VERSION "HNPBNYYYYYYYYYYYYYYYYYYYYYYYYYYYNNNNNNNNNN/4/%%/4/'%**4NNN///"

NS_ :

BS_:

BU_: ADL Aux_Device CANLogger CTU Central CentralMulti OffboardUDS Predecessor_Node RDC Radar SensorCANopen Simulator TEPM TIM TPMS iTEPM

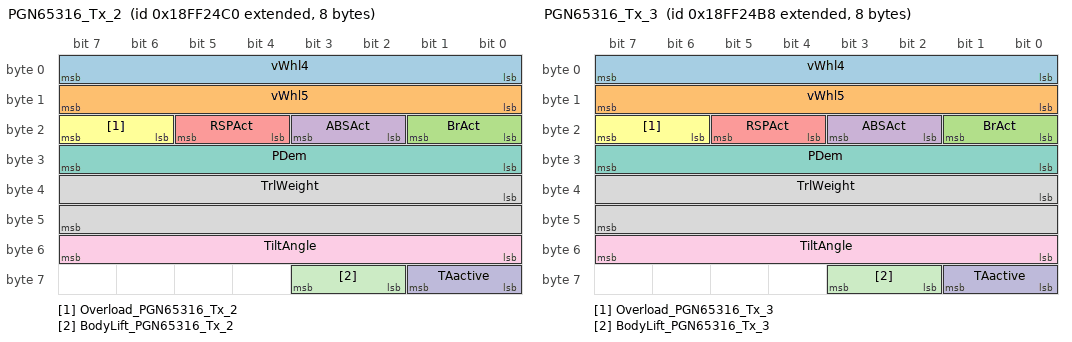
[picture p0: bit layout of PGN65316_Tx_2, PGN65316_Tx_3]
BO_ 2566857920 PGN65316_Tx_2 :8 CentralMulti
 SG_ vWhl4 : 0|8@1+ (1,0) [0|255] "km/h" Vector__XXX
 SG_ vWhl5 : 8|8@1+ (1,0) [0|255] "km/h" Vector__XXX
 SG_ BrAct : 16|2@1+ (1,0) [0|3] "" Vector__XXX
 SG_ ABSAct : 18|2@1+ (1,0) [0|3] "" Vector__XXX
 SG_ RSPAct : 20|2@1+ (1,0) [0|3] "" Vector__XXX
 SG_ Overload_PGN65316_Tx_2 : 22|2@1+ (1,0) [0|3] "" Vector__XXX
 SG_ PDem : 24|8@1+ (100,0) [0|255] "mbar" Vector__XXX
 SG_ TrlWeight : 32|16@1+ (2,0) [0|65535] "kg" Vector__XXX
 SG_ TiltAngle : 48|8@1+ (0.1,0) [0|255] "deg" Vector__XXX
 SG_ TAactive : 56|2@1+ (1,0) [0|3] "" Vector__XXX
 SG_ BodyLift_PGN65316_Tx_2 : 58|2@1+ (1,0) [0|3] "" Vector__XXX

BO_ 2566857912 PGN65316_Tx_3 :8 CentralMulti
 SG_ vWhl4 : 0|8@1+ (1,0) [0|255] "km/h" Vector__XXX
 SG_ vWhl5 : 8|8@1+ (1,0) [0|255] "km/h" Vector__XXX
 SG_ BrAct : 16|2@1+ (1,0) [0|3] "" Vector__XXX
 SG_ ABSAct : 18|2@1+ (1,0) [0|3] "" Vector__XXX
 SG_ RSPAct : 20|2@1+ (1,0) [0|3] "" Vector__XXX
 SG_ Overload_PGN65316_Tx_3 : 22|2@1+ (1,0) [0|3] "" Vector__XXX
 SG_ PDem : 24|8@1+ (100,0) [0|255] "mbar" Vector__XXX
 SG_ TrlWeight : 32|16@1+ (2,0) [0|65535] "kg" Vector__XXX
 SG_ TiltAngle : 48|8@1+ (0.1,0) [0|255] "deg" Vector__XXX
 SG_ TAactive : 56|2@1+ (1,0) [0|3] "" Vector__XXX
 SG_ BodyLift_PGN65316_Tx_3 : 58|2@1+ (1,0) [0|3] "" Vector__XXX

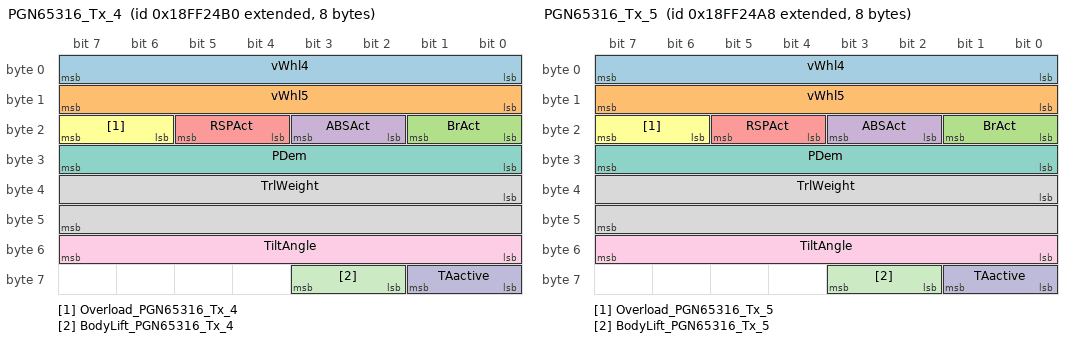
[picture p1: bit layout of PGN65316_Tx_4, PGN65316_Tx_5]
BO_ 2566857904 PGN65316_Tx_4 :8 CentralMulti
 SG_ vWhl4 : 0|8@1+ (1,0) [0|255] "km/h" Vector__XXX
 SG_ vWhl5 : 8|8@1+ (1,0) [0|255] "km/h" Vector__XXX
 SG_ BrAct : 16|2@1+ (1,0) [0|3] "" Vector__XXX
 SG_ ABSAct : 18|2@1+ (1,0) [0|3] "" Vector__XXX
 SG_ RSPAct : 20|2@1+ (1,0) [0|3] "" Vector__XXX
 SG_ Overload_PGN65316_Tx_4 : 22|2@1+ (1,0) [0|3] "" Vector__XXX
 SG_ PDem : 24|8@1+ (100,0) [0|255] "mbar" Vector__XXX
 SG_ TrlWeight : 32|16@1+ (2,0) [0|65535] "kg" Vector__XXX
 SG_ TiltAngle : 48|8@1+ (0.1,0) [0|255] "deg" Vector__XXX
 SG_ TAactive : 56|2@1+ (1,0) [0|3] "" Vector__XXX
 SG_ BodyLift_PGN65316_Tx_4 : 58|2@1+ (1,0) [0|3] "" Vector__XXX

BO_ 2566857896 PGN65316_Tx_5 :8 CentralMulti
 SG_ vWhl4 : 0|8@1+ (1,0) [0|255] "km/h" Vector__XXX
 SG_ vWhl5 : 8|8@1+ (1,0) [0|255] "km/h" Vector__XXX
 SG_ BrAct : 16|2@1+ (1,0) [0|3] "" Vector__XXX
 SG_ ABSAct : 18|2@1+ (1,0) [0|3] "" Vector__XXX
 SG_ RSPAct : 20|2@1+ (1,0) [0|3] "" Vector__XXX
 SG_ Overload_PGN65316_Tx_5 : 22|2@1+ (1,0) [0|3] "" Vector__XXX
 SG_ PDem : 24|8@1+ (100,0) [0|255] "mbar" Vector__XXX
 SG_ TrlWeight : 32|16@1+ (2,0) [0|65535] "kg" Vector__XXX
 SG_ TiltAngle : 48|8@1+ (0.1,0) [0|255] "deg" Vector__XXX
 SG_ TAactive : 56|2@1+ (1,0) [0|3] "" Vector__XXX
 SG_ BodyLift_PGN65316_Tx_5 : 58|2@1+ (1,0) [0|3] "" Vector__XXX

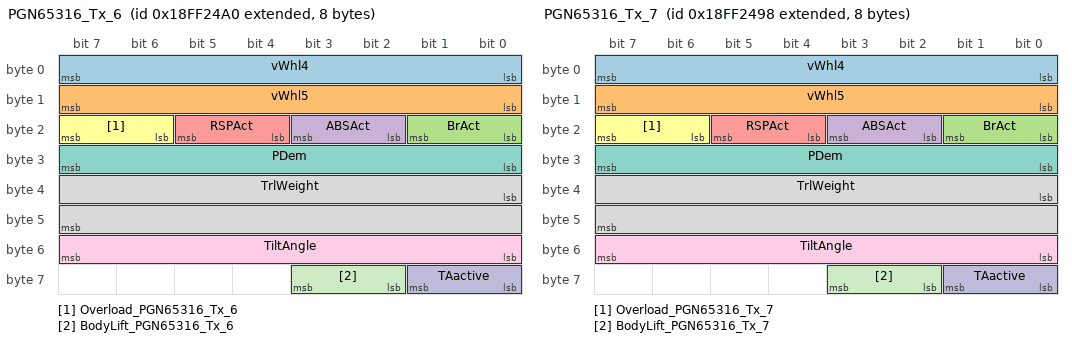
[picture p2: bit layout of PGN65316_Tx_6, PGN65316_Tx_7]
BO_ 2566857888 PGN65316_Tx_6 :8 CentralMulti
 SG_ vWhl4 : 0|8@1+ (1,0) [0|255] "km/h" Vector__XXX
 SG_ vWhl5 : 8|8@1+ (1,0) [0|255] "km/h" Vector__XXX
 SG_ BrAct : 16|2@1+ (1,0) [0|3] "" Vector__XXX
 SG_ ABSAct : 18|2@1+ (1,0) [0|3] "" Vector__XXX
 SG_ RSPAct : 20|2@1+ (1,0) [0|3] "" Vector__XXX
 SG_ Overload_PGN65316_Tx_6 : 22|2@1+ (1,0) [0|3] "" Vector__XXX
 SG_ PDem : 24|8@1+ (100,0) [0|255] "mbar" Vector__XXX
 SG_ TrlWeight : 32|16@1+ (2,0) [0|65535] "kg" Vector__XXX
 SG_ TiltAngle : 48|8@1+ (0.1,0) [0|255] "deg" Vector__XXX
 SG_ TAactive : 56|2@1+ (1,0) [0|3] "" Vector__XXX
 SG_ BodyLift_PGN65316_Tx_6 : 58|2@1+ (1,0) [0|3] "" Vector__XXX

BO_ 2566857880 PGN65316_Tx_7 :8 CentralMulti
 SG_ vWhl4 : 0|8@1+ (1,0) [0|255] "km/h" Vector__XXX
 SG_ vWhl5 : 8|8@1+ (1,0) [0|255] "km/h" Vector__XXX
 SG_ BrAct : 16|2@1+ (1,0) [0|3] "" Vector__XXX
 SG_ ABSAct : 18|2@1+ (1,0) [0|3] "" Vector__XXX
 SG_ RSPAct : 20|2@1+ (1,0) [0|3] "" Vector__XXX
 SG_ Overload_PGN65316_Tx_7 : 22|2@1+ (1,0) [0|3] "" Vector__XXX
 SG_ PDem : 24|8@1+ (100,0) [0|255] "mbar" Vector__XXX
 SG_ TrlWeight : 32|16@1+ (2,0) [0|65535] "kg" Vector__XXX
 SG_ TiltAngle : 48|8@1+ (0.1,0) [0|255] "deg" Vector__XXX
 SG_ TAactive : 56|2@1+ (1,0) [0|3] "" Vector__XXX
 SG_ BodyLift_PGN65316_Tx_7 : 58|2@1+ (1,0) [0|3] "" Vector__XXX

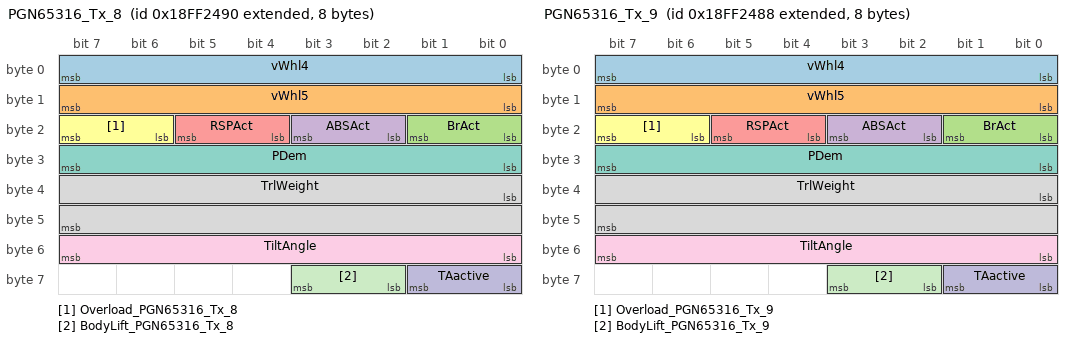
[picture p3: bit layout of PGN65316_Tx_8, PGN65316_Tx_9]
BO_ 2566857872 PGN65316_Tx_8 :8 CentralMulti
 SG_ vWhl4 : 0|8@1+ (1,0) [0|255] "km/h" Vector__XXX
 SG_ vWhl5 : 8|8@1+ (1,0) [0|255] "km/h" Vector__XXX
 SG_ BrAct : 16|2@1+ (1,0) [0|3] "" Vector__XXX
 SG_ ABSAct : 18|2@1+ (1,0) [0|3] "" Vector__XXX
 SG_ RSPAct : 20|2@1+ (1,0) [0|3] "" Vector__XXX
 SG_ Overload_PGN65316_Tx_8 : 22|2@1+ (1,0) [0|3] "" Vector__XXX
 SG_ PDem : 24|8@1+ (100,0) [0|255] "mbar" Vector__XXX
 SG_ TrlWeight : 32|16@1+ (2,0) [0|65535] "kg" Vector__XXX
 SG_ TiltAngle : 48|8@1+ (0.1,0) [0|255] "deg" Vector__XXX
 SG_ TAactive : 56|2@1+ (1,0) [0|3] "" Vector__XXX
 SG_ BodyLift_PGN65316_Tx_8 : 58|2@1+ (1,0) [0|3] "" Vector__XXX

BO_ 2566857864 PGN65316_Tx_9 :8 CentralMulti
 SG_ vWhl4 : 0|8@1+ (1,0) [0|255] "km/h" Vector__XXX
 SG_ vWhl5 : 8|8@1+ (1,0) [0|255] "km/h" Vector__XXX
 SG_ BrAct : 16|2@1+ (1,0) [0|3] "" Vector__XXX
 SG_ ABSAct : 18|2@1+ (1,0) [0|3] "" Vector__XXX
 SG_ RSPAct : 20|2@1+ (1,0) [0|3] "" Vector__XXX
 SG_ Overload_PGN65316_Tx_9 : 22|2@1+ (1,0) [0|3] "" Vector__XXX
 SG_ PDem : 24|8@1+ (100,0) [0|255] "mbar" Vector__XXX
 SG_ TrlWeight : 32|16@1+ (2,0) [0|65535] "kg" Vector__XXX
 SG_ TiltAngle : 48|8@1+ (0.1,0) [0|255] "deg" Vector__XXX
 SG_ TAactive : 56|2@1+ (1,0) [0|3] "" Vector__XXX
 SG_ BodyLift_PGN65316_Tx_9 : 58|2@1+ (1,0) [0|3] "" Vector__XXX

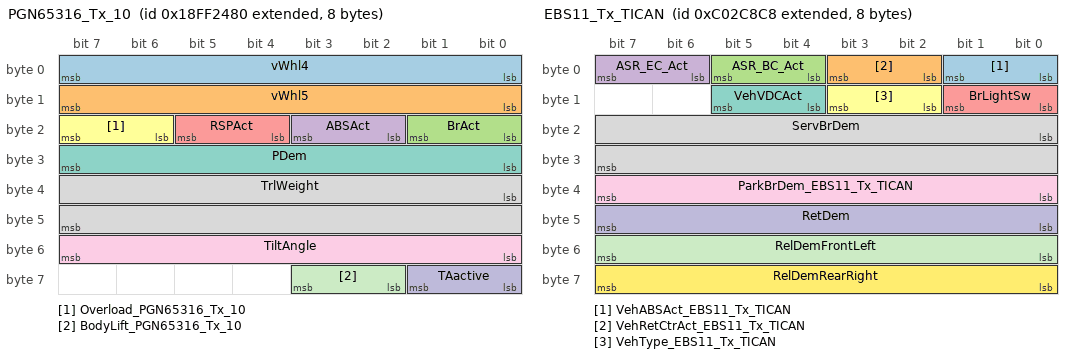
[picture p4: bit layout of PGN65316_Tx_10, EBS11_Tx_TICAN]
BO_ 2566857856 PGN65316_Tx_10 :8 CentralMulti
 SG_ vWhl4 : 0|8@1+ (1,0) [0|255] "km/h" Vector__XXX
 SG_ vWhl5 : 8|8@1+ (1,0) [0|255] "km/h" Vector__XXX
 SG_ BrAct : 16|2@1+ (1,0) [0|3] "" Vector__XXX
 SG_ ABSAct : 18|2@1+ (1,0) [0|3] "" Vector__XXX
 SG_ RSPAct : 20|2@1+ (1,0) [0|3] "" Vector__XXX
 SG_ Overload_PGN65316_Tx_10 : 22|2@1+ (1,0) [0|3] "" Vector__XXX
 SG_ PDem : 24|8@1+ (100,0) [0|255] "mbar" Vector__XXX
 SG_ TrlWeight : 32|16@1+ (2,0) [0|65535] "kg" Vector__XXX
 SG_ TiltAngle : 48|8@1+ (0.1,0) [0|255] "deg" Vector__XXX
 SG_ TAactive : 56|2@1+ (1,0) [0|3] "" Vector__XXX
 SG_ BodyLift_PGN65316_Tx_10 : 58|2@1+ (1,0) [0|3] "" Vector__XXX

BO_ 2348992712 EBS11_Tx_TICAN :8 Central
 SG_ VehABSAct_EBS11_Tx_TICAN : 0|2@1+ (1,0) [0|3] "" Vector__XXX
 SG_ VehRetCtrAct_EBS11_Tx_TICAN : 2|2@1+ (1,0) [0|3] "" Vector__XXX
 SG_ ASR_BC_Act : 4|2@1+ (1,0) [0|3] "" Vector__XXX
 SG_ ASR_EC_Act : 6|2@1+ (1,0) [0|3] "" Vector__XXX
 SG_ BrLightSw : 8|2@1+ (1,0) [0|3] "" Vector__XXX
 SG_ VehType_EBS11_Tx_TICAN : 10|2@1+ (1,0) [0|3] "" Vector__XXX
 SG_ VehVDCAct : 12|2@1+ (1,0) [0|3] "" Vector__XXX
 SG_ ServBrDem : 16|16@1+ (0.01953125,0) [0|65535] "kPa" Vector__XXX
 SG_ ParkBrDem_EBS11_Tx_TICAN : 32|8@1+ (0.4,0) [0|255] "%" Vector__XXX
 SG_ RetDem : 40|8@1+ (1,0) [0|255] "%" Vector__XXX
 SG_ RelDemFrontLeft : 48|8@1+ (0.4,0) [0|255] "%" Vector__XXX
 SG_ RelDemRearRight : 56|8@1+ (0.4,0) [0|255] "%" Vector__XXX

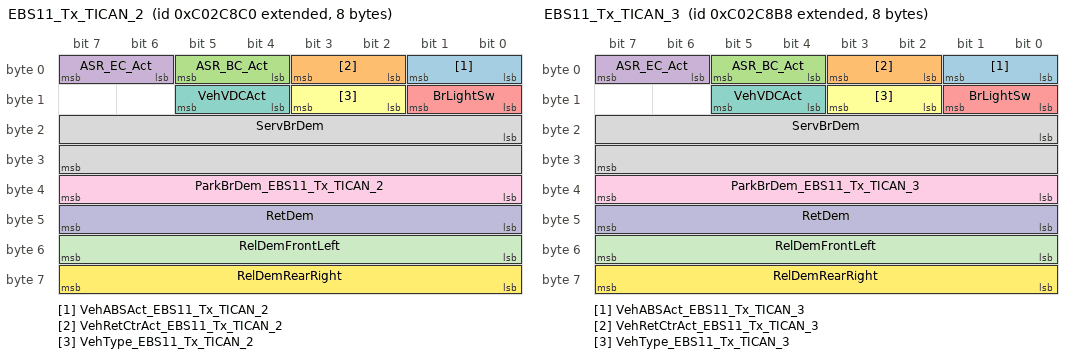
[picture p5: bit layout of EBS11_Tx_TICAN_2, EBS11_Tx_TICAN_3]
BO_ 2348992704 EBS11_Tx_TICAN_2 :8 CentralMulti
 SG_ VehABSAct_EBS11_Tx_TICAN_2 : 0|2@1+ (1,0) [0|3] "" Vector__XXX
 SG_ VehRetCtrAct_EBS11_Tx_TICAN_2 : 2|2@1+ (1,0) [0|3] "" Vector__XXX
 SG_ ASR_BC_Act : 4|2@1+ (1,0) [0|3] "" Vector__XXX
 SG_ ASR_EC_Act : 6|2@1+ (1,0) [0|3] "" Vector__XXX
 SG_ BrLightSw : 8|2@1+ (1,0) [0|3] "" Vector__XXX
 SG_ VehType_EBS11_Tx_TICAN_2 : 10|2@1+ (1,0) [0|3] "" Vector__XXX
 SG_ VehVDCAct : 12|2@1+ (1,0) [0|3] "" Vector__XXX
 SG_ ServBrDem : 16|16@1+ (0.01953125,0) [0|65535] "kPa" Vector__XXX
 SG_ ParkBrDem_EBS11_Tx_TICAN_2 : 32|8@1+ (0.4,0) [0|255] "%" Vector__XXX
 SG_ RetDem : 40|8@1+ (1,0) [0|255] "%" Vector__XXX
 SG_ RelDemFrontLeft : 48|8@1+ (0.4,0) [0|255] "%" Vector__XXX
 SG_ RelDemRearRight : 56|8@1+ (0.4,0) [0|255] "%" Vector__XXX

BO_ 2348992696 EBS11_Tx_TICAN_3 :8 CentralMulti
 SG_ VehABSAct_EBS11_Tx_TICAN_3 : 0|2@1+ (1,0) [0|3] "" Vector__XXX
 SG_ VehRetCtrAct_EBS11_Tx_TICAN_3 : 2|2@1+ (1,0) [0|3] "" Vector__XXX
 SG_ ASR_BC_Act : 4|2@1+ (1,0) [0|3] "" Vector__XXX
 SG_ ASR_EC_Act : 6|2@1+ (1,0) [0|3] "" Vector__XXX
 SG_ BrLightSw : 8|2@1+ (1,0) [0|3] "" Vector__XXX
 SG_ VehType_EBS11_Tx_TICAN_3 : 10|2@1+ (1,0) [0|3] "" Vector__XXX
 SG_ VehVDCAct : 12|2@1+ (1,0) [0|3] "" Vector__XXX
 SG_ ServBrDem : 16|16@1+ (0.01953125,0) [0|65535] "kPa" Vector__XXX
 SG_ ParkBrDem_EBS11_Tx_TICAN_3 : 32|8@1+ (0.4,0) [0|255] "%" Vector__XXX
 SG_ RetDem : 40|8@1+ (1,0) [0|255] "%" Vector__XXX
 SG_ RelDemFrontLeft : 48|8@1+ (0.4,0) [0|255] "%" Vector__XXX
 SG_ RelDemRearRight : 56|8@1+ (0.4,0) [0|255] "%" Vector__XXX

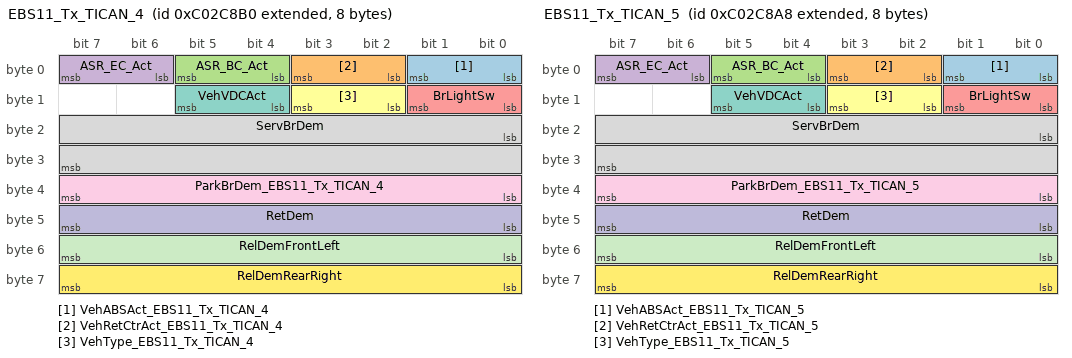
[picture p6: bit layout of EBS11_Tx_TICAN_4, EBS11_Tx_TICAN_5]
BO_ 2348992688 EBS11_Tx_TICAN_4 :8 CentralMulti
 SG_ VehABSAct_EBS11_Tx_TICAN_4 : 0|2@1+ (1,0) [0|3] "" Vector__XXX
 SG_ VehRetCtrAct_EBS11_Tx_TICAN_4 : 2|2@1+ (1,0) [0|3] "" Vector__XXX
 SG_ ASR_BC_Act : 4|2@1+ (1,0) [0|3] "" Vector__XXX
 SG_ ASR_EC_Act : 6|2@1+ (1,0) [0|3] "" Vector__XXX
 SG_ BrLightSw : 8|2@1+ (1,0) [0|3] "" Vector__XXX
 SG_ VehType_EBS11_Tx_TICAN_4 : 10|2@1+ (1,0) [0|3] "" Vector__XXX
 SG_ VehVDCAct : 12|2@1+ (1,0) [0|3] "" Vector__XXX
 SG_ ServBrDem : 16|16@1+ (0.01953125,0) [0|65535] "kPa" Vector__XXX
 SG_ ParkBrDem_EBS11_Tx_TICAN_4 : 32|8@1+ (0.4,0) [0|255] "%" Vector__XXX
 SG_ RetDem : 40|8@1+ (1,0) [0|255] "%" Vector__XXX
 SG_ RelDemFrontLeft : 48|8@1+ (0.4,0) [0|255] "%" Vector__XXX
 SG_ RelDemRearRight : 56|8@1+ (0.4,0) [0|255] "%" Vector__XXX

BO_ 2348992680 EBS11_Tx_TICAN_5 :8 CentralMulti
 SG_ VehABSAct_EBS11_Tx_TICAN_5 : 0|2@1+ (1,0) [0|3] "" Vector__XXX
 SG_ VehRetCtrAct_EBS11_Tx_TICAN_5 : 2|2@1+ (1,0) [0|3] "" Vector__XXX
 SG_ ASR_BC_Act : 4|2@1+ (1,0) [0|3] "" Vector__XXX
 SG_ ASR_EC_Act : 6|2@1+ (1,0) [0|3] "" Vector__XXX
 SG_ BrLightSw : 8|2@1+ (1,0) [0|3] "" Vector__XXX
 SG_ VehType_EBS11_Tx_TICAN_5 : 10|2@1+ (1,0) [0|3] "" Vector__XXX
 SG_ VehVDCAct : 12|2@1+ (1,0) [0|3] "" Vector__XXX
 SG_ ServBrDem : 16|16@1+ (0.01953125,0) [0|65535] "kPa" Vector__XXX
 SG_ ParkBrDem_EBS11_Tx_TICAN_5 : 32|8@1+ (0.4,0) [0|255] "%" Vector__XXX
 SG_ RetDem : 40|8@1+ (1,0) [0|255] "%" Vector__XXX
 SG_ RelDemFrontLeft : 48|8@1+ (0.4,0) [0|255] "%" Vector__XXX
 SG_ RelDemRearRight : 56|8@1+ (0.4,0) [0|255] "%" Vector__XXX

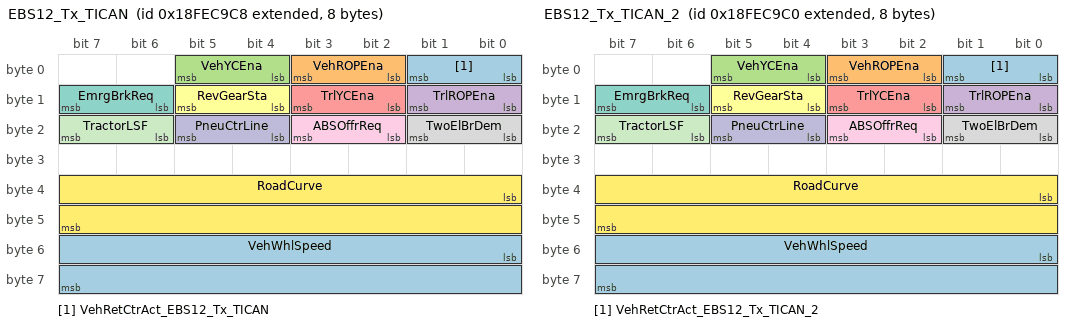
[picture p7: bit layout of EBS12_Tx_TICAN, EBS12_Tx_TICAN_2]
BO_ 2566834632 EBS12_Tx_TICAN :8 Central
 SG_ VehRetCtrAct_EBS12_Tx_TICAN : 0|2@1+ (1,0) [0|3] "" Vector__XXX
 SG_ VehROPEna : 2|2@1+ (1,0) [0|3] "" Vector__XXX
 SG_ VehYCEna : 4|2@1+ (1,0) [0|3] "" Vector__XXX
 SG_ TrlROPEna : 8|2@1+ (1,0) [0|3] "" Vector__XXX
 SG_ TrlYCEna : 10|2@1+ (1,0) [0|3] "" Vector__XXX
 SG_ RevGearSta : 12|2@1+ (1,0) [0|3] "" Vector__XXX
 SG_ EmrgBrkReq : 14|2@1+ (1,0) [0|3] "" Vector__XXX
 SG_ TwoElBrDem : 16|2@1+ (1,0) [0|3] "" Vector__XXX
 SG_ ABSOffrReq : 18|2@1+ (1,0) [0|3] "" Vector__XXX
 SG_ PneuCtrLine : 20|2@1+ (1,0) [0|3] "" Vector__XXX
 SG_ TractorLSF : 22|2@1+ (1,0) [0|3] "" Vector__XXX
 SG_ RoadCurve : 32|16@1+ (0.0078125,-250) [0|65535] "1/km" Vector__XXX
 SG_ VehWhlSpeed : 48|16@1+ (0.00390625,0) [0|65535] "km/h" Vector__XXX

BO_ 2566834624 EBS12_Tx_TICAN_2 :8 CentralMulti
 SG_ VehRetCtrAct_EBS12_Tx_TICAN_2 : 0|2@1+ (1,0) [0|3] "" Vector__XXX
 SG_ VehROPEna : 2|2@1+ (1,0) [0|3] "" Vector__XXX
 SG_ VehYCEna : 4|2@1+ (1,0) [0|3] "" Vector__XXX
 SG_ TrlROPEna : 8|2@1+ (1,0) [0|3] "" Vector__XXX
 SG_ TrlYCEna : 10|2@1+ (1,0) [0|3] "" Vector__XXX
 SG_ RevGearSta : 12|2@1+ (1,0) [0|3] "" Vector__XXX
 SG_ EmrgBrkReq : 14|2@1+ (1,0) [0|3] "" Vector__XXX
 SG_ TwoElBrDem : 16|2@1+ (1,0) [0|3] "" Vector__XXX
 SG_ ABSOffrReq : 18|2@1+ (1,0) [0|3] "" Vector__XXX
 SG_ PneuCtrLine : 20|2@1+ (1,0) [0|3] "" Vector__XXX
 SG_ TractorLSF : 22|2@1+ (1,0) [0|3] "" Vector__XXX
 SG_ RoadCurve : 32|16@1+ (0.0078125,-250) [0|65535] "1/km" Vector__XXX
 SG_ VehWhlSpeed : 48|16@1+ (0.00390625,0) [0|65535] "km/h" Vector__XXX

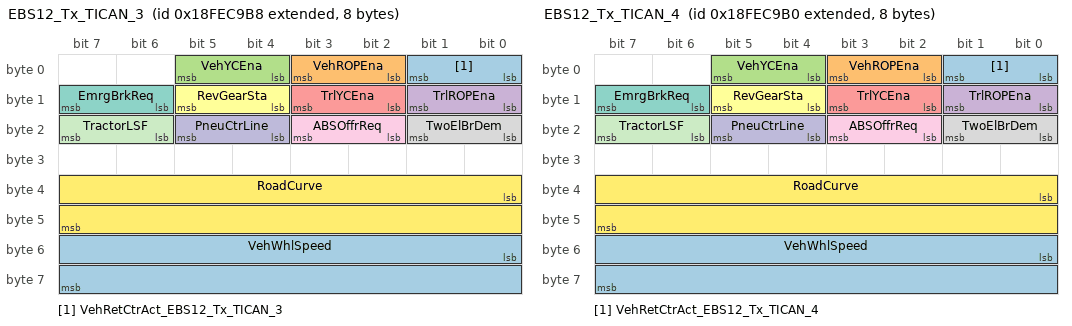
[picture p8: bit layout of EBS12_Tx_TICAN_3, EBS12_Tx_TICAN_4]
BO_ 2566834616 EBS12_Tx_TICAN_3 :8 CentralMulti
 SG_ VehRetCtrAct_EBS12_Tx_TICAN_3 : 0|2@1+ (1,0) [0|3] "" Vector__XXX
 SG_ VehROPEna : 2|2@1+ (1,0) [0|3] "" Vector__XXX
 SG_ VehYCEna : 4|2@1+ (1,0) [0|3] "" Vector__XXX
 SG_ TrlROPEna : 8|2@1+ (1,0) [0|3] "" Vector__XXX
 SG_ TrlYCEna : 10|2@1+ (1,0) [0|3] "" Vector__XXX
 SG_ RevGearSta : 12|2@1+ (1,0) [0|3] "" Vector__XXX
 SG_ EmrgBrkReq : 14|2@1+ (1,0) [0|3] "" Vector__XXX
 SG_ TwoElBrDem : 16|2@1+ (1,0) [0|3] "" Vector__XXX
 SG_ ABSOffrReq : 18|2@1+ (1,0) [0|3] "" Vector__XXX
 SG_ PneuCtrLine : 20|2@1+ (1,0) [0|3] "" Vector__XXX
 SG_ TractorLSF : 22|2@1+ (1,0) [0|3] "" Vector__XXX
 SG_ RoadCurve : 32|16@1+ (0.0078125,-250) [0|65535] "1/km" Vector__XXX
 SG_ VehWhlSpeed : 48|16@1+ (0.00390625,0) [0|65535] "km/h" Vector__XXX

BO_ 2566834608 EBS12_Tx_TICAN_4 :8 CentralMulti
 SG_ VehRetCtrAct_EBS12_Tx_TICAN_4 : 0|2@1+ (1,0) [0|3] "" Vector__XXX
 SG_ VehROPEna : 2|2@1+ (1,0) [0|3] "" Vector__XXX
 SG_ VehYCEna : 4|2@1+ (1,0) [0|3] "" Vector__XXX
 SG_ TrlROPEna : 8|2@1+ (1,0) [0|3] "" Vector__XXX
 SG_ TrlYCEna : 10|2@1+ (1,0) [0|3] "" Vector__XXX
 SG_ RevGearSta : 12|2@1+ (1,0) [0|3] "" Vector__XXX
 SG_ EmrgBrkReq : 14|2@1+ (1,0) [0|3] "" Vector__XXX
 SG_ TwoElBrDem : 16|2@1+ (1,0) [0|3] "" Vector__XXX
 SG_ ABSOffrReq : 18|2@1+ (1,0) [0|3] "" Vector__XXX
 SG_ PneuCtrLine : 20|2@1+ (1,0) [0|3] "" Vector__XXX
 SG_ TractorLSF : 22|2@1+ (1,0) [0|3] "" Vector__XXX
 SG_ RoadCurve : 32|16@1+ (0.0078125,-250) [0|65535] "1/km" Vector__XXX
 SG_ VehWhlSpeed : 48|16@1+ (0.00390625,0) [0|65535] "km/h" Vector__XXX

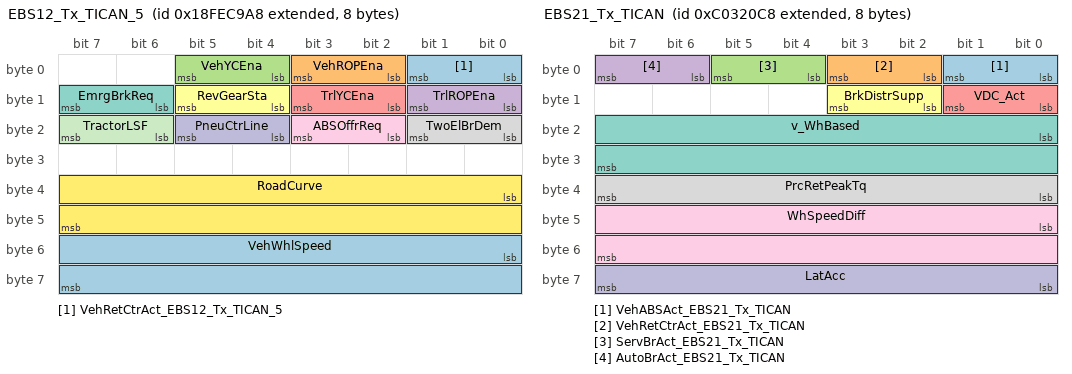
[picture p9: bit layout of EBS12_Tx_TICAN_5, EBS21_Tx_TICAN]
BO_ 2566834600 EBS12_Tx_TICAN_5 :8 CentralMulti
 SG_ VehRetCtrAct_EBS12_Tx_TICAN_5 : 0|2@1+ (1,0) [0|3] "" Vector__XXX
 SG_ VehROPEna : 2|2@1+ (1,0) [0|3] "" Vector__XXX
 SG_ VehYCEna : 4|2@1+ (1,0) [0|3] "" Vector__XXX
 SG_ TrlROPEna : 8|2@1+ (1,0) [0|3] "" Vector__XXX
 SG_ TrlYCEna : 10|2@1+ (1,0) [0|3] "" Vector__XXX
 SG_ RevGearSta : 12|2@1+ (1,0) [0|3] "" Vector__XXX
 SG_ EmrgBrkReq : 14|2@1+ (1,0) [0|3] "" Vector__XXX
 SG_ TwoElBrDem : 16|2@1+ (1,0) [0|3] "" Vector__XXX
 SG_ ABSOffrReq : 18|2@1+ (1,0) [0|3] "" Vector__XXX
 SG_ PneuCtrLine : 20|2@1+ (1,0) [0|3] "" Vector__XXX
 SG_ TractorLSF : 22|2@1+ (1,0) [0|3] "" Vector__XXX
 SG_ RoadCurve : 32|16@1+ (0.0078125,-250) [0|65535] "1/km" Vector__XXX
 SG_ VehWhlSpeed : 48|16@1+ (0.00390625,0) [0|65535] "km/h" Vector__XXX

BO_ 2349015240 EBS21_Tx_TICAN :8 Central
 SG_ VehABSAct_EBS21_Tx_TICAN : 0|2@1+ (1,0) [0|3] "" Vector__XXX
 SG_ VehRetCtrAct_EBS21_Tx_TICAN : 2|2@1+ (1,0) [0|3] "" Vector__XXX
 SG_ ServBrAct_EBS21_Tx_TICAN : 4|2@1+ (1,0) [0|3] "" Vector__XXX
 SG_ AutoBrAct_EBS21_Tx_TICAN : 6|2@1+ (1,0) [0|3] "" Vector__XXX
 SG_ VDC_Act : 8|2@1+ (1,0) [0|3] "" Vector__XXX
 SG_ BrkDistrSupp : 10|2@1+ (1,0) [0|3] "" Vector__XXX
 SG_ v_WhBased : 16|16@1+ (0.00390625,0) [0|65535] "km/h" Vector__XXX
 SG_ PrcRetPeakTq : 32|8@1+ (1,-125) [0|255] "%" Vector__XXX
 SG_ WhSpeedDiff : 40|16@1+ (0.00390625,-125) [0|65535] "km/h" Vector__XXX
 SG_ LatAcc : 56|8@1+ (0.1,-12.5) [0|255] "m/s2" Vector__XXX

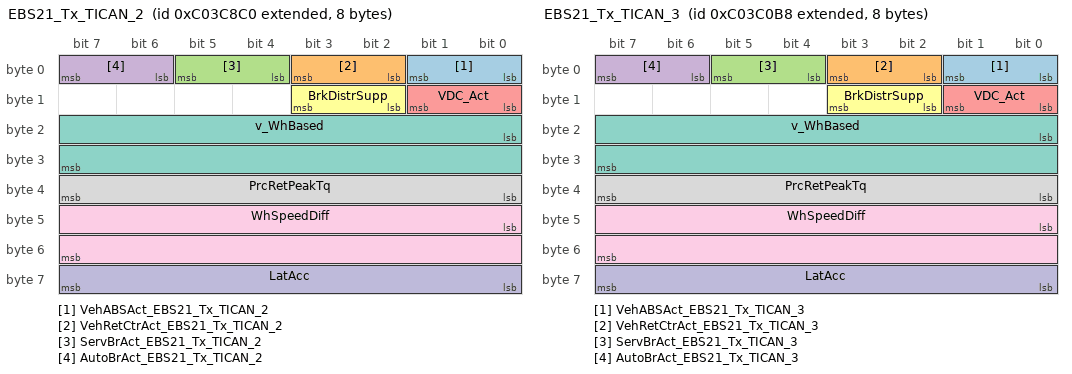
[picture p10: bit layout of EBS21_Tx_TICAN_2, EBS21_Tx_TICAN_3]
BO_ 2349058240 EBS21_Tx_TICAN_2 :8 CentralMulti
 SG_ VehABSAct_EBS21_Tx_TICAN_2 : 0|2@1+ (1,0) [0|3] "" Vector__XXX
 SG_ VehRetCtrAct_EBS21_Tx_TICAN_2 : 2|2@1+ (1,0) [0|3] "" Vector__XXX
 SG_ ServBrAct_EBS21_Tx_TICAN_2 : 4|2@1+ (1,0) [0|3] "" Vector__XXX
 SG_ AutoBrAct_EBS21_Tx_TICAN_2 : 6|2@1+ (1,0) [0|3] "" Vector__XXX
 SG_ VDC_Act : 8|2@1+ (1,0) [0|3] "" Vector__XXX
 SG_ BrkDistrSupp : 10|2@1+ (1,0) [0|3] "" Vector__XXX
 SG_ v_WhBased : 16|16@1+ (0.00390625,0) [0|65535] "km/h" Vector__XXX
 SG_ PrcRetPeakTq : 32|8@1+ (1,-125) [0|255] "%" Vector__XXX
 SG_ WhSpeedDiff : 40|16@1+ (0.00390625,-125) [0|65535] "km/h" Vector__XXX
 SG_ LatAcc : 56|8@1+ (0.1,-12.5) [0|255] "m/s2" Vector__XXX

BO_ 2349056184 EBS21_Tx_TICAN_3 :8 CentralMulti
 SG_ VehABSAct_EBS21_Tx_TICAN_3 : 0|2@1+ (1,0) [0|3] "" Vector__XXX
 SG_ VehRetCtrAct_EBS21_Tx_TICAN_3 : 2|2@1+ (1,0) [0|3] "" Vector__XXX
 SG_ ServBrAct_EBS21_Tx_TICAN_3 : 4|2@1+ (1,0) [0|3] "" Vector__XXX
 SG_ AutoBrAct_EBS21_Tx_TICAN_3 : 6|2@1+ (1,0) [0|3] "" Vector__XXX
 SG_ VDC_Act : 8|2@1+ (1,0) [0|3] "" Vector__XXX
 SG_ BrkDistrSupp : 10|2@1+ (1,0) [0|3] "" Vector__XXX
 SG_ v_WhBased : 16|16@1+ (0.00390625,0) [0|65535] "km/h" Vector__XXX
 SG_ PrcRetPeakTq : 32|8@1+ (1,-125) [0|255] "%" Vector__XXX
 SG_ WhSpeedDiff : 40|16@1+ (0.00390625,-125) [0|65535] "km/h" Vector__XXX
 SG_ LatAcc : 56|8@1+ (0.1,-12.5) [0|255] "m/s2" Vector__XXX

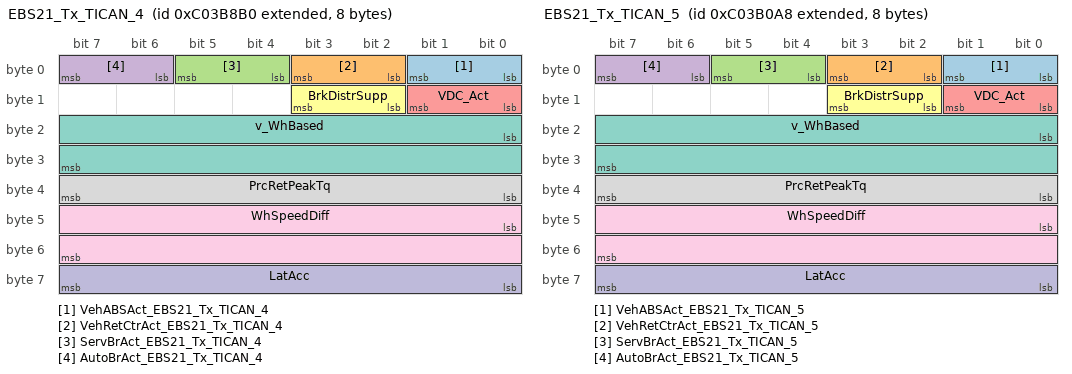
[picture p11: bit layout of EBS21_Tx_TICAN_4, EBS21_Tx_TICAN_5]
BO_ 2349054128 EBS21_Tx_TICAN_4 :8 CentralMulti
 SG_ VehABSAct_EBS21_Tx_TICAN_4 : 0|2@1+ (1,0) [0|3] "" Vector__XXX
 SG_ VehRetCtrAct_EBS21_Tx_TICAN_4 : 2|2@1+ (1,0) [0|3] "" Vector__XXX
 SG_ ServBrAct_EBS21_Tx_TICAN_4 : 4|2@1+ (1,0) [0|3] "" Vector__XXX
 SG_ AutoBrAct_EBS21_Tx_TICAN_4 : 6|2@1+ (1,0) [0|3] "" Vector__XXX
 SG_ VDC_Act : 8|2@1+ (1,0) [0|3] "" Vector__XXX
 SG_ BrkDistrSupp : 10|2@1+ (1,0) [0|3] "" Vector__XXX
 SG_ v_WhBased : 16|16@1+ (0.00390625,0) [0|65535] "km/h" Vector__XXX
 SG_ PrcRetPeakTq : 32|8@1+ (1,-125) [0|255] "%" Vector__XXX
 SG_ WhSpeedDiff : 40|16@1+ (0.00390625,-125) [0|65535] "km/h" Vector__XXX
 SG_ LatAcc : 56|8@1+ (0.1,-12.5) [0|255] "m/s2" Vector__XXX

BO_ 2349052072 EBS21_Tx_TICAN_5 :8 CentralMulti
 SG_ VehABSAct_EBS21_Tx_TICAN_5 : 0|2@1+ (1,0) [0|3] "" Vector__XXX
 SG_ VehRetCtrAct_EBS21_Tx_TICAN_5 : 2|2@1+ (1,0) [0|3] "" Vector__XXX
 SG_ ServBrAct_EBS21_Tx_TICAN_5 : 4|2@1+ (1,0) [0|3] "" Vector__XXX
 SG_ AutoBrAct_EBS21_Tx_TICAN_5 : 6|2@1+ (1,0) [0|3] "" Vector__XXX
 SG_ VDC_Act : 8|2@1+ (1,0) [0|3] "" Vector__XXX
 SG_ BrkDistrSupp : 10|2@1+ (1,0) [0|3] "" Vector__XXX
 SG_ v_WhBased : 16|16@1+ (0.00390625,0) [0|65535] "km/h" Vector__XXX
 SG_ PrcRetPeakTq : 32|8@1+ (1,-125) [0|255] "%" Vector__XXX
 SG_ WhSpeedDiff : 40|16@1+ (0.00390625,-125) [0|65535] "km/h" Vector__XXX
 SG_ LatAcc : 56|8@1+ (0.1,-12.5) [0|255] "m/s2" Vector__XXX

BO_ 2566833352 EBS22_Tx_TICAN :8 Central
 SG_ VehABSAct_EBS22_Tx_TICAN : 0|2@1+ (1,0) [0|3] "" Vector__XXX
 SG_ VehRetCtrAct_EBS22_Tx_TICAN : 2|2@1+ (1,0) [0|3] "" Vector__XXX
 SG_ ServBrAct_EBS22_Tx_TICAN : 4|2@1+ (1,0) [0|3] "" Vector__XXX
 SG_ AutoBrAct_EBS22_Tx_TICAN : 6|2@1+ (1,0) [0|3] "" Vector__XXX
 SG_ ElSupSuff : 8|2@1+ (1,0) [0|3] "" Vector__XXX
 SG_ RedWLReq : 10|2@1+ (1,0) [0|3] "" Vector__XXX
 SG_ AmbWLReq : 12|2@1+ (1,0) [0|3] "" Vector__XXX
 SG_ ElSupNoBrSys : 14|2@1+ (1,0) [0|3] "" Vector__XXX
 SG_ SpringBrInst : 16|2@1+ (1,0) [0|3] "" Vector__XXX
 SG_ ElLoadProp : 18|2@1+ (1,0) [0|3] "" Vector__XXX
 SG_ VehType_EBS22_Tx_TICAN : 20|2@1+ (1,0) [0|3] "" Vector__XXX
 SG_ SprBrEng : 22|2@1+ (1,0) [0|3] "" Vector__XXX
 SG_ LoadRampAss : 24|2@1+ (1,0) [0|3] "" Vector__XXX
 SG_ SupBrReq : 26|2@1+ (1,0) [0|3] "" Vector__XXX
 SG_ StopLampReq : 28|2@1+ (1,0) [0|3] "" Vector__XXX
 SG_ ElBrakeSupp : 30|2@1+ (1,0) [0|3] "" Vector__XXX
 SG_ AxLoadSum : 32|16@1+ (2,0) [0|65535] "kg" Vector__XXX
 SG_ RefRetTrq : 48|16@1+ (1,0) [0|65535] "Nm" Vector__XXX

BO_ 2566833344 EBS22_Tx_TICAN_2 :8 CentralMulti
 SG_ VehABSAct_EBS22_Tx_TICAN_2 : 0|2@1+ (1,0) [0|3] "" Vector__XXX
 SG_ VehRetCtrAct_EBS22_Tx_TICAN_2 : 2|2@1+ (1,0) [0|3] "" Vector__XXX
 SG_ ServBrAct_EBS22_Tx_TICAN_2 : 4|2@1+ (1,0) [0|3] "" Vector__XXX
 SG_ AutoBrAct_EBS22_Tx_TICAN_2 : 6|2@1+ (1,0) [0|3] "" Vector__XXX
 SG_ ElSupSuff : 8|2@1+ (1,0) [0|3] "" Vector__XXX
 SG_ RedWLReq : 10|2@1+ (1,0) [0|3] "" Vector__XXX
 SG_ AmbWLReq : 12|2@1+ (1,0) [0|3] "" Vector__XXX
 SG_ ElSupNoBrSys : 14|2@1+ (1,0) [0|3] "" Vector__XXX
 SG_ SpringBrInst : 16|2@1+ (1,0) [0|3] "" Vector__XXX
 SG_ ElLoadProp : 18|2@1+ (1,0) [0|3] "" Vector__XXX
 SG_ VehType_EBS22_Tx_TICAN_2 : 20|2@1+ (1,0) [0|3] "" Vector__XXX
 SG_ SprBrEng : 22|2@1+ (1,0) [0|3] "" Vector__XXX
 SG_ LoadRampAss : 24|2@1+ (1,0) [0|3] "" Vector__XXX
 SG_ SupBrReq : 26|2@1+ (1,0) [0|3] "" Vector__XXX
 SG_ StopLampReq : 28|2@1+ (1,0) [0|3] "" Vector__XXX
 SG_ ElBrakeSupp : 30|2@1+ (1,0) [0|3] "" Vector__XXX
 SG_ AxLoadSum : 32|16@1+ (2,0) [0|65535] "kg" Vector__XXX
 SG_ RefRetTrq : 48|16@1+ (1,0) [0|65535] "Nm" Vector__XXX

BO_ 2566833336 EBS22_Tx_TICAN_3 :8 CentralMulti
 SG_ VehABSAct_EBS22_Tx_TICAN_3 : 0|2@1+ (1,0) [0|3] "" Vector__XXX
 SG_ VehRetCtrAct_EBS22_Tx_TICAN_3 : 2|2@1+ (1,0) [0|3] "" Vector__XXX
 SG_ ServBrAct_EBS22_Tx_TICAN_3 : 4|2@1+ (1,0) [0|3] "" Vector__XXX
 SG_ AutoBrAct_EBS22_Tx_TICAN_3 : 6|2@1+ (1,0) [0|3] "" Vector__XXX
 SG_ ElSupSuff : 8|2@1+ (1,0) [0|3] "" Vector__XXX
 SG_ RedWLReq : 10|2@1+ (1,0) [0|3] "" Vector__XXX
 SG_ AmbWLReq : 12|2@1+ (1,0) [0|3] "" Vector__XXX
 SG_ ElSupNoBrSys : 14|2@1+ (1,0) [0|3] "" Vector__XXX
 SG_ SpringBrInst : 16|2@1+ (1,0) [0|3] "" Vector__XXX
 SG_ ElLoadProp : 18|2@1+ (1,0) [0|3] "" Vector__XXX
 SG_ VehType_EBS22_Tx_TICAN_3 : 20|2@1+ (1,0) [0|3] "" Vector__XXX
 SG_ SprBrEng : 22|2@1+ (1,0) [0|3] "" Vector__XXX
 SG_ LoadRampAss : 24|2@1+ (1,0) [0|3] "" Vector__XXX
 SG_ SupBrReq : 26|2@1+ (1,0) [0|3] "" Vector__XXX
 SG_ StopLampReq : 28|2@1+ (1,0) [0|3] "" Vector__XXX
 SG_ ElBrakeSupp : 30|2@1+ (1,0) [0|3] "" Vector__XXX
 SG_ AxLoadSum : 32|16@1+ (2,0) [0|65535] "kg" Vector__XXX
 SG_ RefRetTrq : 48|16@1+ (1,0) [0|65535] "Nm" Vector__XXX

BO_ 2566833328 EBS22_Tx_TICAN_4 :8 CentralMulti
 SG_ VehABSAct_EBS22_Tx_TICAN_4 : 0|2@1+ (1,0) [0|3] "" Vector__XXX
 SG_ VehRetCtrAct_EBS22_Tx_TICAN_4 : 2|2@1+ (1,0) [0|3] "" Vector__XXX
 SG_ ServBrAct_EBS22_Tx_TICAN_4 : 4|2@1+ (1,0) [0|3] "" Vector__XXX
 SG_ AutoBrAct_EBS22_Tx_TICAN_4 : 6|2@1+ (1,0) [0|3] "" Vector__XXX
 SG_ ElSupSuff : 8|2@1+ (1,0) [0|3] "" Vector__XXX
 SG_ RedWLReq : 10|2@1+ (1,0) [0|3] "" Vector__XXX
 SG_ AmbWLReq : 12|2@1+ (1,0) [0|3] "" Vector__XXX
 SG_ ElSupNoBrSys : 14|2@1+ (1,0) [0|3] "" Vector__XXX
 SG_ SpringBrInst : 16|2@1+ (1,0) [0|3] "" Vector__XXX
 SG_ ElLoadProp : 18|2@1+ (1,0) [0|3] "" Vector__XXX
 SG_ VehType_EBS22_Tx_TICAN_4 : 20|2@1+ (1,0) [0|3] "" Vector__XXX
 SG_ SprBrEng : 22|2@1+ (1,0) [0|3] "" Vector__XXX
 SG_ LoadRampAss : 24|2@1+ (1,0) [0|3] "" Vector__XXX
 SG_ SupBrReq : 26|2@1+ (1,0) [0|3] "" Vector__XXX
 SG_ StopLampReq : 28|2@1+ (1,0) [0|3] "" Vector__XXX
 SG_ ElBrakeSupp : 30|2@1+ (1,0) [0|3] "" Vector__XXX
 SG_ AxLoadSum : 32|16@1+ (2,0) [0|65535] "kg" Vector__XXX
 SG_ RefRetTrq : 48|16@1+ (1,0) [0|65535] "Nm" Vector__XXX

BO_ 2566833320 EBS22_Tx_TICAN_5 :8 CentralMulti
 SG_ VehABSAct_EBS22_Tx_TICAN_5 : 0|2@1+ (1,0) [0|3] "" Vector__XXX
 SG_ VehRetCtrAct_EBS22_Tx_TICAN_5 : 2|2@1+ (1,0) [0|3] "" Vector__XXX
 SG_ ServBrAct_EBS22_Tx_TICAN_5 : 4|2@1+ (1,0) [0|3] "" Vector__XXX
 SG_ AutoBrAct_EBS22_Tx_TICAN_5 : 6|2@1+ (1,0) [0|3] "" Vector__XXX
 SG_ ElSupSuff : 8|2@1+ (1,0) [0|3] "" Vector__XXX
 SG_ RedWLReq : 10|2@1+ (1,0) [0|3] "" Vector__XXX
 SG_ AmbWLReq : 12|2@1+ (1,0) [0|3] "" Vector__XXX
 SG_ ElSupNoBrSys : 14|2@1+ (1,0) [0|3] "" Vector__XXX
 SG_ SpringBrInst : 16|2@1+ (1,0) [0|3] "" Vector__XXX
 SG_ ElLoadProp : 18|2@1+ (1,0) [0|3] "" Vector__XXX
 SG_ VehType_EBS22_Tx_TICAN_5 : 20|2@1+ (1,0) [0|3] "" Vector__XXX
 SG_ SprBrEng : 22|2@1+ (1,0) [0|3] "" Vector__XXX
 SG_ LoadRampAss : 24|2@1+ (1,0) [0|3] "" Vector__XXX
 SG_ SupBrReq : 26|2@1+ (1,0) [0|3] "" Vector__XXX
 SG_ StopLampReq : 28|2@1+ (1,0) [0|3] "" Vector__XXX
 SG_ ElBrakeSupp : 30|2@1+ (1,0) [0|3] "" Vector__XXX
 SG_ AxLoadSum : 32|16@1+ (2,0) [0|65535] "kg" Vector__XXX
 SG_ RefRetTrq : 48|16@1+ (1,0) [0|65535] "Nm" Vector__XXX

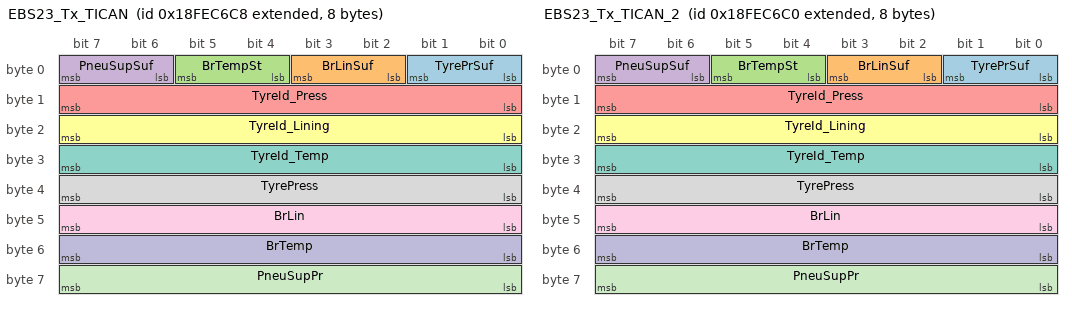
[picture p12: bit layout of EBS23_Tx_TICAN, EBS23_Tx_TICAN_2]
BO_ 2566833864 EBS23_Tx_TICAN :8 Central
 SG_ TyrePrSuf : 0|2@1+ (1,0) [0|3] "" Vector__XXX
 SG_ BrLinSuf : 2|2@1+ (1,0) [0|3] "" Vector__XXX
 SG_ BrTempSt : 4|2@1+ (1,0) [0|3] "" Vector__XXX
 SG_ PneuSupSuf : 6|2@1+ (1,0) [0|3] "" Vector__XXX
 SG_ TyreId_Press : 8|8@1+ (1,0) [0|255] "" Vector__XXX
 SG_ TyreId_Lining : 16|8@1+ (1,0) [0|255] "" Vector__XXX
 SG_ TyreId_Temp : 24|8@1+ (1,0) [0|255] "" Vector__XXX
 SG_ TyrePress : 32|8@1+ (10,0) [0|255] "kPa" Vector__XXX
 SG_ BrLin : 40|8@1+ (0.4,0) [0|255] "%" Vector__XXX
 SG_ BrTemp : 48|8@1+ (10,0) [0|255] "C" Vector__XXX
 SG_ PneuSupPr : 56|8@1+ (5,0) [0|255] "kPa" Vector__XXX

BO_ 2566833856 EBS23_Tx_TICAN_2 :8 CentralMulti
 SG_ TyrePrSuf : 0|2@1+ (1,0) [0|3] "" Vector__XXX
 SG_ BrLinSuf : 2|2@1+ (1,0) [0|3] "" Vector__XXX
 SG_ BrTempSt : 4|2@1+ (1,0) [0|3] "" Vector__XXX
 SG_ PneuSupSuf : 6|2@1+ (1,0) [0|3] "" Vector__XXX
 SG_ TyreId_Press : 8|8@1+ (1,0) [0|255] "" Vector__XXX
 SG_ TyreId_Lining : 16|8@1+ (1,0) [0|255] "" Vector__XXX
 SG_ TyreId_Temp : 24|8@1+ (1,0) [0|255] "" Vector__XXX
 SG_ TyrePress : 32|8@1+ (10,0) [0|255] "kPa" Vector__XXX
 SG_ BrLin : 40|8@1+ (0.4,0) [0|255] "%" Vector__XXX
 SG_ BrTemp : 48|8@1+ (10,0) [0|255] "C" Vector__XXX
 SG_ PneuSupPr : 56|8@1+ (5,0) [0|255] "kPa" Vector__XXX

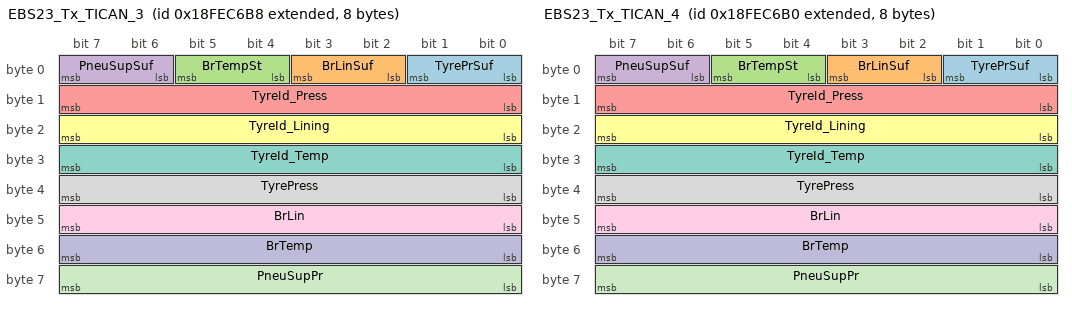
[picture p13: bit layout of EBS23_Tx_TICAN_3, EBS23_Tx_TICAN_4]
BO_ 2566833848 EBS23_Tx_TICAN_3 :8 CentralMulti
 SG_ TyrePrSuf : 0|2@1+ (1,0) [0|3] "" Vector__XXX
 SG_ BrLinSuf : 2|2@1+ (1,0) [0|3] "" Vector__XXX
 SG_ BrTempSt : 4|2@1+ (1,0) [0|3] "" Vector__XXX
 SG_ PneuSupSuf : 6|2@1+ (1,0) [0|3] "" Vector__XXX
 SG_ TyreId_Press : 8|8@1+ (1,0) [0|255] "" Vector__XXX
 SG_ TyreId_Lining : 16|8@1+ (1,0) [0|255] "" Vector__XXX
 SG_ TyreId_Temp : 24|8@1+ (1,0) [0|255] "" Vector__XXX
 SG_ TyrePress : 32|8@1+ (10,0) [0|255] "kPa" Vector__XXX
 SG_ BrLin : 40|8@1+ (0.4,0) [0|255] "%" Vector__XXX
 SG_ BrTemp : 48|8@1+ (10,0) [0|255] "C" Vector__XXX
 SG_ PneuSupPr : 56|8@1+ (5,0) [0|255] "kPa" Vector__XXX

BO_ 2566833840 EBS23_Tx_TICAN_4 :8 CentralMulti
 SG_ TyrePrSuf : 0|2@1+ (1,0) [0|3] "" Vector__XXX
 SG_ BrLinSuf : 2|2@1+ (1,0) [0|3] "" Vector__XXX
 SG_ BrTempSt : 4|2@1+ (1,0) [0|3] "" Vector__XXX
 SG_ PneuSupSuf : 6|2@1+ (1,0) [0|3] "" Vector__XXX
 SG_ TyreId_Press : 8|8@1+ (1,0) [0|255] "" Vector__XXX
 SG_ TyreId_Lining : 16|8@1+ (1,0) [0|255] "" Vector__XXX
 SG_ TyreId_Temp : 24|8@1+ (1,0) [0|255] "" Vector__XXX
 SG_ TyrePress : 32|8@1+ (10,0) [0|255] "kPa" Vector__XXX
 SG_ BrLin : 40|8@1+ (0.4,0) [0|255] "%" Vector__XXX
 SG_ BrTemp : 48|8@1+ (10,0) [0|255] "C" Vector__XXX
 SG_ PneuSupPr : 56|8@1+ (5,0) [0|255] "kPa" Vector__XXX

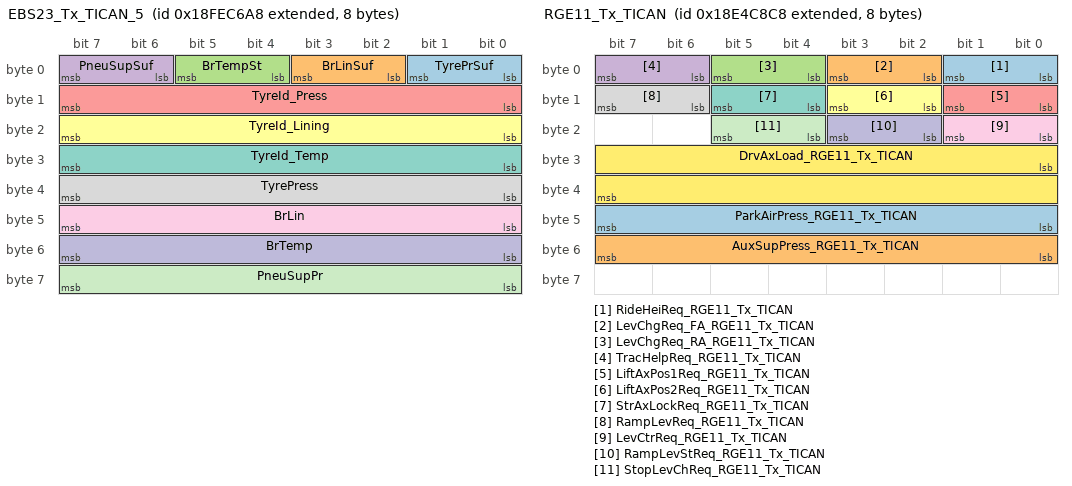
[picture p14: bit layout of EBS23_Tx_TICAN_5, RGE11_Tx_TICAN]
BO_ 2566833832 EBS23_Tx_TICAN_5 :8 CentralMulti
 SG_ TyrePrSuf : 0|2@1+ (1,0) [0|3] "" Vector__XXX
 SG_ BrLinSuf : 2|2@1+ (1,0) [0|3] "" Vector__XXX
 SG_ BrTempSt : 4|2@1+ (1,0) [0|3] "" Vector__XXX
 SG_ PneuSupSuf : 6|2@1+ (1,0) [0|3] "" Vector__XXX
 SG_ TyreId_Press : 8|8@1+ (1,0) [0|255] "" Vector__XXX
 SG_ TyreId_Lining : 16|8@1+ (1,0) [0|255] "" Vector__XXX
 SG_ TyreId_Temp : 24|8@1+ (1,0) [0|255] "" Vector__XXX
 SG_ TyrePress : 32|8@1+ (10,0) [0|255] "kPa" Vector__XXX
 SG_ BrLin : 40|8@1+ (0.4,0) [0|255] "%" Vector__XXX
 SG_ BrTemp : 48|8@1+ (10,0) [0|255] "C" Vector__XXX
 SG_ PneuSupPr : 56|8@1+ (5,0) [0|255] "kPa" Vector__XXX

BO_ 2566757064 EBS24_Tx_TICAN :8 Central
 SG_ GeomDataIndex : 0|8@1+ (1,0) [0|255] "" Vector__XXX
 SG_ GeomDataContent : 8|8@1+ (1,0) [0|255] "" Vector__XXX

BO_ 2566757056 EBS24_Tx_TICAN_2 :8 CentralMulti
 SG_ GeomDataIndex : 0|8@1+ (1,0) [0|255] "" Vector__XXX
 SG_ GeomDataContent : 8|8@1+ (1,0) [0|255] "" Vector__XXX

BO_ 2566757048 EBS24_Tx_TICAN_3 :8 CentralMulti
 SG_ GeomDataIndex : 0|8@1+ (1,0) [0|255] "" Vector__XXX
 SG_ GeomDataContent : 8|8@1+ (1,0) [0|255] "" Vector__XXX

BO_ 2566757040 EBS24_Tx_TICAN_4 :8 CentralMulti
 SG_ GeomDataIndex : 0|8@1+ (1,0) [0|255] "" Vector__XXX
 SG_ GeomDataContent : 8|8@1+ (1,0) [0|255] "" Vector__XXX

BO_ 2566757032 EBS24_Tx_TICAN_5 :8 CentralMulti
 SG_ GeomDataIndex : 0|8@1+ (1,0) [0|255] "" Vector__XXX
 SG_ GeomDataContent : 8|8@1+ (1,0) [0|255] "" Vector__XXX

BO_ 2565873864 EBS25_Tx_TICAN :8 Central
 SG_ PBrCyl_A1L : 0|8@1+ (5,0) [0|255] "kPa" Vector__XXX
 SG_ PBrCyl_A1R : 8|8@1+ (5,0) [0|255] "kPa" Vector__XXX
 SG_ PBrCyl_A2L : 16|8@1+ (5,0) [0|255] "kPa" Vector__XXX
 SG_ PBrCyl_A2R : 24|8@1+ (5,0) [0|255] "kPa" Vector__XXX
 SG_ PBrCyl_A3L : 32|8@1+ (5,0) [0|255] "kPa" Vector__XXX
 SG_ PBrCyl_A3R : 40|8@1+ (5,0) [0|255] "kPa" Vector__XXX
 SG_ ROPEna : 48|2@1+ (1,0) [0|3] "" Vector__XXX
 SG_ YCEna : 50|2@1+ (1,0) [0|3] "" Vector__XXX

BO_ 2565873856 EBS25_Tx_TICAN_2 :8 CentralMulti
 SG_ PBrCyl_A1L : 0|8@1+ (5,0) [0|255] "kPa" Vector__XXX
 SG_ PBrCyl_A1R : 8|8@1+ (5,0) [0|255] "kPa" Vector__XXX
 SG_ PBrCyl_A2L : 16|8@1+ (5,0) [0|255] "kPa" Vector__XXX
 SG_ PBrCyl_A2R : 24|8@1+ (5,0) [0|255] "kPa" Vector__XXX
 SG_ PBrCyl_A3L : 32|8@1+ (5,0) [0|255] "kPa" Vector__XXX
 SG_ PBrCyl_A3R : 40|8@1+ (5,0) [0|255] "kPa" Vector__XXX
 SG_ ROPEna : 48|2@1+ (1,0) [0|3] "" Vector__XXX
 SG_ YCEna : 50|2@1+ (1,0) [0|3] "" Vector__XXX

BO_ 2565873848 EBS25_Tx_TICAN_3 :8 CentralMulti
 SG_ PBrCyl_A1L : 0|8@1+ (5,0) [0|255] "kPa" Vector__XXX
 SG_ PBrCyl_A1R : 8|8@1+ (5,0) [0|255] "kPa" Vector__XXX
 SG_ PBrCyl_A2L : 16|8@1+ (5,0) [0|255] "kPa" Vector__XXX
 SG_ PBrCyl_A2R : 24|8@1+ (5,0) [0|255] "kPa" Vector__XXX
 SG_ PBrCyl_A3L : 32|8@1+ (5,0) [0|255] "kPa" Vector__XXX
 SG_ PBrCyl_A3R : 40|8@1+ (5,0) [0|255] "kPa" Vector__XXX
 SG_ ROPEna : 48|2@1+ (1,0) [0|3] "" Vector__XXX
 SG_ YCEna : 50|2@1+ (1,0) [0|3] "" Vector__XXX

BO_ 2565873840 EBS25_Tx_TICAN_4 :8 CentralMulti
 SG_ PBrCyl_A1L : 0|8@1+ (5,0) [0|255] "kPa" Vector__XXX
 SG_ PBrCyl_A1R : 8|8@1+ (5,0) [0|255] "kPa" Vector__XXX
 SG_ PBrCyl_A2L : 16|8@1+ (5,0) [0|255] "kPa" Vector__XXX
 SG_ PBrCyl_A2R : 24|8@1+ (5,0) [0|255] "kPa" Vector__XXX
 SG_ PBrCyl_A3L : 32|8@1+ (5,0) [0|255] "kPa" Vector__XXX
 SG_ PBrCyl_A3R : 40|8@1+ (5,0) [0|255] "kPa" Vector__XXX
 SG_ ROPEna : 48|2@1+ (1,0) [0|3] "" Vector__XXX
 SG_ YCEna : 50|2@1+ (1,0) [0|3] "" Vector__XXX

BO_ 2565873832 EBS25_Tx_TICAN_5 :8 CentralMulti
 SG_ PBrCyl_A1L : 0|8@1+ (5,0) [0|255] "kPa" Vector__XXX
 SG_ PBrCyl_A1R : 8|8@1+ (5,0) [0|255] "kPa" Vector__XXX
 SG_ PBrCyl_A2L : 16|8@1+ (5,0) [0|255] "kPa" Vector__XXX
 SG_ PBrCyl_A2R : 24|8@1+ (5,0) [0|255] "kPa" Vector__XXX
 SG_ PBrCyl_A3L : 32|8@1+ (5,0) [0|255] "kPa" Vector__XXX
 SG_ PBrCyl_A3R : 40|8@1+ (5,0) [0|255] "kPa" Vector__XXX
 SG_ ROPEna : 48|2@1+ (1,0) [0|3] "" Vector__XXX
 SG_ YCEna : 50|2@1+ (1,0) [0|3] "" Vector__XXX

BO_ 2364547016 EBS26_Tx_TICAN :8 Central
 SG_ V_A1L : 0|16@1+ (0.00390625,0) [0|65535] "km/h" Vector__XXX
 SG_ V_A1R : 16|16@1+ (0.00390625,0) [0|65535] "km/h" Vector__XXX

BO_ 2364547008 EBS26_Tx_TICAN_2 :8 CentralMulti
 SG_ V_A1L : 0|16@1+ (0.00390625,0) [0|65535] "km/h" Vector__XXX
 SG_ V_A1R : 16|16@1+ (0.00390625,0) [0|65535] "km/h" Vector__XXX

BO_ 2364547000 EBS26_Tx_TICAN_3 :8 CentralMulti
 SG_ V_A1L : 0|16@1+ (0.00390625,0) [0|65535] "km/h" Vector__XXX
 SG_ V_A1R : 16|16@1+ (0.00390625,0) [0|65535] "km/h" Vector__XXX

BO_ 2364546992 EBS26_Tx_TICAN_4 :8 CentralMulti
 SG_ V_A1L : 0|16@1+ (0.00390625,0) [0|65535] "km/h" Vector__XXX
 SG_ V_A1R : 16|16@1+ (0.00390625,0) [0|65535] "km/h" Vector__XXX

BO_ 2364546984 EBS26_Tx_TICAN_5 :8 CentralMulti
 SG_ V_A1L : 0|16@1+ (0.00390625,0) [0|65535] "km/h" Vector__XXX
 SG_ V_A1R : 16|16@1+ (0.00390625,0) [0|65535] "km/h" Vector__XXX

BO_ 2565130440 RGE11_Tx_TICAN :8 Central
 SG_ RideHeiReq_RGE11_Tx_TICAN : 0|2@1+ (1,0) [0|3] "" Vector__XXX
 SG_ LevChgReq_FA_RGE11_Tx_TICAN : 2|2@1+ (1,0) [0|3] "" Vector__XXX
 SG_ LevChgReq_RA_RGE11_Tx_TICAN : 4|2@1+ (1,0) [0|3] "" Vector__XXX
 SG_ TracHelpReq_RGE11_Tx_TICAN : 6|2@1+ (1,0) [0|3] "" Vector__XXX
 SG_ LiftAxPos1Req_RGE11_Tx_TICAN : 8|2@1+ (1,0) [0|3] "" Vector__XXX
 SG_ LiftAxPos2Req_RGE11_Tx_TICAN : 10|2@1+ (1,0) [0|3] "" Vector__XXX
 SG_ StrAxLockReq_RGE11_Tx_TICAN : 12|2@1+ (1,0) [0|3] "" Vector__XXX
 SG_ RampLevReq_RGE11_Tx_TICAN : 14|2@1+ (1,0) [0|3] "" Vector__XXX
 SG_ LevCtrReq_RGE11_Tx_TICAN : 16|2@1+ (1,0) [0|3] "" Vector__XXX
 SG_ RampLevStReq_RGE11_Tx_TICAN : 18|2@1+ (1,0) [0|3] "" Vector__XXX
 SG_ StopLevChReq_RGE11_Tx_TICAN : 20|2@1+ (1,0) [0|3] "" Vector__XXX
 SG_ DrvAxLoad_RGE11_Tx_TICAN : 24|16@1+ (2,0) [0|65535] "kg" Vector__XXX
 SG_ ParkAirPress_RGE11_Tx_TICAN : 40|8@1+ (80,0) [0|255] "mbar" Vector__XXX
 SG_ AuxSupPress_RGE11_Tx_TICAN : 48|8@1+ (80,0) [0|255] "mbar" Vector__XXX

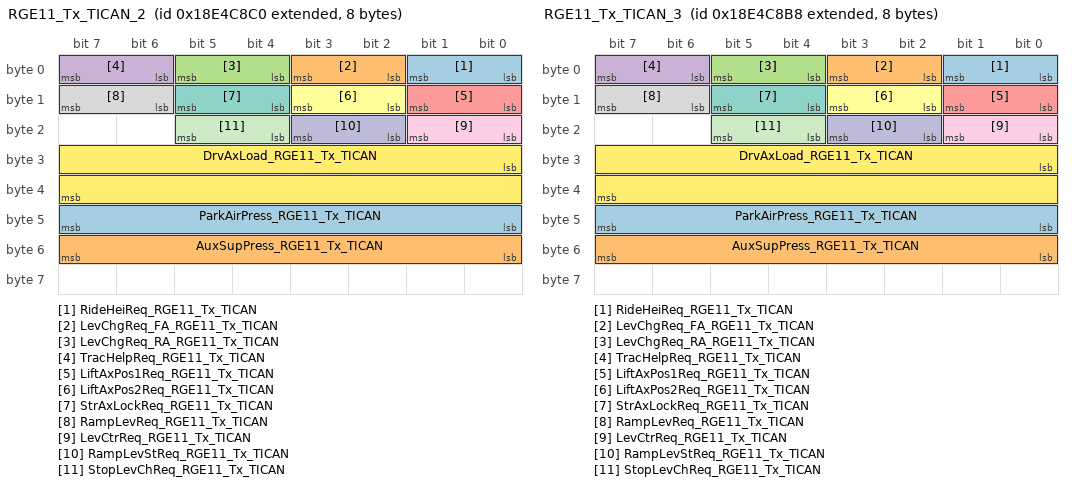
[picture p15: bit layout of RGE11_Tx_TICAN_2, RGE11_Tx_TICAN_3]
BO_ 2565130432 RGE11_Tx_TICAN_2 :8 CentralMulti
 SG_ RideHeiReq_RGE11_Tx_TICAN : 0|2@1+ (1,0) [0|3] "" Vector__XXX
 SG_ LevChgReq_FA_RGE11_Tx_TICAN : 2|2@1+ (1,0) [0|3] "" Vector__XXX
 SG_ LevChgReq_RA_RGE11_Tx_TICAN : 4|2@1+ (1,0) [0|3] "" Vector__XXX
 SG_ TracHelpReq_RGE11_Tx_TICAN : 6|2@1+ (1,0) [0|3] "" Vector__XXX
 SG_ LiftAxPos1Req_RGE11_Tx_TICAN : 8|2@1+ (1,0) [0|3] "" Vector__XXX
 SG_ LiftAxPos2Req_RGE11_Tx_TICAN : 10|2@1+ (1,0) [0|3] "" Vector__XXX
 SG_ StrAxLockReq_RGE11_Tx_TICAN : 12|2@1+ (1,0) [0|3] "" Vector__XXX
 SG_ RampLevReq_RGE11_Tx_TICAN : 14|2@1+ (1,0) [0|3] "" Vector__XXX
 SG_ LevCtrReq_RGE11_Tx_TICAN : 16|2@1+ (1,0) [0|3] "" Vector__XXX
 SG_ RampLevStReq_RGE11_Tx_TICAN : 18|2@1+ (1,0) [0|3] "" Vector__XXX
 SG_ StopLevChReq_RGE11_Tx_TICAN : 20|2@1+ (1,0) [0|3] "" Vector__XXX
 SG_ DrvAxLoad_RGE11_Tx_TICAN : 24|16@1+ (2,0) [0|65535] "kg" Vector__XXX
 SG_ ParkAirPress_RGE11_Tx_TICAN : 40|8@1+ (80,0) [0|255] "mbar" Vector__XXX
 SG_ AuxSupPress_RGE11_Tx_TICAN : 48|8@1+ (80,0) [0|255] "mbar" Vector__XXX

BO_ 2565130424 RGE11_Tx_TICAN_3 :8 CentralMulti
 SG_ RideHeiReq_RGE11_Tx_TICAN : 0|2@1+ (1,0) [0|3] "" Vector__XXX
 SG_ LevChgReq_FA_RGE11_Tx_TICAN : 2|2@1+ (1,0) [0|3] "" Vector__XXX
 SG_ LevChgReq_RA_RGE11_Tx_TICAN : 4|2@1+ (1,0) [0|3] "" Vector__XXX
 SG_ TracHelpReq_RGE11_Tx_TICAN : 6|2@1+ (1,0) [0|3] "" Vector__XXX
 SG_ LiftAxPos1Req_RGE11_Tx_TICAN : 8|2@1+ (1,0) [0|3] "" Vector__XXX
 SG_ LiftAxPos2Req_RGE11_Tx_TICAN : 10|2@1+ (1,0) [0|3] "" Vector__XXX
 SG_ StrAxLockReq_RGE11_Tx_TICAN : 12|2@1+ (1,0) [0|3] "" Vector__XXX
 SG_ RampLevReq_RGE11_Tx_TICAN : 14|2@1+ (1,0) [0|3] "" Vector__XXX
 SG_ LevCtrReq_RGE11_Tx_TICAN : 16|2@1+ (1,0) [0|3] "" Vector__XXX
 SG_ RampLevStReq_RGE11_Tx_TICAN : 18|2@1+ (1,0) [0|3] "" Vector__XXX
 SG_ StopLevChReq_RGE11_Tx_TICAN : 20|2@1+ (1,0) [0|3] "" Vector__XXX
 SG_ DrvAxLoad_RGE11_Tx_TICAN : 24|16@1+ (2,0) [0|65535] "kg" Vector__XXX
 SG_ ParkAirPress_RGE11_Tx_TICAN : 40|8@1+ (80,0) [0|255] "mbar" Vector__XXX
 SG_ AuxSupPress_RGE11_Tx_TICAN : 48|8@1+ (80,0) [0|255] "mbar" Vector__XXX

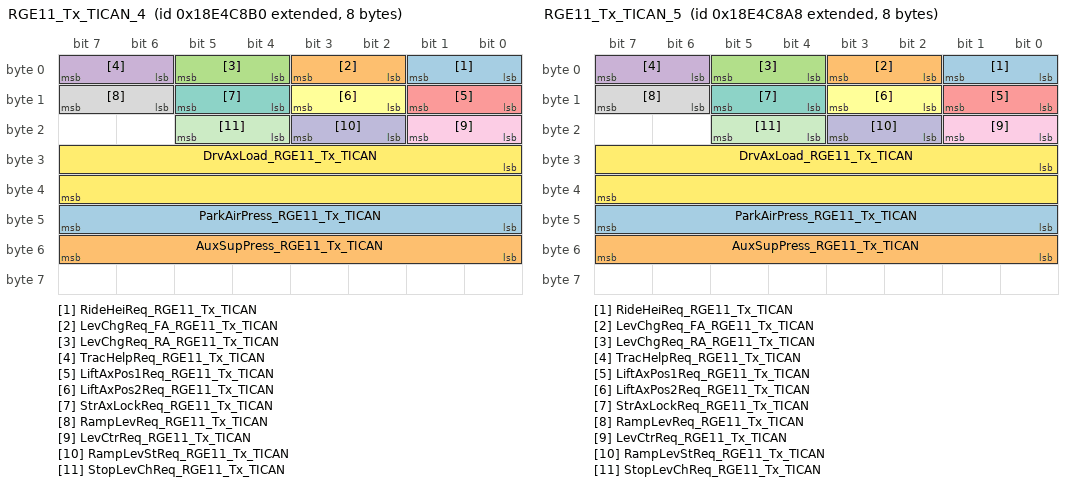
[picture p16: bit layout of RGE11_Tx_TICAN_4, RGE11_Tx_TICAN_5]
BO_ 2565130416 RGE11_Tx_TICAN_4 :8 CentralMulti
 SG_ RideHeiReq_RGE11_Tx_TICAN : 0|2@1+ (1,0) [0|3] "" Vector__XXX
 SG_ LevChgReq_FA_RGE11_Tx_TICAN : 2|2@1+ (1,0) [0|3] "" Vector__XXX
 SG_ LevChgReq_RA_RGE11_Tx_TICAN : 4|2@1+ (1,0) [0|3] "" Vector__XXX
 SG_ TracHelpReq_RGE11_Tx_TICAN : 6|2@1+ (1,0) [0|3] "" Vector__XXX
 SG_ LiftAxPos1Req_RGE11_Tx_TICAN : 8|2@1+ (1,0) [0|3] "" Vector__XXX
 SG_ LiftAxPos2Req_RGE11_Tx_TICAN : 10|2@1+ (1,0) [0|3] "" Vector__XXX
 SG_ StrAxLockReq_RGE11_Tx_TICAN : 12|2@1+ (1,0) [0|3] "" Vector__XXX
 SG_ RampLevReq_RGE11_Tx_TICAN : 14|2@1+ (1,0) [0|3] "" Vector__XXX
 SG_ LevCtrReq_RGE11_Tx_TICAN : 16|2@1+ (1,0) [0|3] "" Vector__XXX
 SG_ RampLevStReq_RGE11_Tx_TICAN : 18|2@1+ (1,0) [0|3] "" Vector__XXX
 SG_ StopLevChReq_RGE11_Tx_TICAN : 20|2@1+ (1,0) [0|3] "" Vector__XXX
 SG_ DrvAxLoad_RGE11_Tx_TICAN : 24|16@1+ (2,0) [0|65535] "kg" Vector__XXX
 SG_ ParkAirPress_RGE11_Tx_TICAN : 40|8@1+ (80,0) [0|255] "mbar" Vector__XXX
 SG_ AuxSupPress_RGE11_Tx_TICAN : 48|8@1+ (80,0) [0|255] "mbar" Vector__XXX

BO_ 2565130408 RGE11_Tx_TICAN_5 :8 CentralMulti
 SG_ RideHeiReq_RGE11_Tx_TICAN : 0|2@1+ (1,0) [0|3] "" Vector__XXX
 SG_ LevChgReq_FA_RGE11_Tx_TICAN : 2|2@1+ (1,0) [0|3] "" Vector__XXX
 SG_ LevChgReq_RA_RGE11_Tx_TICAN : 4|2@1+ (1,0) [0|3] "" Vector__XXX
 SG_ TracHelpReq_RGE11_Tx_TICAN : 6|2@1+ (1,0) [0|3] "" Vector__XXX
 SG_ LiftAxPos1Req_RGE11_Tx_TICAN : 8|2@1+ (1,0) [0|3] "" Vector__XXX
 SG_ LiftAxPos2Req_RGE11_Tx_TICAN : 10|2@1+ (1,0) [0|3] "" Vector__XXX
 SG_ StrAxLockReq_RGE11_Tx_TICAN : 12|2@1+ (1,0) [0|3] "" Vector__XXX
 SG_ RampLevReq_RGE11_Tx_TICAN : 14|2@1+ (1,0) [0|3] "" Vector__XXX
 SG_ LevCtrReq_RGE11_Tx_TICAN : 16|2@1+ (1,0) [0|3] "" Vector__XXX
 SG_ RampLevStReq_RGE11_Tx_TICAN : 18|2@1+ (1,0) [0|3] "" Vector__XXX
 SG_ StopLevChReq_RGE11_Tx_TICAN : 20|2@1+ (1,0) [0|3] "" Vector__XXX
 SG_ DrvAxLoad_RGE11_Tx_TICAN : 24|16@1+ (2,0) [0|65535] "kg" Vector__XXX
 SG_ ParkAirPress_RGE11_Tx_TICAN : 40|8@1+ (80,0) [0|255] "mbar" Vector__XXX
 SG_ AuxSupPress_RGE11_Tx_TICAN : 48|8@1+ (80,0) [0|255] "mbar" Vector__XXX

BO_ 2559232200 RGE12_Tx_TICAN :8 Central
 SG_ AxLCalDataStrReq_RGE12_TICAN_Tx : 0|2@1+ (1,0) [0|3] "" Vector__XXX
 SG_ WhlId_RGE12_TICAN_Tx : 8|8@1+ (1,0) [0|255] "" Vector__XXX
 SG_ AxLoadExtScale_RGE12_TICAN_Tx : 16|16@1+ (1,0) [0|65535] "kg" Vector__XXX
 SG_ VINindex_RGE12_TICAN_Tx : 32|8@1+ (1,0) [0|255] "" Vector__XXX
 SG_ VINdata_RGE12_TICAN_Tx : 40|8@1+ (1,0) [0|255] "" Vector__XXX

BO_ 2559232192 RGE12_Tx_TICAN_2 :8 CentralMulti
 SG_ AxLCalDataStrReq_RGE12_TICAN_Tx : 0|2@1+ (1,0) [0|3] "" Vector__XXX
 SG_ WhlId_RGE12_TICAN_Tx : 8|8@1+ (1,0) [0|255] "" Vector__XXX
 SG_ AxLoadExtScale_RGE12_TICAN_Tx : 16|16@1+ (1,0) [0|65535] "kg" Vector__XXX
 SG_ VINindex_RGE12_TICAN_Tx : 32|8@1+ (1,0) [0|255] "" Vector__XXX
 SG_ VINdata_RGE12_TICAN_Tx : 40|8@1+ (1,0) [0|255] "" Vector__XXX

BO_ 2559232184 RGE12_Tx_TICAN_3 :8 CentralMulti
 SG_ AxLCalDataStrReq_RGE12_TICAN_Tx : 0|2@1+ (1,0) [0|3] "" Vector__XXX
 SG_ WhlId_RGE12_TICAN_Tx : 8|8@1+ (1,0) [0|255] "" Vector__XXX
 SG_ AxLoadExtScale_RGE12_TICAN_Tx : 16|16@1+ (1,0) [0|65535] "kg" Vector__XXX
 SG_ VINindex_RGE12_TICAN_Tx : 32|8@1+ (1,0) [0|255] "" Vector__XXX
 SG_ VINdata_RGE12_TICAN_Tx : 40|8@1+ (1,0) [0|255] "" Vector__XXX

BO_ 2559232176 RGE12_Tx_TICAN_4 :8 CentralMulti
 SG_ AxLCalDataStrReq_RGE12_TICAN_Tx : 0|2@1+ (1,0) [0|3] "" Vector__XXX
 SG_ WhlId_RGE12_TICAN_Tx : 8|8@1+ (1,0) [0|255] "" Vector__XXX
 SG_ AxLoadExtScale_RGE12_TICAN_Tx : 16|16@1+ (1,0) [0|65535] "kg" Vector__XXX
 SG_ VINindex_RGE12_TICAN_Tx : 32|8@1+ (1,0) [0|255] "" Vector__XXX
 SG_ VINdata_RGE12_TICAN_Tx : 40|8@1+ (1,0) [0|255] "" Vector__XXX

BO_ 2559232168 RGE12_Tx_TICAN_5 :8 CentralMulti
 SG_ AxLCalDataStrReq_RGE12_TICAN_Tx : 0|2@1+ (1,0) [0|3] "" Vector__XXX
 SG_ WhlId_RGE12_TICAN_Tx : 8|8@1+ (1,0) [0|255] "" Vector__XXX
 SG_ AxLoadExtScale_RGE12_TICAN_Tx : 16|16@1+ (1,0) [0|65535] "kg" Vector__XXX
 SG_ VINindex_RGE12_TICAN_Tx : 32|8@1+ (1,0) [0|255] "" Vector__XXX
 SG_ VINdata_RGE12_TICAN_Tx : 40|8@1+ (1,0) [0|255] "" Vector__XXX

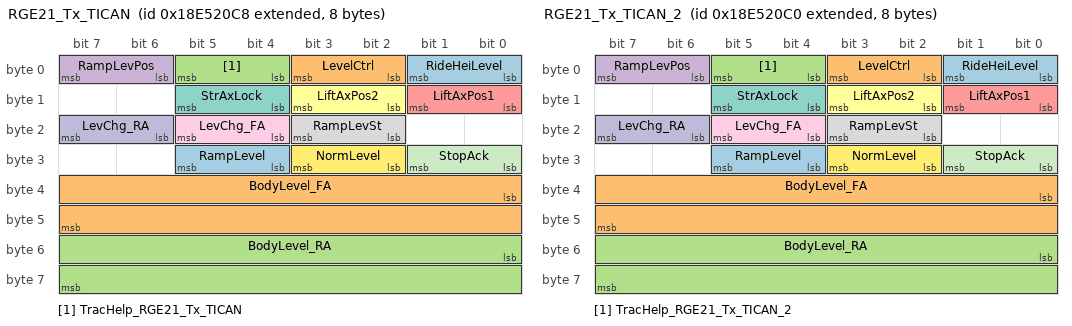
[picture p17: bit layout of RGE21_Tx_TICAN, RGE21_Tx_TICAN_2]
BO_ 2565152968 RGE21_Tx_TICAN :8 Central
 SG_ RideHeiLevel : 0|2@1+ (1,0) [0|3] "" Vector__XXX
 SG_ LevelCtrl : 2|2@1+ (1,0) [0|3] "" Vector__XXX
 SG_ TracHelp_RGE21_Tx_TICAN : 4|2@1+ (1,0) [0|3] "" Vector__XXX
 SG_ RampLevPos : 6|2@1+ (1,0) [0|3] "" Vector__XXX
 SG_ LiftAxPos1 : 8|2@1+ (1,0) [0|3] "" Vector__XXX
 SG_ LiftAxPos2 : 10|2@1+ (1,0) [0|3] "" Vector__XXX
 SG_ StrAxLock : 12|2@1+ (1,0) [0|3] "" Vector__XXX
 SG_ RampLevSt : 18|2@1+ (1,0) [0|3] "" Vector__XXX
 SG_ LevChg_FA : 20|2@1+ (1,0) [0|3] "" Vector__XXX
 SG_ LevChg_RA : 22|2@1+ (1,0) [0|3] "" Vector__XXX
 SG_ StopAck : 24|2@1+ (1,0) [0|3] "" Vector__XXX
 SG_ NormLevel : 26|2@1+ (1,0) [0|3] "" Vector__XXX
 SG_ RampLevel : 28|2@1+ (1,0) [0|3] "" Vector__XXX
 SG_ BodyLevel_FA : 32|16@1+ (1,0) [0|65535] "mm" Vector__XXX
 SG_ BodyLevel_RA : 48|16@1+ (1,0) [0|65535] "mm" Vector__XXX

BO_ 2565152960 RGE21_Tx_TICAN_2 :8 CentralMulti
 SG_ RideHeiLevel : 0|2@1+ (1,0) [0|3] "" Vector__XXX
 SG_ LevelCtrl : 2|2@1+ (1,0) [0|3] "" Vector__XXX
 SG_ TracHelp_RGE21_Tx_TICAN_2 : 4|2@1+ (1,0) [0|3] "" Vector__XXX
 SG_ RampLevPos : 6|2@1+ (1,0) [0|3] "" Vector__XXX
 SG_ LiftAxPos1 : 8|2@1+ (1,0) [0|3] "" Vector__XXX
 SG_ LiftAxPos2 : 10|2@1+ (1,0) [0|3] "" Vector__XXX
 SG_ StrAxLock : 12|2@1+ (1,0) [0|3] "" Vector__XXX
 SG_ RampLevSt : 18|2@1+ (1,0) [0|3] "" Vector__XXX
 SG_ LevChg_FA : 20|2@1+ (1,0) [0|3] "" Vector__XXX
 SG_ LevChg_RA : 22|2@1+ (1,0) [0|3] "" Vector__XXX
 SG_ StopAck : 24|2@1+ (1,0) [0|3] "" Vector__XXX
 SG_ NormLevel : 26|2@1+ (1,0) [0|3] "" Vector__XXX
 SG_ RampLevel : 28|2@1+ (1,0) [0|3] "" Vector__XXX
 SG_ BodyLevel_FA : 32|16@1+ (1,0) [0|65535] "mm" Vector__XXX
 SG_ BodyLevel_RA : 48|16@1+ (1,0) [0|65535] "mm" Vector__XXX

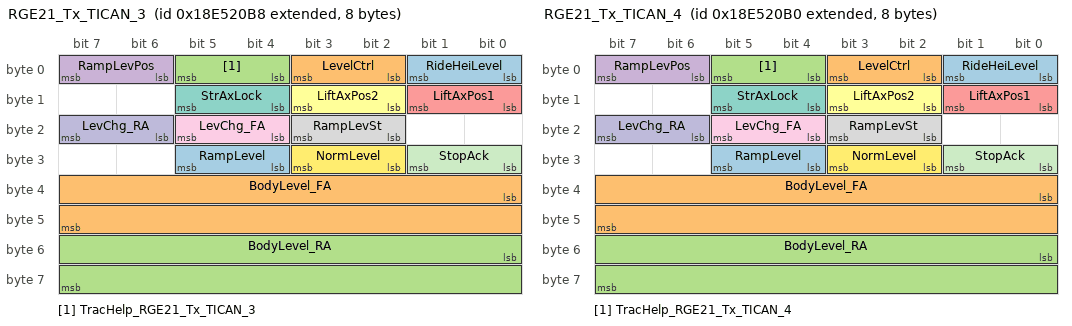
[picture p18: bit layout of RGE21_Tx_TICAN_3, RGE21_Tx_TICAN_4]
BO_ 2565152952 RGE21_Tx_TICAN_3 :8 CentralMulti
 SG_ RideHeiLevel : 0|2@1+ (1,0) [0|3] "" Vector__XXX
 SG_ LevelCtrl : 2|2@1+ (1,0) [0|3] "" Vector__XXX
 SG_ TracHelp_RGE21_Tx_TICAN_3 : 4|2@1+ (1,0) [0|3] "" Vector__XXX
 SG_ RampLevPos : 6|2@1+ (1,0) [0|3] "" Vector__XXX
 SG_ LiftAxPos1 : 8|2@1+ (1,0) [0|3] "" Vector__XXX
 SG_ LiftAxPos2 : 10|2@1+ (1,0) [0|3] "" Vector__XXX
 SG_ StrAxLock : 12|2@1+ (1,0) [0|3] "" Vector__XXX
 SG_ RampLevSt : 18|2@1+ (1,0) [0|3] "" Vector__XXX
 SG_ LevChg_FA : 20|2@1+ (1,0) [0|3] "" Vector__XXX
 SG_ LevChg_RA : 22|2@1+ (1,0) [0|3] "" Vector__XXX
 SG_ StopAck : 24|2@1+ (1,0) [0|3] "" Vector__XXX
 SG_ NormLevel : 26|2@1+ (1,0) [0|3] "" Vector__XXX
 SG_ RampLevel : 28|2@1+ (1,0) [0|3] "" Vector__XXX
 SG_ BodyLevel_FA : 32|16@1+ (1,0) [0|65535] "mm" Vector__XXX
 SG_ BodyLevel_RA : 48|16@1+ (1,0) [0|65535] "mm" Vector__XXX

BO_ 2565152944 RGE21_Tx_TICAN_4 :8 CentralMulti
 SG_ RideHeiLevel : 0|2@1+ (1,0) [0|3] "" Vector__XXX
 SG_ LevelCtrl : 2|2@1+ (1,0) [0|3] "" Vector__XXX
 SG_ TracHelp_RGE21_Tx_TICAN_4 : 4|2@1+ (1,0) [0|3] "" Vector__XXX
 SG_ RampLevPos : 6|2@1+ (1,0) [0|3] "" Vector__XXX
 SG_ LiftAxPos1 : 8|2@1+ (1,0) [0|3] "" Vector__XXX
 SG_ LiftAxPos2 : 10|2@1+ (1,0) [0|3] "" Vector__XXX
 SG_ StrAxLock : 12|2@1+ (1,0) [0|3] "" Vector__XXX
 SG_ RampLevSt : 18|2@1+ (1,0) [0|3] "" Vector__XXX
 SG_ LevChg_FA : 20|2@1+ (1,0) [0|3] "" Vector__XXX
 SG_ LevChg_RA : 22|2@1+ (1,0) [0|3] "" Vector__XXX
 SG_ StopAck : 24|2@1+ (1,0) [0|3] "" Vector__XXX
 SG_ NormLevel : 26|2@1+ (1,0) [0|3] "" Vector__XXX
 SG_ RampLevel : 28|2@1+ (1,0) [0|3] "" Vector__XXX
 SG_ BodyLevel_FA : 32|16@1+ (1,0) [0|65535] "mm" Vector__XXX
 SG_ BodyLevel_RA : 48|16@1+ (1,0) [0|65535] "mm" Vector__XXX

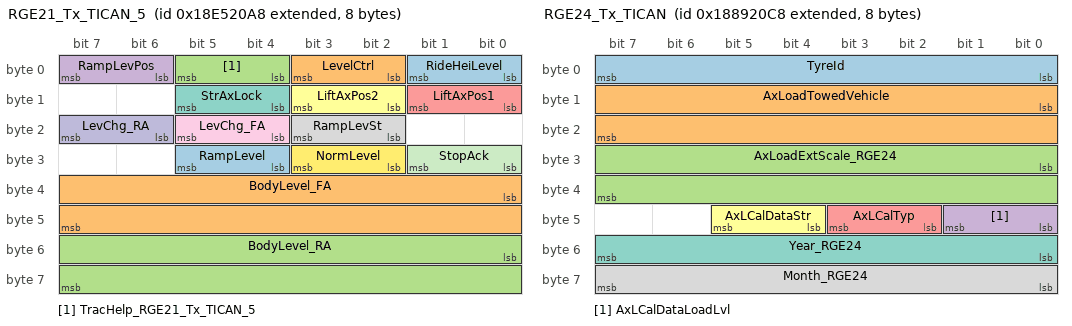
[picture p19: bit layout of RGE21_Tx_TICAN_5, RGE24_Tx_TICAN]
BO_ 2565152936 RGE21_Tx_TICAN_5 :8 CentralMulti
 SG_ RideHeiLevel : 0|2@1+ (1,0) [0|3] "" Vector__XXX
 SG_ LevelCtrl : 2|2@1+ (1,0) [0|3] "" Vector__XXX
 SG_ TracHelp_RGE21_Tx_TICAN_5 : 4|2@1+ (1,0) [0|3] "" Vector__XXX
 SG_ RampLevPos : 6|2@1+ (1,0) [0|3] "" Vector__XXX
 SG_ LiftAxPos1 : 8|2@1+ (1,0) [0|3] "" Vector__XXX
 SG_ LiftAxPos2 : 10|2@1+ (1,0) [0|3] "" Vector__XXX
 SG_ StrAxLock : 12|2@1+ (1,0) [0|3] "" Vector__XXX
 SG_ RampLevSt : 18|2@1+ (1,0) [0|3] "" Vector__XXX
 SG_ LevChg_FA : 20|2@1+ (1,0) [0|3] "" Vector__XXX
 SG_ LevChg_RA : 22|2@1+ (1,0) [0|3] "" Vector__XXX
 SG_ StopAck : 24|2@1+ (1,0) [0|3] "" Vector__XXX
 SG_ NormLevel : 26|2@1+ (1,0) [0|3] "" Vector__XXX
 SG_ RampLevel : 28|2@1+ (1,0) [0|3] "" Vector__XXX
 SG_ BodyLevel_FA : 32|16@1+ (1,0) [0|65535] "mm" Vector__XXX
 SG_ BodyLevel_RA : 48|16@1+ (1,0) [0|65535] "mm" Vector__XXX

BO_ 2566806728 RGE22_Tx_TICAN :8 Central
 SG_ ReBodyLevFA : 0|16@1+ (1,-32000) [0|65535] "mm" Vector__XXX
 SG_ ReBodyLevRA : 16|16@1+ (1,-32000) [0|65535] "mm" Vector__XXX
 SG_ WheelAxleId : 32|8@1+ (1,0) [0|255] "" Vector__XXX
 SG_ AxleLoad : 40|16@1+ (0.5,0) [0|65535] "kg" Vector__XXX

BO_ 2566806720 RGE22_Tx_TICAN_2 :8 CentralMulti
 SG_ ReBodyLevFA : 0|16@1+ (1,-32000) [0|65535] "mm" Vector__XXX
 SG_ ReBodyLevRA : 16|16@1+ (1,-32000) [0|65535] "mm" Vector__XXX
 SG_ WheelAxleId : 32|8@1+ (1,0) [0|255] "" Vector__XXX
 SG_ AxleLoad : 40|16@1+ (0.5,0) [0|65535] "kg" Vector__XXX

BO_ 2566806712 RGE22_Tx_TICAN_3 :8 CentralMulti
 SG_ ReBodyLevFA : 0|16@1+ (1,-32000) [0|65535] "mm" Vector__XXX
 SG_ ReBodyLevRA : 16|16@1+ (1,-32000) [0|65535] "mm" Vector__XXX
 SG_ WheelAxleId : 32|8@1+ (1,0) [0|255] "" Vector__XXX
 SG_ AxleLoad : 40|16@1+ (0.5,0) [0|65535] "kg" Vector__XXX

BO_ 2566806704 RGE22_Tx_TICAN_4 :8 CentralMulti
 SG_ ReBodyLevFA : 0|16@1+ (1,-32000) [0|65535] "mm" Vector__XXX
 SG_ ReBodyLevRA : 16|16@1+ (1,-32000) [0|65535] "mm" Vector__XXX
 SG_ WheelAxleId : 32|8@1+ (1,0) [0|255] "" Vector__XXX
 SG_ AxleLoad : 40|16@1+ (0.5,0) [0|65535] "kg" Vector__XXX

BO_ 2566806696 RGE22_Tx_TICAN_5 :8 CentralMulti
 SG_ ReBodyLevFA : 0|16@1+ (1,-32000) [0|65535] "mm" Vector__XXX
 SG_ ReBodyLevRA : 16|16@1+ (1,-32000) [0|65535] "mm" Vector__XXX
 SG_ WheelAxleId : 32|8@1+ (1,0) [0|255] "" Vector__XXX
 SG_ AxleLoad : 40|16@1+ (0.5,0) [0|65535] "kg" Vector__XXX

BO_ 2566807240 RGE23_Tx_TICAN :8 Central
 SG_ TyreId : 0|8@1+ (1,0) [0|255] "" Vector__XXX
 SG_ TyreTemp : 8|16@1+ (0.03125,-273) [0|65535] "C" Vector__XXX
 SG_ AirLeakDet : 24|16@1+ (0.1,0) [0|65535] "Pa/s" Vector__XXX
 SG_ TyrePrTrhDet : 40|3@1+ (1,0) [0|7] "" Vector__XXX
 SG_ TyrePowSup : 43|2@1+ (1,0) [0|3] "" Vector__XXX
 SG_ VINindex_RGE23_Tx_TICAN : 48|8@1+ (1,0) [0|255] "" Vector__XXX
 SG_ VINdata_RGE23_Tx_TICAN : 56|8@1+ (1,0) [0|255] "" Vector__XXX

BO_ 2566807232 RGE23_Tx_TICAN_2 :8 CentralMulti
 SG_ TyreId : 0|8@1+ (1,0) [0|255] "" Vector__XXX
 SG_ TyreTemp : 8|16@1+ (0.03125,-273) [0|65535] "C" Vector__XXX
 SG_ AirLeakDet : 24|16@1+ (0.1,0) [0|65535] "Pa/s" Vector__XXX
 SG_ TyrePrTrhDet : 40|3@1+ (1,0) [0|7] "" Vector__XXX
 SG_ TyrePowSup : 43|2@1+ (1,0) [0|3] "" Vector__XXX
 SG_ VINindex_RGE23_Tx_TICAN_2 : 48|8@1+ (1,0) [0|255] "" Vector__XXX
 SG_ VINdata_RGE23_Tx_TICAN_2 : 56|8@1+ (1,0) [0|255] "" Vector__XXX

BO_ 2566807224 RGE23_Tx_TICAN_3 :8 CentralMulti
 SG_ TyreId : 0|8@1+ (1,0) [0|255] "" Vector__XXX
 SG_ TyreTemp : 8|16@1+ (0.03125,-273) [0|65535] "C" Vector__XXX
 SG_ AirLeakDet : 24|16@1+ (0.1,0) [0|65535] "Pa/s" Vector__XXX
 SG_ TyrePrTrhDet : 40|3@1+ (1,0) [0|7] "" Vector__XXX
 SG_ TyrePowSup : 43|2@1+ (1,0) [0|3] "" Vector__XXX
 SG_ VINindex_RGE23_Tx_TICAN_3 : 48|8@1+ (1,0) [0|255] "" Vector__XXX
 SG_ VINdata_RGE23_Tx_TICAN_3 : 56|8@1+ (1,0) [0|255] "" Vector__XXX

BO_ 2566807216 RGE23_Tx_TICAN_4 :8 CentralMulti
 SG_ TyreId : 0|8@1+ (1,0) [0|255] "" Vector__XXX
 SG_ TyreTemp : 8|16@1+ (0.03125,-273) [0|65535] "C" Vector__XXX
 SG_ AirLeakDet : 24|16@1+ (0.1,0) [0|65535] "Pa/s" Vector__XXX
 SG_ TyrePrTrhDet : 40|3@1+ (1,0) [0|7] "" Vector__XXX
 SG_ TyrePowSup : 43|2@1+ (1,0) [0|3] "" Vector__XXX
 SG_ VINindex_RGE23_Tx_TICAN_4 : 48|8@1+ (1,0) [0|255] "" Vector__XXX
 SG_ VINdata_RGE23_Tx_TICAN_4 : 56|8@1+ (1,0) [0|255] "" Vector__XXX

BO_ 2566807208 RGE23_Tx_TICAN_5 :8 CentralMulti
 SG_ TyreId : 0|8@1+ (1,0) [0|255] "" Vector__XXX
 SG_ TyreTemp : 8|16@1+ (0.03125,-273) [0|65535] "C" Vector__XXX
 SG_ AirLeakDet : 24|16@1+ (0.1,0) [0|65535] "Pa/s" Vector__XXX
 SG_ TyrePrTrhDet : 40|3@1+ (1,0) [0|7] "" Vector__XXX
 SG_ TyrePowSup : 43|2@1+ (1,0) [0|3] "" Vector__XXX
 SG_ VINindex_RGE23_Tx_TICAN_5 : 48|8@1+ (1,0) [0|255] "" Vector__XXX
 SG_ VINdata_RGE23_Tx_TICAN_5 : 56|8@1+ (1,0) [0|255] "" Vector__XXX

BO_ 2559123656 RGE24_Tx_TICAN :8 Central
 SG_ TyreId : 0|8@1+ (1,0) [0|255] "" Vector__XXX
 SG_ AxLoadTowedVehicle : 8|16@1+ (1,0) [0|65535] "kg" Vector__XXX
 SG_ AxLoadExtScale_RGE24 : 24|16@1+ (1,0) [0|65535] "kg" Vector__XXX
 SG_ AxLCalDataLoadLvl : 40|2@1+ (1,0) [0|3] "" Vector__XXX
 SG_ AxLCalTyp : 42|2@1+ (1,0) [0|3] "" Vector__XXX
 SG_ AxLCalDataStr : 44|2@1+ (1,0) [0|3] "" Vector__XXX
 SG_ Year_RGE24 : 48|8@1+ (1,-15) [0|255] "year" Vector__XXX
 SG_ Month_RGE24 : 56|8@1+ (1,0) [0|255] "" Vector__XXX

BO_ 2559123648 RGE24_Tx_TICAN_2 :8 CentralMulti
 SG_ TyreId : 0|8@1+ (1,0) [0|255] "" Vector__XXX
 SG_ AxLoadTowedVehicle : 8|16@1+ (1,0) [0|65535] "kg" Vector__XXX
 SG_ AxLoadExtScale_RGE24 : 24|16@1+ (1,0) [0|65535] "kg" Vector__XXX
 SG_ AxLCalDataLoadLvl : 40|2@1+ (1,0) [0|3] "" Vector__XXX
 SG_ AxLCalTyp : 42|2@1+ (1,0) [0|3] "" Vector__XXX
 SG_ AxLCalDataStr : 44|2@1+ (1,0) [0|3] "" Vector__XXX
 SG_ Year_RGE24 : 48|8@1+ (1,-15) [0|255] "year" Vector__XXX
 SG_ Month_RGE24 : 56|8@1+ (1,0) [0|255] "" Vector__XXX

BO_ 2559123640 RGE24_Tx_TICAN_3 :8 CentralMulti
 SG_ TyreId : 0|8@1+ (1,0) [0|255] "" Vector__XXX
 SG_ AxLoadTowedVehicle : 8|16@1+ (1,0) [0|65535] "kg" Vector__XXX
 SG_ AxLoadExtScale_RGE24 : 24|16@1+ (1,0) [0|65535] "kg" Vector__XXX
 SG_ AxLCalDataLoadLvl : 40|2@1+ (1,0) [0|3] "" Vector__XXX
 SG_ AxLCalTyp : 42|2@1+ (1,0) [0|3] "" Vector__XXX
 SG_ AxLCalDataStr : 44|2@1+ (1,0) [0|3] "" Vector__XXX
 SG_ Year_RGE24 : 48|8@1+ (1,-15) [0|255] "year" Vector__XXX
 SG_ Month_RGE24 : 56|8@1+ (1,0) [0|255] "" Vector__XXX

BO_ 2559123632 RGE24_Tx_TICAN_4 :8 CentralMulti
 SG_ TyreId : 0|8@1+ (1,0) [0|255] "" Vector__XXX
 SG_ AxLoadTowedVehicle : 8|16@1+ (1,0) [0|65535] "kg" Vector__XXX
 SG_ AxLoadExtScale_RGE24 : 24|16@1+ (1,0) [0|65535] "kg" Vector__XXX
 SG_ AxLCalDataLoadLvl : 40|2@1+ (1,0) [0|3] "" Vector__XXX
 SG_ AxLCalTyp : 42|2@1+ (1,0) [0|3] "" Vector__XXX
 SG_ AxLCalDataStr : 44|2@1+ (1,0) [0|3] "" Vector__XXX
 SG_ Year_RGE24 : 48|8@1+ (1,-15) [0|255] "year" Vector__XXX
 SG_ Month_RGE24 : 56|8@1+ (1,0) [0|255] "" Vector__XXX

BO_ 2559123624 RGE24_Tx_TICAN_5 :8 CentralMulti
 SG_ TyreId : 0|8@1+ (1,0) [0|255] "" Vector__XXX
 SG_ AxLoadTowedVehicle : 8|16@1+ (1,0) [0|65535] "kg" Vector__XXX
 SG_ AxLoadExtScale_RGE24 : 24|16@1+ (1,0) [0|65535] "kg" Vector__XXX
 SG_ AxLCalDataLoadLvl : 40|2@1+ (1,0) [0|3] "" Vector__XXX
 SG_ AxLCalTyp : 42|2@1+ (1,0) [0|3] "" Vector__XXX
 SG_ AxLCalDataStr : 44|2@1+ (1,0) [0|3] "" Vector__XXX
 SG_ Year_RGE24 : 48|8@1+ (1,-15) [0|255] "year" Vector__XXX
 SG_ Month_RGE24 : 56|8@1+ (1,0) [0|255] "" Vector__XXX

BO_ 2565523456 ReqPGN_Rx :3 OffboardUDS
 SG_ ReqPGNLow : 0|8@1+ (1,0) [0|255] "" Central
 SG_ ReqPGNMiddle : 8|8@1+ (1,0) [0|255] "" Central
 SG_ ReqPGNHigh : 16|8@1+ (1,0) [0|255] "" Central

BO_ 2565521600 ReqPGN_Rx_1 :8 Predecessor_Node
 SG_ ReqPGNLow : 0|8@1+ (1,0) [0|255] "" CentralMulti
 SG_ ReqPGNMiddle : 8|8@1+ (1,0) [0|255] "" CentralMulti
 SG_ ReqPGNHigh : 16|8@1+ (1,0) [0|255] "" CentralMulti

BO_ 2565519544 ReqPGN_Rx_2 :8 Predecessor_Node
 SG_ ReqPGNLow : 0|8@1+ (1,0) [0|255] "" CentralMulti
 SG_ ReqPGNMiddle : 8|8@1+ (1,0) [0|255] "" CentralMulti
 SG_ ReqPGNHigh : 16|8@1+ (1,0) [0|255] "" CentralMulti

BO_ 2565517488 ReqPGN_Rx_3 :8 Predecessor_Node
 SG_ ReqPGNLow : 0|8@1+ (1,0) [0|255] "" CentralMulti
 SG_ ReqPGNMiddle : 8|8@1+ (1,0) [0|255] "" CentralMulti
 SG_ ReqPGNHigh : 16|8@1+ (1,0) [0|255] "" CentralMulti

BO_ 2565515432 ReqPGN_Rx_4 :8 Predecessor_Node
 SG_ ReqPGNLow : 0|8@1+ (1,0) [0|255] "" CentralMulti
 SG_ ReqPGNMiddle : 8|8@1+ (1,0) [0|255] "" CentralMulti
 SG_ ReqPGNHigh : 16|8@1+ (1,0) [0|255] "" CentralMulti

BO_ 2565513376 ReqPGN_Rx_5 :8 Predecessor_Node
 SG_ ReqPGNLow : 0|8@1+ (1,0) [0|255] "" CentralMulti
 SG_ ReqPGNMiddle : 8|8@1+ (1,0) [0|255] "" CentralMulti
 SG_ ReqPGNHigh : 16|8@1+ (1,0) [0|255] "" CentralMulti

BO_ 2565511320 ReqPGN_Rx_6 :8 Predecessor_Node
 SG_ ReqPGNLow : 0|8@1+ (1,0) [0|255] "" CentralMulti
 SG_ ReqPGNMiddle : 8|8@1+ (1,0) [0|255] "" CentralMulti
 SG_ ReqPGNHigh : 16|8@1+ (1,0) [0|255] "" CentralMulti

BO_ 2565509264 ReqPGN_Rx_7 :8 Predecessor_Node
 SG_ ReqPGNLow : 0|8@1+ (1,0) [0|255] "" CentralMulti
 SG_ ReqPGNMiddle : 8|8@1+ (1,0) [0|255] "" CentralMulti
 SG_ ReqPGNHigh : 16|8@1+ (1,0) [0|255] "" CentralMulti

BO_ 2565507208 ReqPGN_Rx_8 :8 Predecessor_Node
 SG_ ReqPGNLow : 0|8@1+ (1,0) [0|255] "" CentralMulti
 SG_ ReqPGNMiddle : 8|8@1+ (1,0) [0|255] "" CentralMulti
 SG_ ReqPGNHigh : 16|8@1+ (1,0) [0|255] "" CentralMulti

BO_ 2565505152 ReqPGN_Rx_9 :8 Predecessor_Node
 SG_ ReqPGNLow : 0|8@1+ (1,0) [0|255] "" CentralMulti
 SG_ ReqPGNMiddle : 8|8@1+ (1,0) [0|255] "" CentralMulti
 SG_ ReqPGNHigh : 16|8@1+ (1,0) [0|255] "" CentralMulti

BO_ 2565537536 ReqPGN_Rx_G :8 Predecessor_Node
 SG_ ReqPGNLow : 0|8@1+ (1,0) [0|255] "" CentralMulti
 SG_ ReqPGNMiddle : 8|8@1+ (1,0) [0|255] "" CentralMulti
 SG_ ReqPGNHigh : 16|8@1+ (1,0) [0|255] "" CentralMulti

BO_ 2566841891 TD_Rx :8 OffboardUDS
 SG_ Seconds : 0|8@1+ (0.25,0) [0|255] "s" Central
 SG_ Minutes : 8|8@1+ (1,0) [0|255] "" Central
 SG_ Hours : 16|8@1+ (1,0) [0|255] "" Central
 SG_ Month : 24|8@1+ (1,0) [0|255] "" Central
 SG_ Day : 32|8@1+ (0.25,0) [0|255] "day" Central
 SG_ Year : 40|8@1+ (1,-15) [0|255] "year" Central
 SG_ LocalMinuteOffset : 48|8@1+ (1,-125) [0|255] "min" Central
 SG_ LocalHourOffset : 56|8@1+ (1,-125) [0|255] "hour" Central

BO_ 2566857984 PGN65317_Rx :8 OffboardUDS
 SG_ WLReq : 2|2@1+ (1,0) [0|3] "" Central
 SG_ BrIntvEna : 4|2@1+ (1,0) [0|3] "" Central
 SG_ BrDemJ1939 : 8|16@1+ (1,0) [0|65535] "mbar" Central

BO_ 2565406664 AckPGN_Tx :8 Central
 SG_ ControlByte : 0|8@1+ (1,0) [0|255] "" Vector__XXX
 SG_ GroupFuncVal : 8|8@1+ (1,0) [0|255] "" Vector__XXX
 SG_ ECUAddress : 32|8@1+ (1,0) [0|255] "" Vector__XXX
 SG_ RequestedPGN : 40|16@1+ (1,0) [0|65535] "" Vector__XXX

BO_ 2565406656 AckPGN_Tx_2 :8 CentralMulti
 SG_ ControlByte : 0|8@1+ (1,0) [0|255] "" Vector__XXX
 SG_ GroupFuncVal : 8|8@1+ (1,0) [0|255] "" Vector__XXX
 SG_ ECUAddress : 32|8@1+ (1,0) [0|255] "" Vector__XXX
 SG_ RequestedPGN : 40|16@1+ (1,0) [0|65535] "" Vector__XXX

BO_ 2565406648 AckPGN_Tx_3 :8 CentralMulti
 SG_ ControlByte : 0|8@1+ (1,0) [0|255] "" Vector__XXX
 SG_ GroupFuncVal : 8|8@1+ (1,0) [0|255] "" Vector__XXX
 SG_ ECUAddress : 32|8@1+ (1,0) [0|255] "" Vector__XXX
 SG_ RequestedPGN : 40|16@1+ (1,0) [0|65535] "" Vector__XXX

BO_ 2565406640 AckPGN_Tx_4 :8 CentralMulti
 SG_ ControlByte : 0|8@1+ (1,0) [0|255] "" Vector__XXX
 SG_ GroupFuncVal : 8|8@1+ (1,0) [0|255] "" Vector__XXX
 SG_ ECUAddress : 32|8@1+ (1,0) [0|255] "" Vector__XXX
 SG_ RequestedPGN : 40|16@1+ (1,0) [0|65535] "" Vector__XXX

BO_ 2565406632 AckPGN_Tx_5 :8 CentralMulti
 SG_ ControlByte : 0|8@1+ (1,0) [0|255] "" Vector__XXX
 SG_ GroupFuncVal : 8|8@1+ (1,0) [0|255] "" Vector__XXX
 SG_ ECUAddress : 32|8@1+ (1,0) [0|255] "" Vector__XXX
 SG_ RequestedPGN : 40|16@1+ (1,0) [0|65535] "" Vector__XXX

BO_ 2565406624 AckPGN_Tx_6 :8 CentralMulti
 SG_ ControlByte : 0|8@1+ (1,0) [0|255] "" Vector__XXX
 SG_ GroupFuncVal : 8|8@1+ (1,0) [0|255] "" Vector__XXX
 SG_ ECUAddress : 32|8@1+ (1,0) [0|255] "" Vector__XXX
 SG_ RequestedPGN : 40|16@1+ (1,0) [0|65535] "" Vector__XXX

BO_ 2565406616 AckPGN_Tx_7 :8 CentralMulti
 SG_ ControlByte : 0|8@1+ (1,0) [0|255] "" Vector__XXX
 SG_ GroupFuncVal : 8|8@1+ (1,0) [0|255] "" Vector__XXX
 SG_ ECUAddress : 32|8@1+ (1,0) [0|255] "" Vector__XXX
 SG_ RequestedPGN : 40|16@1+ (1,0) [0|65535] "" Vector__XXX

BO_ 2565406608 AckPGN_Tx_8 :8 CentralMulti
 SG_ ControlByte : 0|8@1+ (1,0) [0|255] "" Vector__XXX
 SG_ GroupFuncVal : 8|8@1+ (1,0) [0|255] "" Vector__XXX
 SG_ ECUAddress : 32|8@1+ (1,0) [0|255] "" Vector__XXX
 SG_ RequestedPGN : 40|16@1+ (1,0) [0|65535] "" Vector__XXX

BO_ 2565406600 AckPGN_Tx_9 :8 CentralMulti
 SG_ ControlByte : 0|8@1+ (1,0) [0|255] "" Vector__XXX
 SG_ GroupFuncVal : 8|8@1+ (1,0) [0|255] "" Vector__XXX
 SG_ ECUAddress : 32|8@1+ (1,0) [0|255] "" Vector__XXX
 SG_ RequestedPGN : 40|16@1+ (1,0) [0|65535] "" Vector__XXX

BO_ 2565406592 AckPGN_Tx_10 :8 CentralMulti
 SG_ ControlByte : 0|8@1+ (1,0) [0|255] "" Vector__XXX
 SG_ GroupFuncVal : 8|8@1+ (1,0) [0|255] "" Vector__XXX
 SG_ ECUAddress : 32|8@1+ (1,0) [0|255] "" Vector__XXX
 SG_ RequestedPGN : 40|16@1+ (1,0) [0|65535] "" Vector__XXX

BO_ 2566832072 EBC2_Tx :8 Central
 SG_ vVeh_EBC2_Tx : 0|16@1+ (0.00390625,0) [0|65535] "km/h" Vector__XXX

BO_ 2566832064 EBC2_Tx_2 :8 CentralMulti
 SG_ vVeh_EBC2_Tx_2 : 0|16@1+ (0.00390625,0) [0|65535] "km/h" Vector__XXX

BO_ 2566832056 EBC2_Tx_3 :8 CentralMulti
 SG_ vVeh_EBC2_Tx_3 : 0|16@1+ (0.00390625,0) [0|65535] "km/h" Vector__XXX

BO_ 2566832048 EBC2_Tx_4 :8 CentralMulti
 SG_ vVeh_EBC2_Tx_4 : 0|16@1+ (0.00390625,0) [0|65535] "km/h" Vector__XXX

BO_ 2566832040 EBC2_Tx_5 :8 CentralMulti
 SG_ vVeh_EBC2_Tx_5 : 0|16@1+ (0.00390625,0) [0|65535] "km/h" Vector__XXX

BO_ 2566832032 EBC2_Tx_6 :8 CentralMulti
 SG_ vVeh_EBC2_Tx_6 : 0|16@1+ (0.00390625,0) [0|65535] "km/h" Vector__XXX

BO_ 2566832024 EBC2_Tx_7 :8 CentralMulti
 SG_ vVeh_EBC2_Tx_7 : 0|16@1+ (0.00390625,0) [0|65535] "km/h" Vector__XXX

BO_ 2566832016 EBC2_Tx_8 :8 CentralMulti
 SG_ vVeh_EBC2_Tx_8 : 0|16@1+ (0.00390625,0) [0|65535] "km/h" Vector__XXX

BO_ 2566832008 EBC2_Tx_9 :8 CentralMulti
 SG_ vVeh_EBC2_Tx_9 : 0|16@1+ (0.00390625,0) [0|65535] "km/h" Vector__XXX

BO_ 2566832000 EBC2_Tx_10 :8 CentralMulti
 SG_ vVeh_EBC2_Tx_10 : 0|16@1+ (0.00390625,0) [0|65535] "km/h" Vector__XXX

BO_ 2566832328 SERV_Tx :8 Central
 SG_ ComponentId : 0|8@1+ (1,0) [0|255] "" Vector__XXX
 SG_ ServiceDist_SERV_Tx : 8|16@1+ (5,-160635) [0|65535] "km" Vector__XXX

BO_ 2566832320 SERV_Tx_2 :8 CentralMulti
 SG_ ComponentId : 0|8@1+ (1,0) [0|255] "" Vector__XXX
 SG_ ServiceDist_SERV_Tx_2 : 8|16@1+ (5,-160635) [0|65535] "km" Vector__XXX

BO_ 2566832312 SERV_Tx_3 :8 CentralMulti
 SG_ ComponentId : 0|8@1+ (1,0) [0|255] "" Vector__XXX
 SG_ ServiceDist_SERV_Tx_3 : 8|16@1+ (5,-160635) [0|65535] "km" Vector__XXX

BO_ 2566832304 SERV_Tx_4 :8 CentralMulti
 SG_ ComponentId : 0|8@1+ (1,0) [0|255] "" Vector__XXX
 SG_ ServiceDist_SERV_Tx_4 : 8|16@1+ (5,-160635) [0|65535] "km" Vector__XXX

BO_ 2566832296 SERV_Tx_5 :8 CentralMulti
 SG_ ComponentId : 0|8@1+ (1,0) [0|255] "" Vector__XXX
 SG_ ServiceDist_SERV_Tx_5 : 8|16@1+ (5,-160635) [0|65535] "km" Vector__XXX

BO_ 2566832288 SERV_Tx_6 :8 CentralMulti
 SG_ ComponentId : 0|8@1+ (1,0) [0|255] "" Vector__XXX
 SG_ ServiceDist_SERV_Tx_6 : 8|16@1+ (5,-160635) [0|65535] "km" Vector__XXX

BO_ 2566832280 SERV_Tx_7 :8 CentralMulti
 SG_ ComponentId : 0|8@1+ (1,0) [0|255] "" Vector__XXX
 SG_ ServiceDist_SERV_Tx_7 : 8|16@1+ (5,-160635) [0|65535] "km" Vector__XXX

BO_ 2566832272 SERV_Tx_8 :8 CentralMulti
 SG_ ComponentId : 0|8@1+ (1,0) [0|255] "" Vector__XXX
 SG_ ServiceDist_SERV_Tx_8 : 8|16@1+ (5,-160635) [0|65535] "km" Vector__XXX

BO_ 2566832264 SERV_Tx_9 :8 CentralMulti
 SG_ ComponentId : 0|8@1+ (1,0) [0|255] "" Vector__XXX
 SG_ ServiceDist_SERV_Tx_9 : 8|16@1+ (5,-160635) [0|65535] "km" Vector__XXX

BO_ 2566832256 SERV_Tx_10 :8 CentralMulti
 SG_ ComponentId : 0|8@1+ (1,0) [0|255] "" Vector__XXX
 SG_ ServiceDist_SERV_Tx_10 : 8|16@1+ (5,-160635) [0|65535] "km" Vector__XXX

BO_ 2566832584 VDHR_Tx :8 Central
 SG_ ODO : 0|32@1+ (0.005,0) [0|4294967295] "km" Vector__XXX
 SG_ Trip : 32|32@1+ (0.005,0) [0|4294967295] "km" Vector__XXX

BO_ 2566832576 VDHR_Tx_2 :8 CentralMulti
 SG_ ODO : 0|32@1+ (0.005,0) [0|4294967295] "km" Vector__XXX
 SG_ Trip : 32|32@1+ (0.005,0) [0|4294967295] "km" Vector__XXX

BO_ 2566832568 VDHR_Tx_3 :8 CentralMulti
 SG_ ODO : 0|32@1+ (0.005,0) [0|4294967295] "km" Vector__XXX
 SG_ Trip : 32|32@1+ (0.005,0) [0|4294967295] "km" Vector__XXX

BO_ 2566832560 VDHR_Tx_4 :8 CentralMulti
 SG_ ODO : 0|32@1+ (0.005,0) [0|4294967295] "km" Vector__XXX
 SG_ Trip : 32|32@1+ (0.005,0) [0|4294967295] "km" Vector__XXX

BO_ 2566832552 VDHR_Tx_5 :8 CentralMulti
 SG_ ODO : 0|32@1+ (0.005,0) [0|4294967295] "km" Vector__XXX
 SG_ Trip : 32|32@1+ (0.005,0) [0|4294967295] "km" Vector__XXX

BO_ 2566832544 VDHR_Tx_6 :8 CentralMulti
 SG_ ODO : 0|32@1+ (0.005,0) [0|4294967295] "km" Vector__XXX
 SG_ Trip : 32|32@1+ (0.005,0) [0|4294967295] "km" Vector__XXX

BO_ 2566832536 VDHR_Tx_7 :8 CentralMulti
 SG_ ODO : 0|32@1+ (0.005,0) [0|4294967295] "km" Vector__XXX
 SG_ Trip : 32|32@1+ (0.005,0) [0|4294967295] "km" Vector__XXX

BO_ 2566832528 VDHR_Tx_8 :8 CentralMulti
 SG_ ODO : 0|32@1+ (0.005,0) [0|4294967295] "km" Vector__XXX
 SG_ Trip : 32|32@1+ (0.005,0) [0|4294967295] "km" Vector__XXX

BO_ 2566832520 VDHR_Tx_9 :8 CentralMulti
 SG_ ODO : 0|32@1+ (0.005,0) [0|4294967295] "km" Vector__XXX
 SG_ Trip : 32|32@1+ (0.005,0) [0|4294967295] "km" Vector__XXX

BO_ 2566832512 VDHR_Tx_10 :8 CentralMulti
 SG_ ODO : 0|32@1+ (0.005,0) [0|4294967295] "km" Vector__XXX
 SG_ Trip : 32|32@1+ (0.005,0) [0|4294967295] "km" Vector__XXX

BO_ 2566843080 VW_Tx :8 Central
 SG_ TrlWeight_VW_Tx : 24|16@1+ (2,0) [0|65535] "kg" Vector__XXX

BO_ 2566843072 VW_Tx_2 :8 CentralMulti
 SG_ TrlWeight_VW_Tx_2 : 24|16@1+ (2,0) [0|65535] "kg" Vector__XXX

BO_ 2566843064 VW_Tx_3 :8 CentralMulti
 SG_ TrlWeight_VW_Tx_3 : 24|16@1+ (2,0) [0|65535] "kg" Vector__XXX

BO_ 2566843056 VW_Tx_4 :8 CentralMulti
 SG_ TrlWeight_VW_Tx_4 : 24|16@1+ (2,0) [0|65535] "kg" Vector__XXX

BO_ 2566843048 VW_Tx_5 :8 CentralMulti
 SG_ TrlWeight_VW_Tx_5 : 24|16@1+ (2,0) [0|65535] "kg" Vector__XXX

BO_ 2566843040 VW_Tx_6 :8 CentralMulti
 SG_ TrlWeight_VW_Tx_6 : 24|16@1+ (2,0) [0|65535] "kg" Vector__XXX

BO_ 2566843032 VW_Tx_7 :8 CentralMulti
 SG_ TrlWeight_VW_Tx_7 : 24|16@1+ (2,0) [0|65535] "kg" Vector__XXX

BO_ 2566843024 VW_Tx_8 :8 CentralMulti
 SG_ TrlWeight_VW_Tx_8 : 24|16@1+ (2,0) [0|65535] "kg" Vector__XXX

BO_ 2566843016 VW_Tx_9 :8 CentralMulti
 SG_ TrlWeight_VW_Tx_9 : 24|16@1+ (2,0) [0|65535] "kg" Vector__XXX

BO_ 2566843008 VW_Tx_10 :8 CentralMulti
 SG_ TrlWeight_VW_Tx_10 : 24|16@1+ (2,0) [0|65535] "kg" Vector__XXX

BO_ 2566847176 B_Tx :8 Central
 SG_ PBrake : 0|8@1+ (40,0) [0|255] "mbar" Vector__XXX
 SG_ PSys_B_Tx : 8|8@1+ (40,0) [0|255] "mbar" Vector__XXX

BO_ 2566847168 B_Tx_2 :8 CentralMulti
 SG_ PBrake : 0|8@1+ (40,0) [0|255] "mbar" Vector__XXX
 SG_ PSys_B_Tx_2 : 8|8@1+ (40,0) [0|255] "mbar" Vector__XXX

BO_ 2566847160 B_Tx_3 :8 CentralMulti
 SG_ PBrake : 0|8@1+ (40,0) [0|255] "mbar" Vector__XXX
 SG_ PSys_B_Tx_3 : 8|8@1+ (40,0) [0|255] "mbar" Vector__XXX

BO_ 2566847152 B_Tx_4 :8 CentralMulti
 SG_ PBrake : 0|8@1+ (40,0) [0|255] "mbar" Vector__XXX
 SG_ PSys_B_Tx_4 : 8|8@1+ (40,0) [0|255] "mbar" Vector__XXX

BO_ 2566847144 B_Tx_5 :8 CentralMulti
 SG_ PBrake : 0|8@1+ (40,0) [0|255] "mbar" Vector__XXX
 SG_ PSys_B_Tx_5 : 8|8@1+ (40,0) [0|255] "mbar" Vector__XXX

BO_ 2566847136 B_Tx_6 :8 CentralMulti
 SG_ PBrake : 0|8@1+ (40,0) [0|255] "mbar" Vector__XXX
 SG_ PSys_B_Tx_6 : 8|8@1+ (40,0) [0|255] "mbar" Vector__XXX

BO_ 2566847128 B_Tx_7 :8 CentralMulti
 SG_ PBrake : 0|8@1+ (40,0) [0|255] "mbar" Vector__XXX
 SG_ PSys_B_Tx_7 : 8|8@1+ (40,0) [0|255] "mbar" Vector__XXX

BO_ 2566847120 B_Tx_8 :8 CentralMulti
 SG_ PBrake : 0|8@1+ (40,0) [0|255] "mbar" Vector__XXX
 SG_ PSys_B_Tx_8 : 8|8@1+ (40,0) [0|255] "mbar" Vector__XXX

BO_ 2566847112 B_Tx_9 :8 CentralMulti
 SG_ PBrake : 0|8@1+ (40,0) [0|255] "mbar" Vector__XXX
 SG_ PSys_B_Tx_9 : 8|8@1+ (40,0) [0|255] "mbar" Vector__XXX

BO_ 2566847104 B_Tx_10 :8 CentralMulti
 SG_ PBrake : 0|8@1+ (40,0) [0|255] "mbar" Vector__XXX
 SG_ PSys_B_Tx_10 : 8|8@1+ (40,0) [0|255] "mbar" Vector__XXX

BO_ 2566805960 ASC3_Tx :8 Central
 SG_ VehicleLevelFrontLeft : 0|16@1+ (0.1,-3200) [0|65535] "mm" Vector__XXX
 SG_ VehicleLevelFrontRight : 16|16@1+ (0.1,-3200) [0|65535] "mm" Vector__XXX
 SG_ VehicleLevelRearLeft : 32|16@1+ (0.1,-3200) [0|65535] "mm" Vector__XXX
 SG_ VehicleLevelRearRight : 48|16@1+ (0.1,-3200) [0|65535] "mm" Vector__XXX

BO_ 2566805952 ASC3_Tx_2 :8 CentralMulti
 SG_ VehicleLevelFrontLeft : 0|16@1+ (0.1,-3200) [0|65535] "mm" Vector__XXX
 SG_ VehicleLevelFrontRight : 16|16@1+ (0.1,-3200) [0|65535] "mm" Vector__XXX
 SG_ VehicleLevelRearLeft : 32|16@1+ (0.1,-3200) [0|65535] "mm" Vector__XXX
 SG_ VehicleLevelRearRight : 48|16@1+ (0.1,-3200) [0|65535] "mm" Vector__XXX

BO_ 2566805944 ASC3_Tx_3 :8 CentralMulti
 SG_ VehicleLevelFrontLeft : 0|16@1+ (0.1,-3200) [0|65535] "mm" Vector__XXX
 SG_ VehicleLevelFrontRight : 16|16@1+ (0.1,-3200) [0|65535] "mm" Vector__XXX
 SG_ VehicleLevelRearLeft : 32|16@1+ (0.1,-3200) [0|65535] "mm" Vector__XXX
 SG_ VehicleLevelRearRight : 48|16@1+ (0.1,-3200) [0|65535] "mm" Vector__XXX

BA_DEF_ BO_ "DiagConnection" INT 0 65535;
BA_DEF_ BO_ "DiagRequest" ENUM "No","Yes";
BA_DEF_ BO_ "DiagResponse" ENUM "No","Yes";
BA_DEF_ BO_ "GenMsgCycleTime" INT 0 3600000;
BA_DEF_ BO_ "GenMsgILSupport" ENUM "No","Yes";
BA_DEF_ BO_ "GenMsgRequestable" INT 0 1;
BA_DEF_ BO_ "GenMsgSendType" ENUM "cyclic","NotUsed","NotUsed","NotUsed","NotUsed","NotUsed","NotUsed","IfActive","noMsgSendType";
BA_DEF_ BO_ "VFrameFormat" ENUM "StandardCAN","ExtendedCAN","reserved","J1939PG";
BA_DEF_ SG_ "GenSigCycleTime" INT 0 4294967295;
BA_DEF_ SG_ "GenSigEVName" STRING ;
BA_DEF_ SG_ "GenSigILSupport" ENUM "No","Yes";
BA_DEF_ SG_ "GenSigInactiveValue" INT 0 4294967295;
BA_DEF_ SG_ "GenSigSendType" ENUM "Cyclic","OnWrite","OnWriteWithRepetition","OnChange","OnChangeWithRepetition","IfActive","IfActiveWithRepetition","NoSigSendType";
BA_DEF_ SG_ "GenSigStartValue" INT 0 4294967295;
BA_DEF_ SG_ "SigType" ENUM "Default","Range","RangeSigned","ASCII","Discrete","Control","ReferencePGN","DTC","StringDelimiter","StringLength","StringLengthControl";
BA_DEF_DEF_ "DiagConnection" 0;
BA_DEF_DEF_ "DiagRequest" "No";
BA_DEF_DEF_ "DiagResponse" "No";
BA_DEF_DEF_ "GenMsgCycleTime" 0;
BA_DEF_DEF_ "GenMsgILSupport" "Yes";
BA_DEF_DEF_ "GenMsgRequestable" 1;
BA_DEF_DEF_ "GenMsgSendType" "noMsgSendType";
BA_DEF_DEF_ "VFrameFormat" "J1939PG";
BA_DEF_DEF_ "GenSigCycleTime" 0;
BA_DEF_DEF_ "GenSigEVName" "Env@Nodename_@Signame";
BA_DEF_DEF_ "GenSigILSupport" "Yes";
BA_DEF_DEF_ "GenSigInactiveValue" 0;
BA_DEF_DEF_ "GenSigSendType" "NoSigSendType";
BA_DEF_DEF_ "GenSigStartValue" 0;
BA_DEF_DEF_ "SigType" "Default";
BA_ "VFrameFormat" BO_ 2566857920 1;
BA_ "GenSigSendType" SG_ 2566857920 vWhl4 1;
BA_ "GenSigSendType" SG_ 2566857920 vWhl5 1;
BA_ "GenSigSendType" SG_ 2566857920 BrAct 1;
BA_ "GenSigSendType" SG_ 2566857920 ABSAct 1;
BA_ "GenSigSendType" SG_ 2566857920 RSPAct 1;
BA_ "GenSigSendType" SG_ 2566857920 Overload_PGN65316_Tx_2 1;
BA_ "GenSigSendType" SG_ 2566857920 PDem 1;
BA_ "GenSigSendType" SG_ 2566857920 TrlWeight 1;
BA_ "GenSigSendType" SG_ 2566857920 TiltAngle 1;
BA_ "GenSigSendType" SG_ 2566857920 TAactive 1;
BA_ "GenSigSendType" SG_ 2566857920 BodyLift_PGN65316_Tx_2 1;
BA_ "VFrameFormat" BO_ 2566857912 1;
BA_ "GenSigSendType" SG_ 2566857912 vWhl4 1;
BA_ "GenSigSendType" SG_ 2566857912 vWhl5 1;
BA_ "GenSigSendType" SG_ 2566857912 BrAct 1;
BA_ "GenSigSendType" SG_ 2566857912 ABSAct 1;
BA_ "GenSigSendType" SG_ 2566857912 RSPAct 1;
BA_ "GenSigSendType" SG_ 2566857912 Overload_PGN65316_Tx_3 1;
BA_ "GenSigSendType" SG_ 2566857912 PDem 1;
BA_ "GenSigSendType" SG_ 2566857912 TrlWeight 1;
BA_ "GenSigSendType" SG_ 2566857912 TiltAngle 1;
BA_ "GenSigSendType" SG_ 2566857912 TAactive 1;
BA_ "GenSigSendType" SG_ 2566857912 BodyLift_PGN65316_Tx_3 1;
BA_ "VFrameFormat" BO_ 2566857904 1;
BA_ "GenSigSendType" SG_ 2566857904 vWhl4 1;
BA_ "GenSigSendType" SG_ 2566857904 vWhl5 1;
BA_ "GenSigSendType" SG_ 2566857904 BrAct 1;
BA_ "GenSigSendType" SG_ 2566857904 ABSAct 1;
BA_ "GenSigSendType" SG_ 2566857904 RSPAct 1;
BA_ "GenSigSendType" SG_ 2566857904 Overload_PGN65316_Tx_4 1;
BA_ "GenSigSendType" SG_ 2566857904 PDem 1;
BA_ "GenSigSendType" SG_ 2566857904 TrlWeight 1;
BA_ "GenSigSendType" SG_ 2566857904 TiltAngle 1;
BA_ "GenSigSendType" SG_ 2566857904 TAactive 1;
BA_ "GenSigSendType" SG_ 2566857904 BodyLift_PGN65316_Tx_4 1;
BA_ "VFrameFormat" BO_ 2566857896 1;
BA_ "GenSigSendType" SG_ 2566857896 vWhl4 1;
BA_ "GenSigSendType" SG_ 2566857896 vWhl5 1;
BA_ "GenSigSendType" SG_ 2566857896 BrAct 1;
BA_ "GenSigSendType" SG_ 2566857896 ABSAct 1;
BA_ "GenSigSendType" SG_ 2566857896 RSPAct 1;
BA_ "GenSigSendType" SG_ 2566857896 Overload_PGN65316_Tx_5 1;
BA_ "GenSigSendType" SG_ 2566857896 PDem 1;
BA_ "GenSigSendType" SG_ 2566857896 TrlWeight 1;
BA_ "GenSigSendType" SG_ 2566857896 TiltAngle 1;
BA_ "GenSigSendType" SG_ 2566857896 TAactive 1;
BA_ "GenSigSendType" SG_ 2566857896 BodyLift_PGN65316_Tx_5 1;
BA_ "VFrameFormat" BO_ 2566857888 1;
BA_ "GenSigSendType" SG_ 2566857888 vWhl4 1;
BA_ "GenSigSendType" SG_ 2566857888 vWhl5 1;
BA_ "GenSigSendType" SG_ 2566857888 BrAct 1;
BA_ "GenSigSendType" SG_ 2566857888 ABSAct 1;
BA_ "GenSigSendType" SG_ 2566857888 RSPAct 1;
BA_ "GenSigSendType" SG_ 2566857888 Overload_PGN65316_Tx_6 1;
BA_ "GenSigSendType" SG_ 2566857888 PDem 1;
BA_ "GenSigSendType" SG_ 2566857888 TrlWeight 1;
BA_ "GenSigSendType" SG_ 2566857888 TiltAngle 1;
BA_ "GenSigSendType" SG_ 2566857888 TAactive 1;
BA_ "GenSigSendType" SG_ 2566857888 BodyLift_PGN65316_Tx_6 1;
BA_ "VFrameFormat" BO_ 2566857880 1;
BA_ "GenSigSendType" SG_ 2566857880 vWhl4 1;
BA_ "GenSigSendType" SG_ 2566857880 vWhl5 1;
BA_ "GenSigSendType" SG_ 2566857880 BrAct 1;
BA_ "GenSigSendType" SG_ 2566857880 ABSAct 1;
BA_ "GenSigSendType" SG_ 2566857880 RSPAct 1;
BA_ "GenSigSendType" SG_ 2566857880 Overload_PGN65316_Tx_7 1;
BA_ "GenSigSendType" SG_ 2566857880 PDem 1;
BA_ "GenSigSendType" SG_ 2566857880 TrlWeight 1;
BA_ "GenSigSendType" SG_ 2566857880 TiltAngle 1;
BA_ "GenSigSendType" SG_ 2566857880 TAactive 1;
BA_ "GenSigSendType" SG_ 2566857880 BodyLift_PGN65316_Tx_7 1;
BA_ "VFrameFormat" BO_ 2566857872 1;
BA_ "GenSigSendType" SG_ 2566857872 vWhl4 1;
BA_ "GenSigSendType" SG_ 2566857872 vWhl5 1;
BA_ "GenSigSendType" SG_ 2566857872 BrAct 1;
BA_ "GenSigSendType" SG_ 2566857872 ABSAct 1;
BA_ "GenSigSendType" SG_ 2566857872 RSPAct 1;
BA_ "GenSigSendType" SG_ 2566857872 Overload_PGN65316_Tx_8 1;
BA_ "GenSigSendType" SG_ 2566857872 PDem 1;
BA_ "GenSigSendType" SG_ 2566857872 TrlWeight 1;
BA_ "GenSigSendType" SG_ 2566857872 TiltAngle 1;
BA_ "GenSigSendType" SG_ 2566857872 TAactive 1;
BA_ "GenSigSendType" SG_ 2566857872 BodyLift_PGN65316_Tx_8 1;
BA_ "VFrameFormat" BO_ 2566857864 1;
BA_ "GenSigSendType" SG_ 2566857864 vWhl4 1;
BA_ "GenSigSendType" SG_ 2566857864 vWhl5 1;
BA_ "GenSigSendType" SG_ 2566857864 BrAct 1;
BA_ "GenSigSendType" SG_ 2566857864 ABSAct 1;
BA_ "GenSigSendType" SG_ 2566857864 RSPAct 1;
BA_ "GenSigSendType" SG_ 2566857864 Overload_PGN65316_Tx_9 1;
BA_ "GenSigSendType" SG_ 2566857864 PDem 1;
BA_ "GenSigSendType" SG_ 2566857864 TrlWeight 1;
BA_ "GenSigSendType" SG_ 2566857864 TiltAngle 1;
BA_ "GenSigSendType" SG_ 2566857864 TAactive 1;
BA_ "GenSigSendType" SG_ 2566857864 BodyLift_PGN65316_Tx_9 1;
BA_ "VFrameFormat" BO_ 2566857856 1;
BA_ "GenSigSendType" SG_ 2566857856 vWhl4 1;
BA_ "GenSigSendType" SG_ 2566857856 vWhl5 1;
BA_ "GenSigSendType" SG_ 2566857856 BrAct 1;
BA_ "GenSigSendType" SG_ 2566857856 ABSAct 1;
BA_ "GenSigSendType" SG_ 2566857856 RSPAct 1;
BA_ "GenSigSendType" SG_ 2566857856 Overload_PGN65316_Tx_10 1;
BA_ "GenSigSendType" SG_ 2566857856 PDem 1;
BA_ "GenSigSendType" SG_ 2566857856 TrlWeight 1;
BA_ "GenSigSendType" SG_ 2566857856 TiltAngle 1;
BA_ "GenSigSendType" SG_ 2566857856 TAactive 1;
BA_ "GenSigSendType" SG_ 2566857856 BodyLift_PGN65316_Tx_10 1;
BA_ "VFrameFormat" BO_ 2348992712 1;
BA_ "GenSigSendType" SG_ 2348992712 VehABSAct_EBS11_Tx_TICAN 1;
BA_ "GenSigSendType" SG_ 2348992712 VehRetCtrAct_EBS11_Tx_TICAN 1;
BA_ "GenSigSendType" SG_ 2348992712 ASR_BC_Act 1;
BA_ "GenSigSendType" SG_ 2348992712 ASR_EC_Act 1;
BA_ "GenSigSendType" SG_ 2348992712 BrLightSw 1;
BA_ "GenSigSendType" SG_ 2348992712 VehType_EBS11_Tx_TICAN 1;
BA_ "GenSigSendType" SG_ 2348992712 VehVDCAct 1;
BA_ "GenSigSendType" SG_ 2348992712 ServBrDem 1;
BA_ "GenSigSendType" SG_ 2348992712 ParkBrDem_EBS11_Tx_TICAN 1;
BA_ "GenSigSendType" SG_ 2348992712 RetDem 1;
BA_ "GenSigSendType" SG_ 2348992712 RelDemFrontLeft 1;
BA_ "GenSigSendType" SG_ 2348992712 RelDemRearRight 1;
BA_ "VFrameFormat" BO_ 2348992704 1;
BA_ "GenSigSendType" SG_ 2348992704 VehABSAct_EBS11_Tx_TICAN_2 1;
BA_ "GenSigSendType" SG_ 2348992704 VehRetCtrAct_EBS11_Tx_TICAN_2 1;
BA_ "GenSigSendType" SG_ 2348992704 ASR_BC_Act 1;
BA_ "GenSigSendType" SG_ 2348992704 ASR_EC_Act 1;
BA_ "GenSigSendType" SG_ 2348992704 BrLightSw 1;
BA_ "GenSigSendType" SG_ 2348992704 VehType_EBS11_Tx_TICAN_2 1;
BA_ "GenSigSendType" SG_ 2348992704 VehVDCAct 1;
BA_ "GenSigSendType" SG_ 2348992704 ServBrDem 1;
BA_ "GenSigSendType" SG_ 2348992704 ParkBrDem_EBS11_Tx_TICAN_2 1;
BA_ "GenSigSendType" SG_ 2348992704 RetDem 1;
BA_ "GenSigSendType" SG_ 2348992704 RelDemFrontLeft 1;
BA_ "GenSigSendType" SG_ 2348992704 RelDemRearRight 1;
BA_ "VFrameFormat" BO_ 2348992696 1;
BA_ "GenSigSendType" SG_ 2348992696 VehABSAct_EBS11_Tx_TICAN_3 1;
BA_ "GenSigSendType" SG_ 2348992696 VehRetCtrAct_EBS11_Tx_TICAN_3 1;
BA_ "GenSigSendType" SG_ 2348992696 ASR_BC_Act 1;
BA_ "GenSigSendType" SG_ 2348992696 ASR_EC_Act 1;
BA_ "GenSigSendType" SG_ 2348992696 BrLightSw 1;
BA_ "GenSigSendType" SG_ 2348992696 VehType_EBS11_Tx_TICAN_3 1;
BA_ "GenSigSendType" SG_ 2348992696 VehVDCAct 1;
BA_ "GenSigSendType" SG_ 2348992696 ServBrDem 1;
BA_ "GenSigSendType" SG_ 2348992696 ParkBrDem_EBS11_Tx_TICAN_3 1;
BA_ "GenSigSendType" SG_ 2348992696 RetDem 1;
BA_ "GenSigSendType" SG_ 2348992696 RelDemFrontLeft 1;
BA_ "GenSigSendType" SG_ 2348992696 RelDemRearRight 1;
BA_ "VFrameFormat" BO_ 2348992688 1;
BA_ "GenSigSendType" SG_ 2348992688 VehABSAct_EBS11_Tx_TICAN_4 1;
BA_ "GenSigSendType" SG_ 2348992688 VehRetCtrAct_EBS11_Tx_TICAN_4 1;
BA_ "GenSigSendType" SG_ 2348992688 ASR_BC_Act 1;
BA_ "GenSigSendType" SG_ 2348992688 ASR_EC_Act 1;
BA_ "GenSigSendType" SG_ 2348992688 BrLightSw 1;
BA_ "GenSigSendType" SG_ 2348992688 VehType_EBS11_Tx_TICAN_4 1;
BA_ "GenSigSendType" SG_ 2348992688 VehVDCAct 1;
BA_ "GenSigSendType" SG_ 2348992688 ServBrDem 1;
BA_ "GenSigSendType" SG_ 2348992688 ParkBrDem_EBS11_Tx_TICAN_4 1;
BA_ "GenSigSendType" SG_ 2348992688 RetDem 1;
BA_ "GenSigSendType" SG_ 2348992688 RelDemFrontLeft 1;
BA_ "GenSigSendType" SG_ 2348992688 RelDemRearRight 1;
BA_ "VFrameFormat" BO_ 2348992680 1;
BA_ "GenSigSendType" SG_ 2348992680 VehABSAct_EBS11_Tx_TICAN_5 1;
BA_ "GenSigSendType" SG_ 2348992680 VehRetCtrAct_EBS11_Tx_TICAN_5 1;
BA_ "GenSigSendType" SG_ 2348992680 ASR_BC_Act 1;
BA_ "GenSigSendType" SG_ 2348992680 ASR_EC_Act 1;
BA_ "GenSigSendType" SG_ 2348992680 BrLightSw 1;
BA_ "GenSigSendType" SG_ 2348992680 VehType_EBS11_Tx_TICAN_5 1;
BA_ "GenSigSendType" SG_ 2348992680 VehVDCAct 1;
BA_ "GenSigSendType" SG_ 2348992680 ServBrDem 1;
BA_ "GenSigSendType" SG_ 2348992680 ParkBrDem_EBS11_Tx_TICAN_5 1;
BA_ "GenSigSendType" SG_ 2348992680 RetDem 1;
BA_ "GenSigSendType" SG_ 2348992680 RelDemFrontLeft 1;
BA_ "GenSigSendType" SG_ 2348992680 RelDemRearRight 1;
BA_ "VFrameFormat" BO_ 2566834632 1;
BA_ "GenSigSendType" SG_ 2566834632 VehRetCtrAct_EBS12_Tx_TICAN 1;
BA_ "GenSigSendType" SG_ 2566834632 VehROPEna 1;
BA_ "GenSigSendType" SG_ 2566834632 VehYCEna 1;
BA_ "GenSigSendType" SG_ 2566834632 TrlROPEna 1;
BA_ "GenSigSendType" SG_ 2566834632 TrlYCEna 1;
BA_ "GenSigSendType" SG_ 2566834632 RevGearSta 1;
BA_ "GenSigSendType" SG_ 2566834632 EmrgBrkReq 1;
BA_ "GenSigSendType" SG_ 2566834632 TwoElBrDem 1;
BA_ "GenSigSendType" SG_ 2566834632 ABSOffrReq 1;
BA_ "GenSigSendType" SG_ 2566834632 PneuCtrLine 1;
BA_ "GenSigSendType" SG_ 2566834632 TractorLSF 1;
BA_ "GenSigInactiveValue" SG_ 2566834632 RoadCurve 32000;
BA_ "GenSigStartValue" SG_ 2566834632 RoadCurve 32000;
BA_ "GenSigSendType" SG_ 2566834632 RoadCurve 1;
BA_ "GenSigSendType" SG_ 2566834632 VehWhlSpeed 1;
BA_ "VFrameFormat" BO_ 2566834624 1;
BA_ "GenSigSendType" SG_ 2566834624 VehRetCtrAct_EBS12_Tx_TICAN_2 1;
BA_ "GenSigSendType" SG_ 2566834624 VehROPEna 1;
BA_ "GenSigSendType" SG_ 2566834624 VehYCEna 1;
BA_ "GenSigSendType" SG_ 2566834624 TrlROPEna 1;
BA_ "GenSigSendType" SG_ 2566834624 TrlYCEna 1;
BA_ "GenSigSendType" SG_ 2566834624 RevGearSta 1;
BA_ "GenSigSendType" SG_ 2566834624 EmrgBrkReq 1;
BA_ "GenSigSendType" SG_ 2566834624 TwoElBrDem 1;
BA_ "GenSigSendType" SG_ 2566834624 ABSOffrReq 1;
BA_ "GenSigSendType" SG_ 2566834624 PneuCtrLine 1;
BA_ "GenSigSendType" SG_ 2566834624 TractorLSF 1;
BA_ "GenSigInactiveValue" SG_ 2566834624 RoadCurve 32000;
BA_ "GenSigStartValue" SG_ 2566834624 RoadCurve 32000;
BA_ "GenSigSendType" SG_ 2566834624 RoadCurve 1;
BA_ "GenSigSendType" SG_ 2566834624 VehWhlSpeed 1;
BA_ "VFrameFormat" BO_ 2566834616 1;
BA_ "GenSigSendType" SG_ 2566834616 VehRetCtrAct_EBS12_Tx_TICAN_3 1;
BA_ "GenSigSendType" SG_ 2566834616 VehROPEna 1;
BA_ "GenSigSendType" SG_ 2566834616 VehYCEna 1;
BA_ "GenSigSendType" SG_ 2566834616 TrlROPEna 1;
BA_ "GenSigSendType" SG_ 2566834616 TrlYCEna 1;
BA_ "GenSigSendType" SG_ 2566834616 RevGearSta 1;
BA_ "GenSigSendType" SG_ 2566834616 EmrgBrkReq 1;
BA_ "GenSigSendType" SG_ 2566834616 TwoElBrDem 1;
BA_ "GenSigSendType" SG_ 2566834616 ABSOffrReq 1;
BA_ "GenSigSendType" SG_ 2566834616 PneuCtrLine 1;
BA_ "GenSigSendType" SG_ 2566834616 TractorLSF 1;
BA_ "GenSigInactiveValue" SG_ 2566834616 RoadCurve 32000;
BA_ "GenSigStartValue" SG_ 2566834616 RoadCurve 32000;
BA_ "GenSigSendType" SG_ 2566834616 RoadCurve 1;
BA_ "GenSigSendType" SG_ 2566834616 VehWhlSpeed 1;
BA_ "VFrameFormat" BO_ 2566834608 1;
BA_ "GenSigSendType" SG_ 2566834608 VehRetCtrAct_EBS12_Tx_TICAN_4 1;
BA_ "GenSigSendType" SG_ 2566834608 VehROPEna 1;
BA_ "GenSigSendType" SG_ 2566834608 VehYCEna 1;
BA_ "GenSigSendType" SG_ 2566834608 TrlROPEna 1;
BA_ "GenSigSendType" SG_ 2566834608 TrlYCEna 1;
BA_ "GenSigSendType" SG_ 2566834608 RevGearSta 1;
BA_ "GenSigSendType" SG_ 2566834608 EmrgBrkReq 1;
BA_ "GenSigSendType" SG_ 2566834608 TwoElBrDem 1;
BA_ "GenSigSendType" SG_ 2566834608 ABSOffrReq 1;
BA_ "GenSigSendType" SG_ 2566834608 PneuCtrLine 1;
BA_ "GenSigSendType" SG_ 2566834608 TractorLSF 1;
BA_ "GenSigInactiveValue" SG_ 2566834608 RoadCurve 32000;
BA_ "GenSigStartValue" SG_ 2566834608 RoadCurve 32000;
BA_ "GenSigSendType" SG_ 2566834608 RoadCurve 1;
BA_ "GenSigSendType" SG_ 2566834608 VehWhlSpeed 1;
BA_ "VFrameFormat" BO_ 2566834600 1;
BA_ "GenSigSendType" SG_ 2566834600 VehRetCtrAct_EBS12_Tx_TICAN_5 1;
BA_ "GenSigSendType" SG_ 2566834600 VehROPEna 1;
BA_ "GenSigSendType" SG_ 2566834600 VehYCEna 1;
BA_ "GenSigSendType" SG_ 2566834600 TrlROPEna 1;
BA_ "GenSigSendType" SG_ 2566834600 TrlYCEna 1;
BA_ "GenSigSendType" SG_ 2566834600 RevGearSta 1;
BA_ "GenSigSendType" SG_ 2566834600 EmrgBrkReq 1;
BA_ "GenSigSendType" SG_ 2566834600 TwoElBrDem 1;
BA_ "GenSigSendType" SG_ 2566834600 ABSOffrReq 1;
BA_ "GenSigSendType" SG_ 2566834600 PneuCtrLine 1;
BA_ "GenSigSendType" SG_ 2566834600 TractorLSF 1;
BA_ "GenSigInactiveValue" SG_ 2566834600 RoadCurve 32000;
BA_ "GenSigStartValue" SG_ 2566834600 RoadCurve 32000;
BA_ "GenSigSendType" SG_ 2566834600 RoadCurve 1;
BA_ "GenSigSendType" SG_ 2566834600 VehWhlSpeed 1;
BA_ "VFrameFormat" BO_ 2349015240 1;
BA_ "GenSigSendType" SG_ 2349015240 VehABSAct_EBS21_Tx_TICAN 1;
BA_ "GenSigSendType" SG_ 2349015240 VehRetCtrAct_EBS21_Tx_TICAN 1;
BA_ "GenSigSendType" SG_ 2349015240 ServBrAct_EBS21_Tx_TICAN 1;
BA_ "GenSigSendType" SG_ 2349015240 AutoBrAct_EBS21_Tx_TICAN 1;
BA_ "GenSigSendType" SG_ 2349015240 VDC_Act 1;
BA_ "GenSigSendType" SG_ 2349015240 BrkDistrSupp 1;
BA_ "GenSigSendType" SG_ 2349015240 v_WhBased 1;
BA_ "GenSigInactiveValue" SG_ 2349015240 PrcRetPeakTq 125;
BA_ "GenSigStartValue" SG_ 2349015240 PrcRetPeakTq 125;
BA_ "GenSigSendType" SG_ 2349015240 PrcRetPeakTq 1;
BA_ "GenSigInactiveValue" SG_ 2349015240 WhSpeedDiff 32000;
BA_ "GenSigStartValue" SG_ 2349015240 WhSpeedDiff 32000;
BA_ "GenSigSendType" SG_ 2349015240 WhSpeedDiff 1;
BA_ "GenSigInactiveValue" SG_ 2349015240 LatAcc 125;
BA_ "GenSigStartValue" SG_ 2349015240 LatAcc 125;
BA_ "GenSigSendType" SG_ 2349015240 LatAcc 1;
BA_ "VFrameFormat" BO_ 2349058240 1;
BA_ "GenSigSendType" SG_ 2349058240 VehABSAct_EBS21_Tx_TICAN_2 1;
BA_ "GenSigSendType" SG_ 2349058240 VehRetCtrAct_EBS21_Tx_TICAN_2 1;
BA_ "GenSigSendType" SG_ 2349058240 ServBrAct_EBS21_Tx_TICAN_2 1;
BA_ "GenSigSendType" SG_ 2349058240 AutoBrAct_EBS21_Tx_TICAN_2 1;
BA_ "GenSigSendType" SG_ 2349058240 VDC_Act 1;
BA_ "GenSigSendType" SG_ 2349058240 BrkDistrSupp 1;
BA_ "GenSigSendType" SG_ 2349058240 v_WhBased 1;
BA_ "GenSigInactiveValue" SG_ 2349058240 PrcRetPeakTq 125;
BA_ "GenSigStartValue" SG_ 2349058240 PrcRetPeakTq 125;
BA_ "GenSigSendType" SG_ 2349058240 PrcRetPeakTq 1;
BA_ "GenSigInactiveValue" SG_ 2349058240 WhSpeedDiff 32000;
BA_ "GenSigStartValue" SG_ 2349058240 WhSpeedDiff 32000;
BA_ "GenSigSendType" SG_ 2349058240 WhSpeedDiff 1;
BA_ "GenSigInactiveValue" SG_ 2349058240 LatAcc 125;
BA_ "GenSigStartValue" SG_ 2349058240 LatAcc 125;
BA_ "GenSigSendType" SG_ 2349058240 LatAcc 1;
BA_ "VFrameFormat" BO_ 2349056184 1;
BA_ "GenSigSendType" SG_ 2349056184 VehABSAct_EBS21_Tx_TICAN_3 1;
BA_ "GenSigSendType" SG_ 2349056184 VehRetCtrAct_EBS21_Tx_TICAN_3 1;
BA_ "GenSigSendType" SG_ 2349056184 ServBrAct_EBS21_Tx_TICAN_3 1;
BA_ "GenSigSendType" SG_ 2349056184 AutoBrAct_EBS21_Tx_TICAN_3 1;
BA_ "GenSigSendType" SG_ 2349056184 VDC_Act 1;
BA_ "GenSigSendType" SG_ 2349056184 BrkDistrSupp 1;
BA_ "GenSigSendType" SG_ 2349056184 v_WhBased 1;
BA_ "GenSigInactiveValue" SG_ 2349056184 PrcRetPeakTq 125;
BA_ "GenSigStartValue" SG_ 2349056184 PrcRetPeakTq 125;
BA_ "GenSigSendType" SG_ 2349056184 PrcRetPeakTq 1;
BA_ "GenSigInactiveValue" SG_ 2349056184 WhSpeedDiff 32000;
BA_ "GenSigStartValue" SG_ 2349056184 WhSpeedDiff 32000;
BA_ "GenSigSendType" SG_ 2349056184 WhSpeedDiff 1;
BA_ "GenSigInactiveValue" SG_ 2349056184 LatAcc 125;
BA_ "GenSigStartValue" SG_ 2349056184 LatAcc 125;
BA_ "GenSigSendType" SG_ 2349056184 LatAcc 1;
BA_ "VFrameFormat" BO_ 2349054128 1;
BA_ "GenSigSendType" SG_ 2349054128 VehABSAct_EBS21_Tx_TICAN_4 1;
BA_ "GenSigSendType" SG_ 2349054128 VehRetCtrAct_EBS21_Tx_TICAN_4 1;
BA_ "GenSigSendType" SG_ 2349054128 ServBrAct_EBS21_Tx_TICAN_4 1;
BA_ "GenSigSendType" SG_ 2349054128 AutoBrAct_EBS21_Tx_TICAN_4 1;
BA_ "GenSigSendType" SG_ 2349054128 VDC_Act 1;
BA_ "GenSigSendType" SG_ 2349054128 BrkDistrSupp 1;
BA_ "GenSigSendType" SG_ 2349054128 v_WhBased 1;
BA_ "GenSigInactiveValue" SG_ 2349054128 PrcRetPeakTq 125;
BA_ "GenSigStartValue" SG_ 2349054128 PrcRetPeakTq 125;
BA_ "GenSigSendType" SG_ 2349054128 PrcRetPeakTq 1;
BA_ "GenSigInactiveValue" SG_ 2349054128 WhSpeedDiff 32000;
BA_ "GenSigStartValue" SG_ 2349054128 WhSpeedDiff 32000;
BA_ "GenSigSendType" SG_ 2349054128 WhSpeedDiff 1;
BA_ "GenSigInactiveValue" SG_ 2349054128 LatAcc 125;
BA_ "GenSigStartValue" SG_ 2349054128 LatAcc 125;
BA_ "GenSigSendType" SG_ 2349054128 LatAcc 1;
BA_ "VFrameFormat" BO_ 2349052072 1;
BA_ "GenSigSendType" SG_ 2349052072 VehABSAct_EBS21_Tx_TICAN_5 1;
BA_ "GenSigSendType" SG_ 2349052072 VehRetCtrAct_EBS21_Tx_TICAN_5 1;
BA_ "GenSigSendType" SG_ 2349052072 ServBrAct_EBS21_Tx_TICAN_5 1;
BA_ "GenSigSendType" SG_ 2349052072 AutoBrAct_EBS21_Tx_TICAN_5 1;
BA_ "GenSigSendType" SG_ 2349052072 VDC_Act 1;
BA_ "GenSigSendType" SG_ 2349052072 BrkDistrSupp 1;
BA_ "GenSigSendType" SG_ 2349052072 v_WhBased 1;
BA_ "GenSigInactiveValue" SG_ 2349052072 PrcRetPeakTq 125;
BA_ "GenSigStartValue" SG_ 2349052072 PrcRetPeakTq 125;
BA_ "GenSigSendType" SG_ 2349052072 PrcRetPeakTq 1;
BA_ "GenSigInactiveValue" SG_ 2349052072 WhSpeedDiff 32000;
BA_ "GenSigStartValue" SG_ 2349052072 WhSpeedDiff 32000;
BA_ "GenSigSendType" SG_ 2349052072 WhSpeedDiff 1;
BA_ "GenSigInactiveValue" SG_ 2349052072 LatAcc 125;
BA_ "GenSigStartValue" SG_ 2349052072 LatAcc 125;
BA_ "GenSigSendType" SG_ 2349052072 LatAcc 1;
BA_ "VFrameFormat" BO_ 2566833352 1;
BA_ "GenSigSendType" SG_ 2566833352 VehABSAct_EBS22_Tx_TICAN 1;
BA_ "GenSigSendType" SG_ 2566833352 VehRetCtrAct_EBS22_Tx_TICAN 1;
BA_ "GenSigSendType" SG_ 2566833352 ServBrAct_EBS22_Tx_TICAN 1;
BA_ "GenSigSendType" SG_ 2566833352 AutoBrAct_EBS22_Tx_TICAN 1;
BA_ "GenSigSendType" SG_ 2566833352 ElSupSuff 1;
BA_ "GenSigSendType" SG_ 2566833352 RedWLReq 1;
BA_ "GenSigSendType" SG_ 2566833352 AmbWLReq 1;
BA_ "GenSigSendType" SG_ 2566833352 ElSupNoBrSys 1;
BA_ "GenSigSendType" SG_ 2566833352 SpringBrInst 1;
BA_ "GenSigSendType" SG_ 2566833352 ElLoadProp 1;
BA_ "GenSigSendType" SG_ 2566833352 VehType_EBS22_Tx_TICAN 1;
BA_ "GenSigSendType" SG_ 2566833352 SprBrEng 1;
BA_ "GenSigSendType" SG_ 2566833352 LoadRampAss 1;
BA_ "GenSigSendType" SG_ 2566833352 SupBrReq 1;
BA_ "GenSigSendType" SG_ 2566833352 StopLampReq 1;
BA_ "GenSigSendType" SG_ 2566833352 ElBrakeSupp 1;
BA_ "GenSigSendType" SG_ 2566833352 AxLoadSum 1;
BA_ "GenSigSendType" SG_ 2566833352 RefRetTrq 1;
BA_ "VFrameFormat" BO_ 2566833344 1;
BA_ "GenSigSendType" SG_ 2566833344 VehABSAct_EBS22_Tx_TICAN_2 1;
BA_ "GenSigSendType" SG_ 2566833344 VehRetCtrAct_EBS22_Tx_TICAN_2 1;
BA_ "GenSigSendType" SG_ 2566833344 ServBrAct_EBS22_Tx_TICAN_2 1;
BA_ "GenSigSendType" SG_ 2566833344 AutoBrAct_EBS22_Tx_TICAN_2 1;
BA_ "GenSigSendType" SG_ 2566833344 ElSupSuff 1;
BA_ "GenSigSendType" SG_ 2566833344 RedWLReq 1;
BA_ "GenSigSendType" SG_ 2566833344 AmbWLReq 1;
BA_ "GenSigSendType" SG_ 2566833344 ElSupNoBrSys 1;
BA_ "GenSigSendType" SG_ 2566833344 SpringBrInst 1;
BA_ "GenSigSendType" SG_ 2566833344 ElLoadProp 1;
BA_ "GenSigSendType" SG_ 2566833344 VehType_EBS22_Tx_TICAN_2 1;
BA_ "GenSigSendType" SG_ 2566833344 SprBrEng 1;
BA_ "GenSigSendType" SG_ 2566833344 LoadRampAss 1;
BA_ "GenSigSendType" SG_ 2566833344 SupBrReq 1;
BA_ "GenSigSendType" SG_ 2566833344 StopLampReq 1;
BA_ "GenSigSendType" SG_ 2566833344 ElBrakeSupp 1;
BA_ "GenSigSendType" SG_ 2566833344 AxLoadSum 1;
BA_ "GenSigSendType" SG_ 2566833344 RefRetTrq 1;
BA_ "VFrameFormat" BO_ 2566833336 1;
BA_ "GenSigSendType" SG_ 2566833336 VehABSAct_EBS22_Tx_TICAN_3 1;
BA_ "GenSigSendType" SG_ 2566833336 VehRetCtrAct_EBS22_Tx_TICAN_3 1;
BA_ "GenSigSendType" SG_ 2566833336 ServBrAct_EBS22_Tx_TICAN_3 1;
BA_ "GenSigSendType" SG_ 2566833336 AutoBrAct_EBS22_Tx_TICAN_3 1;
BA_ "GenSigSendType" SG_ 2566833336 ElSupSuff 1;
BA_ "GenSigSendType" SG_ 2566833336 RedWLReq 1;
BA_ "GenSigSendType" SG_ 2566833336 AmbWLReq 1;
BA_ "GenSigSendType" SG_ 2566833336 ElSupNoBrSys 1;
BA_ "GenSigSendType" SG_ 2566833336 SpringBrInst 1;
BA_ "GenSigSendType" SG_ 2566833336 ElLoadProp 1;
BA_ "GenSigSendType" SG_ 2566833336 VehType_EBS22_Tx_TICAN_3 1;
BA_ "GenSigSendType" SG_ 2566833336 SprBrEng 1;
BA_ "GenSigSendType" SG_ 2566833336 LoadRampAss 1;
BA_ "GenSigSendType" SG_ 2566833336 SupBrReq 1;
BA_ "GenSigSendType" SG_ 2566833336 StopLampReq 1;
BA_ "GenSigSendType" SG_ 2566833336 ElBrakeSupp 1;
BA_ "GenSigSendType" SG_ 2566833336 AxLoadSum 1;
BA_ "GenSigSendType" SG_ 2566833336 RefRetTrq 1;
BA_ "VFrameFormat" BO_ 2566833328 1;
BA_ "GenSigSendType" SG_ 2566833328 VehABSAct_EBS22_Tx_TICAN_4 1;
BA_ "GenSigSendType" SG_ 2566833328 VehRetCtrAct_EBS22_Tx_TICAN_4 1;
BA_ "GenSigSendType" SG_ 2566833328 ServBrAct_EBS22_Tx_TICAN_4 1;
BA_ "GenSigSendType" SG_ 2566833328 AutoBrAct_EBS22_Tx_TICAN_4 1;
BA_ "GenSigSendType" SG_ 2566833328 ElSupSuff 1;
BA_ "GenSigSendType" SG_ 2566833328 RedWLReq 1;
BA_ "GenSigSendType" SG_ 2566833328 AmbWLReq 1;
BA_ "GenSigSendType" SG_ 2566833328 ElSupNoBrSys 1;
BA_ "GenSigSendType" SG_ 2566833328 SpringBrInst 1;
BA_ "GenSigSendType" SG_ 2566833328 ElLoadProp 1;
BA_ "GenSigSendType" SG_ 2566833328 VehType_EBS22_Tx_TICAN_4 1;
BA_ "GenSigSendType" SG_ 2566833328 SprBrEng 1;
BA_ "GenSigSendType" SG_ 2566833328 LoadRampAss 1;
BA_ "GenSigSendType" SG_ 2566833328 SupBrReq 1;
BA_ "GenSigSendType" SG_ 2566833328 StopLampReq 1;
BA_ "GenSigSendType" SG_ 2566833328 ElBrakeSupp 1;
BA_ "GenSigSendType" SG_ 2566833328 AxLoadSum 1;
BA_ "GenSigSendType" SG_ 2566833328 RefRetTrq 1;
BA_ "VFrameFormat" BO_ 2566833320 1;
BA_ "GenSigSendType" SG_ 2566833320 VehABSAct_EBS22_Tx_TICAN_5 1;
BA_ "GenSigSendType" SG_ 2566833320 VehRetCtrAct_EBS22_Tx_TICAN_5 1;
BA_ "GenSigSendType" SG_ 2566833320 ServBrAct_EBS22_Tx_TICAN_5 1;
BA_ "GenSigSendType" SG_ 2566833320 AutoBrAct_EBS22_Tx_TICAN_5 1;
BA_ "GenSigSendType" SG_ 2566833320 ElSupSuff 1;
BA_ "GenSigSendType" SG_ 2566833320 RedWLReq 1;
BA_ "GenSigSendType" SG_ 2566833320 AmbWLReq 1;
BA_ "GenSigSendType" SG_ 2566833320 ElSupNoBrSys 1;
BA_ "GenSigSendType" SG_ 2566833320 SpringBrInst 1;
BA_ "GenSigSendType" SG_ 2566833320 ElLoadProp 1;
BA_ "GenSigSendType" SG_ 2566833320 VehType_EBS22_Tx_TICAN_5 1;
BA_ "GenSigSendType" SG_ 2566833320 SprBrEng 1;
BA_ "GenSigSendType" SG_ 2566833320 LoadRampAss 1;
BA_ "GenSigSendType" SG_ 2566833320 SupBrReq 1;
BA_ "GenSigSendType" SG_ 2566833320 StopLampReq 1;
BA_ "GenSigSendType" SG_ 2566833320 ElBrakeSupp 1;
BA_ "GenSigSendType" SG_ 2566833320 AxLoadSum 1;
BA_ "GenSigSendType" SG_ 2566833320 RefRetTrq 1;
BA_ "VFrameFormat" BO_ 2566833864 1;
BA_ "GenSigSendType" SG_ 2566833864 TyrePrSuf 1;
BA_ "GenSigSendType" SG_ 2566833864 BrLinSuf 1;
BA_ "GenSigSendType" SG_ 2566833864 BrTempSt 1;
BA_ "GenSigSendType" SG_ 2566833864 PneuSupSuf 1;
BA_ "GenSigSendType" SG_ 2566833864 TyreId_Press 1;
BA_ "GenSigSendType" SG_ 2566833864 TyreId_Lining 1;
BA_ "GenSigSendType" SG_ 2566833864 TyreId_Temp 1;
BA_ "GenSigSendType" SG_ 2566833864 TyrePress 1;
BA_ "GenSigSendType" SG_ 2566833864 BrLin 1;
BA_ "GenSigSendType" SG_ 2566833864 BrTemp 1;
BA_ "GenSigSendType" SG_ 2566833864 PneuSupPr 1;
BA_ "VFrameFormat" BO_ 2566833856 1;
BA_ "GenSigSendType" SG_ 2566833856 TyrePrSuf 1;
BA_ "GenSigSendType" SG_ 2566833856 BrLinSuf 1;
BA_ "GenSigSendType" SG_ 2566833856 BrTempSt 1;
BA_ "GenSigSendType" SG_ 2566833856 PneuSupSuf 1;
BA_ "GenSigSendType" SG_ 2566833856 TyreId_Press 1;
BA_ "GenSigSendType" SG_ 2566833856 TyreId_Lining 1;
BA_ "GenSigSendType" SG_ 2566833856 TyreId_Temp 1;
BA_ "GenSigSendType" SG_ 2566833856 TyrePress 1;
BA_ "GenSigSendType" SG_ 2566833856 BrLin 1;
BA_ "GenSigSendType" SG_ 2566833856 BrTemp 1;
BA_ "GenSigSendType" SG_ 2566833856 PneuSupPr 1;
BA_ "VFrameFormat" BO_ 2566833848 1;
BA_ "GenSigSendType" SG_ 2566833848 TyrePrSuf 1;
BA_ "GenSigSendType" SG_ 2566833848 BrLinSuf 1;
BA_ "GenSigSendType" SG_ 2566833848 BrTempSt 1;
BA_ "GenSigSendType" SG_ 2566833848 PneuSupSuf 1;
BA_ "GenSigSendType" SG_ 2566833848 TyreId_Press 1;
BA_ "GenSigSendType" SG_ 2566833848 TyreId_Lining 1;
BA_ "GenSigSendType" SG_ 2566833848 TyreId_Temp 1;
BA_ "GenSigSendType" SG_ 2566833848 TyrePress 1;
BA_ "GenSigSendType" SG_ 2566833848 BrLin 1;
BA_ "GenSigSendType" SG_ 2566833848 BrTemp 1;
BA_ "GenSigSendType" SG_ 2566833848 PneuSupPr 1;
BA_ "VFrameFormat" BO_ 2566833840 1;
BA_ "GenSigSendType" SG_ 2566833840 TyrePrSuf 1;
BA_ "GenSigSendType" SG_ 2566833840 BrLinSuf 1;
BA_ "GenSigSendType" SG_ 2566833840 BrTempSt 1;
BA_ "GenSigSendType" SG_ 2566833840 PneuSupSuf 1;
BA_ "GenSigSendType" SG_ 2566833840 TyreId_Press 1;
BA_ "GenSigSendType" SG_ 2566833840 TyreId_Lining 1;
BA_ "GenSigSendType" SG_ 2566833840 TyreId_Temp 1;
BA_ "GenSigSendType" SG_ 2566833840 TyrePress 1;
BA_ "GenSigSendType" SG_ 2566833840 BrLin 1;
BA_ "GenSigSendType" SG_ 2566833840 BrTemp 1;
BA_ "GenSigSendType" SG_ 2566833840 PneuSupPr 1;
BA_ "VFrameFormat" BO_ 2566833832 1;
BA_ "GenSigSendType" SG_ 2566833832 TyrePrSuf 1;
BA_ "GenSigSendType" SG_ 2566833832 BrLinSuf 1;
BA_ "GenSigSendType" SG_ 2566833832 BrTempSt 1;
BA_ "GenSigSendType" SG_ 2566833832 PneuSupSuf 1;
BA_ "GenSigSendType" SG_ 2566833832 TyreId_Press 1;
BA_ "GenSigSendType" SG_ 2566833832 TyreId_Lining 1;
BA_ "GenSigSendType" SG_ 2566833832 TyreId_Temp 1;
BA_ "GenSigSendType" SG_ 2566833832 TyrePress 1;
BA_ "GenSigSendType" SG_ 2566833832 BrLin 1;
BA_ "GenSigSendType" SG_ 2566833832 BrTemp 1;
BA_ "GenSigSendType" SG_ 2566833832 PneuSupPr 1;
BA_ "VFrameFormat" BO_ 2566757064 1;
BA_ "GenSigSendType" SG_ 2566757064 GeomDataIndex 1;
BA_ "GenSigSendType" SG_ 2566757064 GeomDataContent 1;
BA_ "VFrameFormat" BO_ 2566757056 1;
BA_ "GenSigSendType" SG_ 2566757056 GeomDataIndex 1;
BA_ "GenSigSendType" SG_ 2566757056 GeomDataContent 1;
BA_ "VFrameFormat" BO_ 2566757048 1;
BA_ "GenSigSendType" SG_ 2566757048 GeomDataIndex 1;
BA_ "GenSigSendType" SG_ 2566757048 GeomDataContent 1;
BA_ "VFrameFormat" BO_ 2566757040 1;
BA_ "GenSigSendType" SG_ 2566757040 GeomDataIndex 1;
BA_ "GenSigSendType" SG_ 2566757040 GeomDataContent 1;
BA_ "VFrameFormat" BO_ 2566757032 1;
BA_ "GenSigSendType" SG_ 2566757032 GeomDataIndex 1;
BA_ "GenSigSendType" SG_ 2566757032 GeomDataContent 1;
BA_ "VFrameFormat" BO_ 2565873864 1;
BA_ "GenSigSendType" SG_ 2565873864 PBrCyl_A1L 1;
BA_ "GenSigSendType" SG_ 2565873864 PBrCyl_A1R 1;
BA_ "GenSigSendType" SG_ 2565873864 PBrCyl_A2L 1;
BA_ "GenSigSendType" SG_ 2565873864 PBrCyl_A2R 1;
BA_ "GenSigSendType" SG_ 2565873864 PBrCyl_A3L 1;
BA_ "GenSigSendType" SG_ 2565873864 PBrCyl_A3R 1;
BA_ "GenSigSendType" SG_ 2565873864 ROPEna 1;
BA_ "GenSigSendType" SG_ 2565873864 YCEna 1;
BA_ "VFrameFormat" BO_ 2565873856 1;
BA_ "GenSigSendType" SG_ 2565873856 PBrCyl_A1L 1;
BA_ "GenSigSendType" SG_ 2565873856 PBrCyl_A1R 1;
BA_ "GenSigSendType" SG_ 2565873856 PBrCyl_A2L 1;
BA_ "GenSigSendType" SG_ 2565873856 PBrCyl_A2R 1;
BA_ "GenSigSendType" SG_ 2565873856 PBrCyl_A3L 1;
BA_ "GenSigSendType" SG_ 2565873856 PBrCyl_A3R 1;
BA_ "GenSigSendType" SG_ 2565873856 ROPEna 1;
BA_ "GenSigSendType" SG_ 2565873856 YCEna 1;
BA_ "VFrameFormat" BO_ 2565873848 1;
BA_ "GenSigSendType" SG_ 2565873848 PBrCyl_A1L 1;
BA_ "GenSigSendType" SG_ 2565873848 PBrCyl_A1R 1;
BA_ "GenSigSendType" SG_ 2565873848 PBrCyl_A2L 1;
BA_ "GenSigSendType" SG_ 2565873848 PBrCyl_A2R 1;
BA_ "GenSigSendType" SG_ 2565873848 PBrCyl_A3L 1;
BA_ "GenSigSendType" SG_ 2565873848 PBrCyl_A3R 1;
BA_ "GenSigSendType" SG_ 2565873848 ROPEna 1;
BA_ "GenSigSendType" SG_ 2565873848 YCEna 1;
BA_ "VFrameFormat" BO_ 2565873840 1;
BA_ "GenSigSendType" SG_ 2565873840 PBrCyl_A1L 1;
BA_ "GenSigSendType" SG_ 2565873840 PBrCyl_A1R 1;
BA_ "GenSigSendType" SG_ 2565873840 PBrCyl_A2L 1;
BA_ "GenSigSendType" SG_ 2565873840 PBrCyl_A2R 1;
BA_ "GenSigSendType" SG_ 2565873840 PBrCyl_A3L 1;
BA_ "GenSigSendType" SG_ 2565873840 PBrCyl_A3R 1;
BA_ "GenSigSendType" SG_ 2565873840 ROPEna 1;
BA_ "GenSigSendType" SG_ 2565873840 YCEna 1;
BA_ "VFrameFormat" BO_ 2565873832 1;
BA_ "GenSigSendType" SG_ 2565873832 PBrCyl_A1L 1;
BA_ "GenSigSendType" SG_ 2565873832 PBrCyl_A1R 1;
BA_ "GenSigSendType" SG_ 2565873832 PBrCyl_A2L 1;
BA_ "GenSigSendType" SG_ 2565873832 PBrCyl_A2R 1;
BA_ "GenSigSendType" SG_ 2565873832 PBrCyl_A3L 1;
BA_ "GenSigSendType" SG_ 2565873832 PBrCyl_A3R 1;
BA_ "GenSigSendType" SG_ 2565873832 ROPEna 1;
BA_ "GenSigSendType" SG_ 2565873832 YCEna 1;
BA_ "VFrameFormat" BO_ 2364547016 1;
BA_ "GenSigSendType" SG_ 2364547016 V_A1L 1;
BA_ "GenSigSendType" SG_ 2364547016 V_A1R 1;
BA_ "VFrameFormat" BO_ 2364547008 1;
BA_ "GenSigSendType" SG_ 2364547008 V_A1L 1;
BA_ "GenSigSendType" SG_ 2364547008 V_A1R 1;
BA_ "VFrameFormat" BO_ 2364547000 1;
BA_ "GenSigSendType" SG_ 2364547000 V_A1L 1;
BA_ "GenSigSendType" SG_ 2364547000 V_A1R 1;
BA_ "VFrameFormat" BO_ 2364546992 1;
BA_ "GenSigSendType" SG_ 2364546992 V_A1L 1;
BA_ "GenSigSendType" SG_ 2364546992 V_A1R 1;
BA_ "VFrameFormat" BO_ 2364546984 1;
BA_ "GenSigSendType" SG_ 2364546984 V_A1L 1;
BA_ "GenSigSendType" SG_ 2364546984 V_A1R 1;
BA_ "VFrameFormat" BO_ 2565130440 1;
BA_ "GenSigSendType" SG_ 2565130440 RideHeiReq_RGE11_Tx_TICAN 1;
BA_ "GenSigSendType" SG_ 2565130440 LevChgReq_FA_RGE11_Tx_TICAN 1;
BA_ "GenSigSendType" SG_ 2565130440 LevChgReq_RA_RGE11_Tx_TICAN 1;
BA_ "GenSigSendType" SG_ 2565130440 TracHelpReq_RGE11_Tx_TICAN 1;
BA_ "GenSigSendType" SG_ 2565130440 LiftAxPos1Req_RGE11_Tx_TICAN 1;
BA_ "GenSigSendType" SG_ 2565130440 LiftAxPos2Req_RGE11_Tx_TICAN 1;
BA_ "GenSigSendType" SG_ 2565130440 StrAxLockReq_RGE11_Tx_TICAN 1;
BA_ "GenSigSendType" SG_ 2565130440 RampLevReq_RGE11_Tx_TICAN 1;
BA_ "GenSigSendType" SG_ 2565130440 LevCtrReq_RGE11_Tx_TICAN 1;
BA_ "GenSigSendType" SG_ 2565130440 RampLevStReq_RGE11_Tx_TICAN 1;
BA_ "GenSigSendType" SG_ 2565130440 StopLevChReq_RGE11_Tx_TICAN 1;
BA_ "GenSigSendType" SG_ 2565130440 DrvAxLoad_RGE11_Tx_TICAN 1;
BA_ "GenSigSendType" SG_ 2565130440 ParkAirPress_RGE11_Tx_TICAN 1;
BA_ "GenSigSendType" SG_ 2565130440 AuxSupPress_RGE11_Tx_TICAN 1;
BA_ "VFrameFormat" BO_ 2565130432 1;
BA_ "GenSigSendType" SG_ 2565130432 RideHeiReq_RGE11_Tx_TICAN 1;
BA_ "GenSigSendType" SG_ 2565130432 LevChgReq_FA_RGE11_Tx_TICAN 1;
BA_ "GenSigSendType" SG_ 2565130432 LevChgReq_RA_RGE11_Tx_TICAN 1;
BA_ "GenSigSendType" SG_ 2565130432 TracHelpReq_RGE11_Tx_TICAN 1;
BA_ "GenSigSendType" SG_ 2565130432 LiftAxPos1Req_RGE11_Tx_TICAN 1;
BA_ "GenSigSendType" SG_ 2565130432 LiftAxPos2Req_RGE11_Tx_TICAN 1;
BA_ "GenSigSendType" SG_ 2565130432 StrAxLockReq_RGE11_Tx_TICAN 1;
BA_ "GenSigSendType" SG_ 2565130432 RampLevReq_RGE11_Tx_TICAN 1;
BA_ "GenSigSendType" SG_ 2565130432 LevCtrReq_RGE11_Tx_TICAN 1;
BA_ "GenSigSendType" SG_ 2565130432 RampLevStReq_RGE11_Tx_TICAN 1;
BA_ "GenSigSendType" SG_ 2565130432 StopLevChReq_RGE11_Tx_TICAN 1;
BA_ "GenSigSendType" SG_ 2565130432 DrvAxLoad_RGE11_Tx_TICAN 1;
BA_ "GenSigSendType" SG_ 2565130432 ParkAirPress_RGE11_Tx_TICAN 1;
BA_ "GenSigSendType" SG_ 2565130432 AuxSupPress_RGE11_Tx_TICAN 1;
BA_ "VFrameFormat" BO_ 2565130424 1;
BA_ "GenSigSendType" SG_ 2565130424 RideHeiReq_RGE11_Tx_TICAN 1;
BA_ "GenSigSendType" SG_ 2565130424 LevChgReq_FA_RGE11_Tx_TICAN 1;
BA_ "GenSigSendType" SG_ 2565130424 LevChgReq_RA_RGE11_Tx_TICAN 1;
BA_ "GenSigSendType" SG_ 2565130424 TracHelpReq_RGE11_Tx_TICAN 1;
BA_ "GenSigSendType" SG_ 2565130424 LiftAxPos1Req_RGE11_Tx_TICAN 1;
BA_ "GenSigSendType" SG_ 2565130424 LiftAxPos2Req_RGE11_Tx_TICAN 1;
BA_ "GenSigSendType" SG_ 2565130424 StrAxLockReq_RGE11_Tx_TICAN 1;
BA_ "GenSigSendType" SG_ 2565130424 RampLevReq_RGE11_Tx_TICAN 1;
BA_ "GenSigSendType" SG_ 2565130424 LevCtrReq_RGE11_Tx_TICAN 1;
BA_ "GenSigSendType" SG_ 2565130424 RampLevStReq_RGE11_Tx_TICAN 1;
BA_ "GenSigSendType" SG_ 2565130424 StopLevChReq_RGE11_Tx_TICAN 1;
BA_ "GenSigSendType" SG_ 2565130424 DrvAxLoad_RGE11_Tx_TICAN 1;
BA_ "GenSigSendType" SG_ 2565130424 ParkAirPress_RGE11_Tx_TICAN 1;
BA_ "GenSigSendType" SG_ 2565130424 AuxSupPress_RGE11_Tx_TICAN 1;
BA_ "VFrameFormat" BO_ 2565130416 1;
BA_ "GenSigSendType" SG_ 2565130416 RideHeiReq_RGE11_Tx_TICAN 1;
BA_ "GenSigSendType" SG_ 2565130416 LevChgReq_FA_RGE11_Tx_TICAN 1;
BA_ "GenSigSendType" SG_ 2565130416 LevChgReq_RA_RGE11_Tx_TICAN 1;
BA_ "GenSigSendType" SG_ 2565130416 TracHelpReq_RGE11_Tx_TICAN 1;
BA_ "GenSigSendType" SG_ 2565130416 LiftAxPos1Req_RGE11_Tx_TICAN 1;
BA_ "GenSigSendType" SG_ 2565130416 LiftAxPos2Req_RGE11_Tx_TICAN 1;
BA_ "GenSigSendType" SG_ 2565130416 StrAxLockReq_RGE11_Tx_TICAN 1;
BA_ "GenSigSendType" SG_ 2565130416 RampLevReq_RGE11_Tx_TICAN 1;
BA_ "GenSigSendType" SG_ 2565130416 LevCtrReq_RGE11_Tx_TICAN 1;
BA_ "GenSigSendType" SG_ 2565130416 RampLevStReq_RGE11_Tx_TICAN 1;
BA_ "GenSigSendType" SG_ 2565130416 StopLevChReq_RGE11_Tx_TICAN 1;
BA_ "GenSigSendType" SG_ 2565130416 DrvAxLoad_RGE11_Tx_TICAN 1;
BA_ "GenSigSendType" SG_ 2565130416 ParkAirPress_RGE11_Tx_TICAN 1;
BA_ "GenSigSendType" SG_ 2565130416 AuxSupPress_RGE11_Tx_TICAN 1;
BA_ "VFrameFormat" BO_ 2565130408 1;
BA_ "GenSigSendType" SG_ 2565130408 RideHeiReq_RGE11_Tx_TICAN 1;
BA_ "GenSigSendType" SG_ 2565130408 LevChgReq_FA_RGE11_Tx_TICAN 1;
BA_ "GenSigSendType" SG_ 2565130408 LevChgReq_RA_RGE11_Tx_TICAN 1;
BA_ "GenSigSendType" SG_ 2565130408 TracHelpReq_RGE11_Tx_TICAN 1;
BA_ "GenSigSendType" SG_ 2565130408 LiftAxPos1Req_RGE11_Tx_TICAN 1;
BA_ "GenSigSendType" SG_ 2565130408 LiftAxPos2Req_RGE11_Tx_TICAN 1;
BA_ "GenSigSendType" SG_ 2565130408 StrAxLockReq_RGE11_Tx_TICAN 1;
BA_ "GenSigSendType" SG_ 2565130408 RampLevReq_RGE11_Tx_TICAN 1;
BA_ "GenSigSendType" SG_ 2565130408 LevCtrReq_RGE11_Tx_TICAN 1;
BA_ "GenSigSendType" SG_ 2565130408 RampLevStReq_RGE11_Tx_TICAN 1;
BA_ "GenSigSendType" SG_ 2565130408 StopLevChReq_RGE11_Tx_TICAN 1;
BA_ "GenSigSendType" SG_ 2565130408 DrvAxLoad_RGE11_Tx_TICAN 1;
BA_ "GenSigSendType" SG_ 2565130408 ParkAirPress_RGE11_Tx_TICAN 1;
BA_ "GenSigSendType" SG_ 2565130408 AuxSupPress_RGE11_Tx_TICAN 1;
BA_ "VFrameFormat" BO_ 2559232200 1;
BA_ "GenSigSendType" SG_ 2559232200 AxLCalDataStrReq_RGE12_TICAN_Tx 1;
BA_ "GenSigSendType" SG_ 2559232200 WhlId_RGE12_TICAN_Tx 1;
BA_ "GenSigSendType" SG_ 2559232200 AxLoadExtScale_RGE12_TICAN_Tx 1;
BA_ "GenSigSendType" SG_ 2559232200 VINindex_RGE12_TICAN_Tx 1;
BA_ "GenSigSendType" SG_ 2559232200 VINdata_RGE12_TICAN_Tx 1;
BA_ "VFrameFormat" BO_ 2559232192 1;
BA_ "GenSigSendType" SG_ 2559232192 AxLCalDataStrReq_RGE12_TICAN_Tx 1;
BA_ "GenSigSendType" SG_ 2559232192 WhlId_RGE12_TICAN_Tx 1;
BA_ "GenSigSendType" SG_ 2559232192 AxLoadExtScale_RGE12_TICAN_Tx 1;
BA_ "GenSigSendType" SG_ 2559232192 VINindex_RGE12_TICAN_Tx 1;
BA_ "GenSigSendType" SG_ 2559232192 VINdata_RGE12_TICAN_Tx 1;
BA_ "VFrameFormat" BO_ 2559232184 1;
BA_ "GenSigSendType" SG_ 2559232184 AxLCalDataStrReq_RGE12_TICAN_Tx 1;
BA_ "GenSigSendType" SG_ 2559232184 WhlId_RGE12_TICAN_Tx 1;
BA_ "GenSigSendType" SG_ 2559232184 AxLoadExtScale_RGE12_TICAN_Tx 1;
BA_ "GenSigSendType" SG_ 2559232184 VINindex_RGE12_TICAN_Tx 1;
BA_ "GenSigSendType" SG_ 2559232184 VINdata_RGE12_TICAN_Tx 1;
BA_ "VFrameFormat" BO_ 2559232176 1;
BA_ "GenSigSendType" SG_ 2559232176 AxLCalDataStrReq_RGE12_TICAN_Tx 1;
BA_ "GenSigSendType" SG_ 2559232176 WhlId_RGE12_TICAN_Tx 1;
BA_ "GenSigSendType" SG_ 2559232176 AxLoadExtScale_RGE12_TICAN_Tx 1;
BA_ "GenSigSendType" SG_ 2559232176 VINindex_RGE12_TICAN_Tx 1;
BA_ "GenSigSendType" SG_ 2559232176 VINdata_RGE12_TICAN_Tx 1;
BA_ "VFrameFormat" BO_ 2559232168 1;
BA_ "GenSigSendType" SG_ 2559232168 AxLCalDataStrReq_RGE12_TICAN_Tx 1;
BA_ "GenSigSendType" SG_ 2559232168 WhlId_RGE12_TICAN_Tx 1;
BA_ "GenSigSendType" SG_ 2559232168 AxLoadExtScale_RGE12_TICAN_Tx 1;
BA_ "GenSigSendType" SG_ 2559232168 VINindex_RGE12_TICAN_Tx 1;
BA_ "GenSigSendType" SG_ 2559232168 VINdata_RGE12_TICAN_Tx 1;
BA_ "VFrameFormat" BO_ 2565152968 1;
BA_ "GenSigSendType" SG_ 2565152968 RideHeiLevel 1;
BA_ "GenSigSendType" SG_ 2565152968 LevelCtrl 1;
BA_ "GenSigSendType" SG_ 2565152968 TracHelp_RGE21_Tx_TICAN 1;
BA_ "GenSigSendType" SG_ 2565152968 RampLevPos 1;
BA_ "GenSigSendType" SG_ 2565152968 LiftAxPos1 1;
BA_ "GenSigSendType" SG_ 2565152968 LiftAxPos2 1;
BA_ "GenSigSendType" SG_ 2565152968 StrAxLock 1;
BA_ "GenSigSendType" SG_ 2565152968 RampLevSt 1;
BA_ "GenSigSendType" SG_ 2565152968 LevChg_FA 1;
BA_ "GenSigSendType" SG_ 2565152968 LevChg_RA 1;
BA_ "GenSigSendType" SG_ 2565152968 StopAck 1;
BA_ "GenSigSendType" SG_ 2565152968 NormLevel 1;
BA_ "GenSigSendType" SG_ 2565152968 RampLevel 1;
BA_ "GenSigSendType" SG_ 2565152968 BodyLevel_FA 1;
BA_ "GenSigSendType" SG_ 2565152968 BodyLevel_RA 1;
BA_ "VFrameFormat" BO_ 2565152960 1;
BA_ "GenSigSendType" SG_ 2565152960 RideHeiLevel 1;
BA_ "GenSigSendType" SG_ 2565152960 LevelCtrl 1;
BA_ "GenSigSendType" SG_ 2565152960 TracHelp_RGE21_Tx_TICAN_2 1;
BA_ "GenSigSendType" SG_ 2565152960 RampLevPos 1;
BA_ "GenSigSendType" SG_ 2565152960 LiftAxPos1 1;
BA_ "GenSigSendType" SG_ 2565152960 LiftAxPos2 1;
BA_ "GenSigSendType" SG_ 2565152960 StrAxLock 1;
BA_ "GenSigSendType" SG_ 2565152960 RampLevSt 1;
BA_ "GenSigSendType" SG_ 2565152960 LevChg_FA 1;
BA_ "GenSigSendType" SG_ 2565152960 LevChg_RA 1;
BA_ "GenSigSendType" SG_ 2565152960 StopAck 1;
BA_ "GenSigSendType" SG_ 2565152960 NormLevel 1;
BA_ "GenSigSendType" SG_ 2565152960 RampLevel 1;
BA_ "GenSigSendType" SG_ 2565152960 BodyLevel_FA 1;
BA_ "GenSigSendType" SG_ 2565152960 BodyLevel_RA 1;
BA_ "VFrameFormat" BO_ 2565152952 1;
BA_ "GenSigSendType" SG_ 2565152952 RideHeiLevel 1;
BA_ "GenSigSendType" SG_ 2565152952 LevelCtrl 1;
BA_ "GenSigSendType" SG_ 2565152952 TracHelp_RGE21_Tx_TICAN_3 1;
BA_ "GenSigSendType" SG_ 2565152952 RampLevPos 1;
BA_ "GenSigSendType" SG_ 2565152952 LiftAxPos1 1;
BA_ "GenSigSendType" SG_ 2565152952 LiftAxPos2 1;
BA_ "GenSigSendType" SG_ 2565152952 StrAxLock 1;
BA_ "GenSigSendType" SG_ 2565152952 RampLevSt 1;
BA_ "GenSigSendType" SG_ 2565152952 LevChg_FA 1;
BA_ "GenSigSendType" SG_ 2565152952 LevChg_RA 1;
BA_ "GenSigSendType" SG_ 2565152952 StopAck 1;
BA_ "GenSigSendType" SG_ 2565152952 NormLevel 1;
BA_ "GenSigSendType" SG_ 2565152952 RampLevel 1;
BA_ "GenSigSendType" SG_ 2565152952 BodyLevel_FA 1;
BA_ "GenSigSendType" SG_ 2565152952 BodyLevel_RA 1;
BA_ "VFrameFormat" BO_ 2565152944 1;
BA_ "GenSigSendType" SG_ 2565152944 RideHeiLevel 1;
BA_ "GenSigSendType" SG_ 2565152944 LevelCtrl 1;
BA_ "GenSigSendType" SG_ 2565152944 TracHelp_RGE21_Tx_TICAN_4 1;
BA_ "GenSigSendType" SG_ 2565152944 RampLevPos 1;
BA_ "GenSigSendType" SG_ 2565152944 LiftAxPos1 1;
BA_ "GenSigSendType" SG_ 2565152944 LiftAxPos2 1;
BA_ "GenSigSendType" SG_ 2565152944 StrAxLock 1;
BA_ "GenSigSendType" SG_ 2565152944 RampLevSt 1;
BA_ "GenSigSendType" SG_ 2565152944 LevChg_FA 1;
BA_ "GenSigSendType" SG_ 2565152944 LevChg_RA 1;
BA_ "GenSigSendType" SG_ 2565152944 StopAck 1;
BA_ "GenSigSendType" SG_ 2565152944 NormLevel 1;
BA_ "GenSigSendType" SG_ 2565152944 RampLevel 1;
BA_ "GenSigSendType" SG_ 2565152944 BodyLevel_FA 1;
BA_ "GenSigSendType" SG_ 2565152944 BodyLevel_RA 1;
BA_ "VFrameFormat" BO_ 2565152936 1;
BA_ "GenSigSendType" SG_ 2565152936 RideHeiLevel 1;
BA_ "GenSigSendType" SG_ 2565152936 LevelCtrl 1;
BA_ "GenSigSendType" SG_ 2565152936 TracHelp_RGE21_Tx_TICAN_5 1;
BA_ "GenSigSendType" SG_ 2565152936 RampLevPos 1;
BA_ "GenSigSendType" SG_ 2565152936 LiftAxPos1 1;
BA_ "GenSigSendType" SG_ 2565152936 LiftAxPos2 1;
BA_ "GenSigSendType" SG_ 2565152936 StrAxLock 1;
BA_ "GenSigSendType" SG_ 2565152936 RampLevSt 1;
BA_ "GenSigSendType" SG_ 2565152936 LevChg_FA 1;
BA_ "GenSigSendType" SG_ 2565152936 LevChg_RA 1;
BA_ "GenSigSendType" SG_ 2565152936 StopAck 1;
BA_ "GenSigSendType" SG_ 2565152936 NormLevel 1;
BA_ "GenSigSendType" SG_ 2565152936 RampLevel 1;
BA_ "GenSigSendType" SG_ 2565152936 BodyLevel_FA 1;
BA_ "GenSigSendType" SG_ 2565152936 BodyLevel_RA 1;
BA_ "VFrameFormat" BO_ 2566806728 1;
BA_ "GenSigInactiveValue" SG_ 2566806728 ReBodyLevFA 32000;
BA_ "GenSigStartValue" SG_ 2566806728 ReBodyLevFA 32000;
BA_ "GenSigSendType" SG_ 2566806728 ReBodyLevFA 1;
BA_ "GenSigInactiveValue" SG_ 2566806728 ReBodyLevRA 32000;
BA_ "GenSigStartValue" SG_ 2566806728 ReBodyLevRA 32000;
BA_ "GenSigSendType" SG_ 2566806728 ReBodyLevRA 1;
BA_ "GenSigSendType" SG_ 2566806728 WheelAxleId 1;
BA_ "GenSigSendType" SG_ 2566806728 AxleLoad 1;
BA_ "VFrameFormat" BO_ 2566806720 1;
BA_ "GenSigInactiveValue" SG_ 2566806720 ReBodyLevFA 32000;
BA_ "GenSigStartValue" SG_ 2566806720 ReBodyLevFA 32000;
BA_ "GenSigSendType" SG_ 2566806720 ReBodyLevFA 1;
BA_ "GenSigInactiveValue" SG_ 2566806720 ReBodyLevRA 32000;
BA_ "GenSigStartValue" SG_ 2566806720 ReBodyLevRA 32000;
BA_ "GenSigSendType" SG_ 2566806720 ReBodyLevRA 1;
BA_ "GenSigSendType" SG_ 2566806720 WheelAxleId 1;
BA_ "GenSigSendType" SG_ 2566806720 AxleLoad 1;
BA_ "VFrameFormat" BO_ 2566806712 1;
BA_ "GenSigInactiveValue" SG_ 2566806712 ReBodyLevFA 32000;
BA_ "GenSigStartValue" SG_ 2566806712 ReBodyLevFA 32000;
BA_ "GenSigSendType" SG_ 2566806712 ReBodyLevFA 1;
BA_ "GenSigInactiveValue" SG_ 2566806712 ReBodyLevRA 32000;
BA_ "GenSigStartValue" SG_ 2566806712 ReBodyLevRA 32000;
BA_ "GenSigSendType" SG_ 2566806712 ReBodyLevRA 1;
BA_ "GenSigSendType" SG_ 2566806712 WheelAxleId 1;
BA_ "GenSigSendType" SG_ 2566806712 AxleLoad 1;
BA_ "VFrameFormat" BO_ 2566806704 1;
BA_ "GenSigInactiveValue" SG_ 2566806704 ReBodyLevFA 32000;
BA_ "GenSigStartValue" SG_ 2566806704 ReBodyLevFA 32000;
BA_ "GenSigSendType" SG_ 2566806704 ReBodyLevFA 1;
BA_ "GenSigInactiveValue" SG_ 2566806704 ReBodyLevRA 32000;
BA_ "GenSigStartValue" SG_ 2566806704 ReBodyLevRA 32000;
BA_ "GenSigSendType" SG_ 2566806704 ReBodyLevRA 1;
BA_ "GenSigSendType" SG_ 2566806704 WheelAxleId 1;
BA_ "GenSigSendType" SG_ 2566806704 AxleLoad 1;
BA_ "VFrameFormat" BO_ 2566806696 1;
BA_ "GenSigInactiveValue" SG_ 2566806696 ReBodyLevFA 32000;
BA_ "GenSigStartValue" SG_ 2566806696 ReBodyLevFA 32000;
BA_ "GenSigSendType" SG_ 2566806696 ReBodyLevFA 1;
BA_ "GenSigInactiveValue" SG_ 2566806696 ReBodyLevRA 32000;
BA_ "GenSigStartValue" SG_ 2566806696 ReBodyLevRA 32000;
BA_ "GenSigSendType" SG_ 2566806696 ReBodyLevRA 1;
BA_ "GenSigSendType" SG_ 2566806696 WheelAxleId 1;
BA_ "GenSigSendType" SG_ 2566806696 AxleLoad 1;
BA_ "VFrameFormat" BO_ 2566807240 1;
BA_ "GenSigSendType" SG_ 2566807240 TyreId 1;
BA_ "GenSigInactiveValue" SG_ 2566807240 TyreTemp 8736;
BA_ "GenSigStartValue" SG_ 2566807240 TyreTemp 8736;
BA_ "GenSigSendType" SG_ 2566807240 TyreTemp 1;
BA_ "GenSigSendType" SG_ 2566807240 AirLeakDet 1;
BA_ "GenSigSendType" SG_ 2566807240 TyrePrTrhDet 1;
BA_ "GenSigSendType" SG_ 2566807240 TyrePowSup 1;
BA_ "GenSigSendType" SG_ 2566807240 VINindex_RGE23_Tx_TICAN 1;
BA_ "GenSigSendType" SG_ 2566807240 VINdata_RGE23_Tx_TICAN 1;
BA_ "VFrameFormat" BO_ 2566807232 1;
BA_ "GenSigSendType" SG_ 2566807232 TyreId 1;
BA_ "GenSigInactiveValue" SG_ 2566807232 TyreTemp 8736;
BA_ "GenSigStartValue" SG_ 2566807232 TyreTemp 8736;
BA_ "GenSigSendType" SG_ 2566807232 TyreTemp 1;
BA_ "GenSigSendType" SG_ 2566807232 AirLeakDet 1;
BA_ "GenSigSendType" SG_ 2566807232 TyrePrTrhDet 1;
BA_ "GenSigSendType" SG_ 2566807232 TyrePowSup 1;
BA_ "GenSigSendType" SG_ 2566807232 VINindex_RGE23_Tx_TICAN_2 1;
BA_ "GenSigSendType" SG_ 2566807232 VINdata_RGE23_Tx_TICAN_2 1;
BA_ "VFrameFormat" BO_ 2566807224 1;
BA_ "GenSigSendType" SG_ 2566807224 TyreId 1;
BA_ "GenSigInactiveValue" SG_ 2566807224 TyreTemp 8736;
BA_ "GenSigStartValue" SG_ 2566807224 TyreTemp 8736;
BA_ "GenSigSendType" SG_ 2566807224 TyreTemp 1;
BA_ "GenSigSendType" SG_ 2566807224 AirLeakDet 1;
BA_ "GenSigSendType" SG_ 2566807224 TyrePrTrhDet 1;
BA_ "GenSigSendType" SG_ 2566807224 TyrePowSup 1;
BA_ "GenSigSendType" SG_ 2566807224 VINindex_RGE23_Tx_TICAN_3 1;
BA_ "GenSigSendType" SG_ 2566807224 VINdata_RGE23_Tx_TICAN_3 1;
BA_ "VFrameFormat" BO_ 2566807216 1;
BA_ "GenSigSendType" SG_ 2566807216 TyreId 1;
BA_ "GenSigInactiveValue" SG_ 2566807216 TyreTemp 8736;
BA_ "GenSigStartValue" SG_ 2566807216 TyreTemp 8736;
BA_ "GenSigSendType" SG_ 2566807216 TyreTemp 1;
BA_ "GenSigSendType" SG_ 2566807216 AirLeakDet 1;
BA_ "GenSigSendType" SG_ 2566807216 TyrePrTrhDet 1;
BA_ "GenSigSendType" SG_ 2566807216 TyrePowSup 1;
BA_ "GenSigSendType" SG_ 2566807216 VINindex_RGE23_Tx_TICAN_4 1;
BA_ "GenSigSendType" SG_ 2566807216 VINdata_RGE23_Tx_TICAN_4 1;
BA_ "VFrameFormat" BO_ 2566807208 1;
BA_ "GenSigSendType" SG_ 2566807208 TyreId 1;
BA_ "GenSigInactiveValue" SG_ 2566807208 TyreTemp 8736;
BA_ "GenSigStartValue" SG_ 2566807208 TyreTemp 8736;
BA_ "GenSigSendType" SG_ 2566807208 TyreTemp 1;
BA_ "GenSigSendType" SG_ 2566807208 AirLeakDet 1;
BA_ "GenSigSendType" SG_ 2566807208 TyrePrTrhDet 1;
BA_ "GenSigSendType" SG_ 2566807208 TyrePowSup 1;
BA_ "GenSigSendType" SG_ 2566807208 VINindex_RGE23_Tx_TICAN_5 1;
BA_ "GenSigSendType" SG_ 2566807208 VINdata_RGE23_Tx_TICAN_5 1;
BA_ "VFrameFormat" BO_ 2559123656 1;
BA_ "GenSigSendType" SG_ 2559123656 TyreId 1;
BA_ "GenSigSendType" SG_ 2559123656 AxLoadTowedVehicle 1;
BA_ "GenSigSendType" SG_ 2559123656 AxLoadExtScale_RGE24 1;
BA_ "GenSigSendType" SG_ 2559123656 AxLCalDataLoadLvl 1;
BA_ "GenSigSendType" SG_ 2559123656 AxLCalTyp 1;
BA_ "GenSigSendType" SG_ 2559123656 AxLCalDataStr 1;
BA_ "GenSigInactiveValue" SG_ 2559123656 Year_RGE24 15;
BA_ "GenSigStartValue" SG_ 2559123656 Year_RGE24 15;
BA_ "GenSigSendType" SG_ 2559123656 Year_RGE24 1;
BA_ "GenSigSendType" SG_ 2559123656 Month_RGE24 1;
BA_ "VFrameFormat" BO_ 2559123648 1;
BA_ "GenSigSendType" SG_ 2559123648 TyreId 1;
BA_ "GenSigSendType" SG_ 2559123648 AxLoadTowedVehicle 1;
BA_ "GenSigSendType" SG_ 2559123648 AxLoadExtScale_RGE24 1;
BA_ "GenSigSendType" SG_ 2559123648 AxLCalDataLoadLvl 1;
BA_ "GenSigSendType" SG_ 2559123648 AxLCalTyp 1;
BA_ "GenSigSendType" SG_ 2559123648 AxLCalDataStr 1;
BA_ "GenSigInactiveValue" SG_ 2559123648 Year_RGE24 15;
BA_ "GenSigStartValue" SG_ 2559123648 Year_RGE24 15;
BA_ "GenSigSendType" SG_ 2559123648 Year_RGE24 1;
BA_ "GenSigSendType" SG_ 2559123648 Month_RGE24 1;
BA_ "VFrameFormat" BO_ 2559123640 1;
BA_ "GenSigSendType" SG_ 2559123640 TyreId 1;
BA_ "GenSigSendType" SG_ 2559123640 AxLoadTowedVehicle 1;
BA_ "GenSigSendType" SG_ 2559123640 AxLoadExtScale_RGE24 1;
BA_ "GenSigSendType" SG_ 2559123640 AxLCalDataLoadLvl 1;
BA_ "GenSigSendType" SG_ 2559123640 AxLCalTyp 1;
BA_ "GenSigSendType" SG_ 2559123640 AxLCalDataStr 1;
BA_ "GenSigInactiveValue" SG_ 2559123640 Year_RGE24 15;
BA_ "GenSigStartValue" SG_ 2559123640 Year_RGE24 15;
BA_ "GenSigSendType" SG_ 2559123640 Year_RGE24 1;
BA_ "GenSigSendType" SG_ 2559123640 Month_RGE24 1;
BA_ "VFrameFormat" BO_ 2559123632 1;
BA_ "GenSigSendType" SG_ 2559123632 TyreId 1;
BA_ "GenSigSendType" SG_ 2559123632 AxLoadTowedVehicle 1;
BA_ "GenSigSendType" SG_ 2559123632 AxLoadExtScale_RGE24 1;
BA_ "GenSigSendType" SG_ 2559123632 AxLCalDataLoadLvl 1;
BA_ "GenSigSendType" SG_ 2559123632 AxLCalTyp 1;
BA_ "GenSigSendType" SG_ 2559123632 AxLCalDataStr 1;
BA_ "GenSigInactiveValue" SG_ 2559123632 Year_RGE24 15;
BA_ "GenSigStartValue" SG_ 2559123632 Year_RGE24 15;
BA_ "GenSigSendType" SG_ 2559123632 Year_RGE24 1;
BA_ "GenSigSendType" SG_ 2559123632 Month_RGE24 1;
BA_ "VFrameFormat" BO_ 2559123624 1;
BA_ "GenSigSendType" SG_ 2559123624 TyreId 1;
BA_ "GenSigSendType" SG_ 2559123624 AxLoadTowedVehicle 1;
BA_ "GenSigSendType" SG_ 2559123624 AxLoadExtScale_RGE24 1;
BA_ "GenSigSendType" SG_ 2559123624 AxLCalDataLoadLvl 1;
BA_ "GenSigSendType" SG_ 2559123624 AxLCalTyp 1;
BA_ "GenSigSendType" SG_ 2559123624 AxLCalDataStr 1;
BA_ "GenSigInactiveValue" SG_ 2559123624 Year_RGE24 15;
BA_ "GenSigStartValue" SG_ 2559123624 Year_RGE24 15;
BA_ "GenSigSendType" SG_ 2559123624 Year_RGE24 1;
BA_ "GenSigSendType" SG_ 2559123624 Month_RGE24 1;
BA_ "VFrameFormat" BO_ 2565523456 1;
BA_ "GenSigSendType" SG_ 2565523456 ReqPGNLow 1;
BA_ "GenSigSendType" SG_ 2565523456 ReqPGNMiddle 1;
BA_ "GenSigSendType" SG_ 2565523456 ReqPGNHigh 1;
BA_ "VFrameFormat" BO_ 2565521600 1;
BA_ "GenSigSendType" SG_ 2565521600 ReqPGNLow 1;
BA_ "GenSigSendType" SG_ 2565521600 ReqPGNMiddle 1;
BA_ "GenSigSendType" SG_ 2565521600 ReqPGNHigh 1;
BA_ "VFrameFormat" BO_ 2565519544 1;
BA_ "GenSigSendType" SG_ 2565519544 ReqPGNLow 1;
BA_ "GenSigSendType" SG_ 2565519544 ReqPGNMiddle 1;
BA_ "GenSigSendType" SG_ 2565519544 ReqPGNHigh 1;
BA_ "VFrameFormat" BO_ 2565517488 1;
BA_ "GenSigSendType" SG_ 2565517488 ReqPGNLow 1;
BA_ "GenSigSendType" SG_ 2565517488 ReqPGNMiddle 1;
BA_ "GenSigSendType" SG_ 2565517488 ReqPGNHigh 1;
BA_ "VFrameFormat" BO_ 2565515432 1;
BA_ "GenSigSendType" SG_ 2565515432 ReqPGNLow 1;
BA_ "GenSigSendType" SG_ 2565515432 ReqPGNMiddle 1;
BA_ "GenSigSendType" SG_ 2565515432 ReqPGNHigh 1;
BA_ "VFrameFormat" BO_ 2565513376 1;
BA_ "GenSigSendType" SG_ 2565513376 ReqPGNLow 1;
BA_ "GenSigSendType" SG_ 2565513376 ReqPGNMiddle 1;
BA_ "GenSigSendType" SG_ 2565513376 ReqPGNHigh 1;
BA_ "VFrameFormat" BO_ 2565511320 1;
BA_ "GenSigSendType" SG_ 2565511320 ReqPGNLow 1;
BA_ "GenSigSendType" SG_ 2565511320 ReqPGNMiddle 1;
BA_ "GenSigSendType" SG_ 2565511320 ReqPGNHigh 1;
BA_ "VFrameFormat" BO_ 2565509264 1;
BA_ "GenSigSendType" SG_ 2565509264 ReqPGNLow 1;
BA_ "GenSigSendType" SG_ 2565509264 ReqPGNMiddle 1;
BA_ "GenSigSendType" SG_ 2565509264 ReqPGNHigh 1;
BA_ "VFrameFormat" BO_ 2565507208 1;
BA_ "GenSigSendType" SG_ 2565507208 ReqPGNLow 1;
BA_ "GenSigSendType" SG_ 2565507208 ReqPGNMiddle 1;
BA_ "GenSigSendType" SG_ 2565507208 ReqPGNHigh 1;
BA_ "VFrameFormat" BO_ 2565505152 1;
BA_ "GenSigSendType" SG_ 2565505152 ReqPGNLow 1;
BA_ "GenSigSendType" SG_ 2565505152 ReqPGNMiddle 1;
BA_ "GenSigSendType" SG_ 2565505152 ReqPGNHigh 1;
BA_ "VFrameFormat" BO_ 2565537536 1;
BA_ "GenSigSendType" SG_ 2565537536 ReqPGNLow 1;
BA_ "GenSigSendType" SG_ 2565537536 ReqPGNMiddle 1;
BA_ "GenSigSendType" SG_ 2565537536 ReqPGNHigh 1;
BA_ "VFrameFormat" BO_ 2566841891 1;
BA_ "GenSigSendType" SG_ 2566841891 Seconds 1;
BA_ "GenSigSendType" SG_ 2566841891 Minutes 1;
BA_ "GenSigSendType" SG_ 2566841891 Hours 1;
BA_ "GenSigSendType" SG_ 2566841891 Month 1;
BA_ "GenSigSendType" SG_ 2566841891 Day 1;
BA_ "GenSigInactiveValue" SG_ 2566841891 Year 15;
BA_ "GenSigStartValue" SG_ 2566841891 Year 15;
BA_ "GenSigSendType" SG_ 2566841891 Year 1;
BA_ "GenSigInactiveValue" SG_ 2566841891 LocalMinuteOffset 125;
BA_ "GenSigStartValue" SG_ 2566841891 LocalMinuteOffset 125;
BA_ "GenSigSendType" SG_ 2566841891 LocalMinuteOffset 1;
BA_ "GenSigInactiveValue" SG_ 2566841891 LocalHourOffset 125;
BA_ "GenSigStartValue" SG_ 2566841891 LocalHourOffset 125;
BA_ "GenSigSendType" SG_ 2566841891 LocalHourOffset 1;
BA_ "VFrameFormat" BO_ 2566857984 1;
BA_ "GenSigSendType" SG_ 2566857984 WLReq 1;
BA_ "GenSigSendType" SG_ 2566857984 BrIntvEna 1;
BA_ "GenSigSendType" SG_ 2566857984 BrDemJ1939 1;
BA_ "VFrameFormat" BO_ 2565406664 1;
BA_ "GenSigSendType" SG_ 2565406664 ControlByte 1;
BA_ "GenSigSendType" SG_ 2565406664 GroupFuncVal 1;
BA_ "GenSigSendType" SG_ 2565406664 ECUAddress 1;
BA_ "GenSigSendType" SG_ 2565406664 RequestedPGN 1;
BA_ "VFrameFormat" BO_ 2565406656 1;
BA_ "GenSigSendType" SG_ 2565406656 ControlByte 1;
BA_ "GenSigSendType" SG_ 2565406656 GroupFuncVal 1;
BA_ "GenSigSendType" SG_ 2565406656 ECUAddress 1;
BA_ "GenSigSendType" SG_ 2565406656 RequestedPGN 1;
BA_ "VFrameFormat" BO_ 2565406648 1;
BA_ "GenSigSendType" SG_ 2565406648 ControlByte 1;
BA_ "GenSigSendType" SG_ 2565406648 GroupFuncVal 1;
BA_ "GenSigSendType" SG_ 2565406648 ECUAddress 1;
BA_ "GenSigSendType" SG_ 2565406648 RequestedPGN 1;
BA_ "VFrameFormat" BO_ 2565406640 1;
BA_ "GenSigSendType" SG_ 2565406640 ControlByte 1;
BA_ "GenSigSendType" SG_ 2565406640 GroupFuncVal 1;
BA_ "GenSigSendType" SG_ 2565406640 ECUAddress 1;
BA_ "GenSigSendType" SG_ 2565406640 RequestedPGN 1;
BA_ "VFrameFormat" BO_ 2565406632 1;
BA_ "GenSigSendType" SG_ 2565406632 ControlByte 1;
BA_ "GenSigSendType" SG_ 2565406632 GroupFuncVal 1;
BA_ "GenSigSendType" SG_ 2565406632 ECUAddress 1;
BA_ "GenSigSendType" SG_ 2565406632 RequestedPGN 1;
BA_ "VFrameFormat" BO_ 2565406624 1;
BA_ "GenSigSendType" SG_ 2565406624 ControlByte 1;
BA_ "GenSigSendType" SG_ 2565406624 GroupFuncVal 1;
BA_ "GenSigSendType" SG_ 2565406624 ECUAddress 1;
BA_ "GenSigSendType" SG_ 2565406624 RequestedPGN 1;
BA_ "VFrameFormat" BO_ 2565406616 1;
BA_ "GenSigSendType" SG_ 2565406616 ControlByte 1;
BA_ "GenSigSendType" SG_ 2565406616 GroupFuncVal 1;
BA_ "GenSigSendType" SG_ 2565406616 ECUAddress 1;
BA_ "GenSigSendType" SG_ 2565406616 RequestedPGN 1;
BA_ "VFrameFormat" BO_ 2565406608 1;
BA_ "GenSigSendType" SG_ 2565406608 ControlByte 1;
BA_ "GenSigSendType" SG_ 2565406608 GroupFuncVal 1;
BA_ "GenSigSendType" SG_ 2565406608 ECUAddress 1;
BA_ "GenSigSendType" SG_ 2565406608 RequestedPGN 1;
BA_ "VFrameFormat" BO_ 2565406600 1;
BA_ "GenSigSendType" SG_ 2565406600 ControlByte 1;
BA_ "GenSigSendType" SG_ 2565406600 GroupFuncVal 1;
BA_ "GenSigSendType" SG_ 2565406600 ECUAddress 1;
BA_ "GenSigSendType" SG_ 2565406600 RequestedPGN 1;
BA_ "VFrameFormat" BO_ 2565406592 1;
BA_ "GenSigSendType" SG_ 2565406592 ControlByte 1;
BA_ "GenSigSendType" SG_ 2565406592 GroupFuncVal 1;
BA_ "GenSigSendType" SG_ 2565406592 ECUAddress 1;
BA_ "GenSigSendType" SG_ 2565406592 RequestedPGN 1;
BA_ "VFrameFormat" BO_ 2566832072 1;
BA_ "GenSigSendType" SG_ 2566832072 vVeh_EBC2_Tx 1;
BA_ "VFrameFormat" BO_ 2566832064 1;
BA_ "GenSigSendType" SG_ 2566832064 vVeh_EBC2_Tx_2 1;
BA_ "VFrameFormat" BO_ 2566832056 1;
BA_ "GenSigSendType" SG_ 2566832056 vVeh_EBC2_Tx_3 1;
BA_ "VFrameFormat" BO_ 2566832048 1;
BA_ "GenSigSendType" SG_ 2566832048 vVeh_EBC2_Tx_4 1;
BA_ "VFrameFormat" BO_ 2566832040 1;
BA_ "GenSigSendType" SG_ 2566832040 vVeh_EBC2_Tx_5 1;
BA_ "VFrameFormat" BO_ 2566832032 1;
BA_ "GenSigSendType" SG_ 2566832032 vVeh_EBC2_Tx_6 1;
BA_ "VFrameFormat" BO_ 2566832024 1;
BA_ "GenSigSendType" SG_ 2566832024 vVeh_EBC2_Tx_7 1;
BA_ "VFrameFormat" BO_ 2566832016 1;
BA_ "GenSigSendType" SG_ 2566832016 vVeh_EBC2_Tx_8 1;
BA_ "VFrameFormat" BO_ 2566832008 1;
BA_ "GenSigSendType" SG_ 2566832008 vVeh_EBC2_Tx_9 1;
BA_ "VFrameFormat" BO_ 2566832000 1;
BA_ "GenSigSendType" SG_ 2566832000 vVeh_EBC2_Tx_10 1;
BA_ "VFrameFormat" BO_ 2566832328 1;
BA_ "GenSigSendType" SG_ 2566832328 ComponentId 1;
BA_ "GenSigInactiveValue" SG_ 2566832328 ServiceDist_SERV_Tx 32127;
BA_ "GenSigStartValue" SG_ 2566832328 ServiceDist_SERV_Tx 32127;
BA_ "GenSigSendType" SG_ 2566832328 ServiceDist_SERV_Tx 1;
BA_ "VFrameFormat" BO_ 2566832320 1;
BA_ "GenSigSendType" SG_ 2566832320 ComponentId 1;
BA_ "GenSigInactiveValue" SG_ 2566832320 ServiceDist_SERV_Tx_2 32127;
BA_ "GenSigStartValue" SG_ 2566832320 ServiceDist_SERV_Tx_2 32127;
BA_ "GenSigSendType" SG_ 2566832320 ServiceDist_SERV_Tx_2 1;
BA_ "VFrameFormat" BO_ 2566832312 1;
BA_ "GenSigSendType" SG_ 2566832312 ComponentId 1;
BA_ "GenSigInactiveValue" SG_ 2566832312 ServiceDist_SERV_Tx_3 32127;
BA_ "GenSigStartValue" SG_ 2566832312 ServiceDist_SERV_Tx_3 32127;
BA_ "GenSigSendType" SG_ 2566832312 ServiceDist_SERV_Tx_3 1;
BA_ "VFrameFormat" BO_ 2566832304 1;
BA_ "GenSigSendType" SG_ 2566832304 ComponentId 1;
BA_ "GenSigInactiveValue" SG_ 2566832304 ServiceDist_SERV_Tx_4 32127;
BA_ "GenSigStartValue" SG_ 2566832304 ServiceDist_SERV_Tx_4 32127;
BA_ "GenSigSendType" SG_ 2566832304 ServiceDist_SERV_Tx_4 1;
BA_ "VFrameFormat" BO_ 2566832296 1;
BA_ "GenSigSendType" SG_ 2566832296 ComponentId 1;
BA_ "GenSigInactiveValue" SG_ 2566832296 ServiceDist_SERV_Tx_5 32127;
BA_ "GenSigStartValue" SG_ 2566832296 ServiceDist_SERV_Tx_5 32127;
BA_ "GenSigSendType" SG_ 2566832296 ServiceDist_SERV_Tx_5 1;
BA_ "VFrameFormat" BO_ 2566832288 1;
BA_ "GenSigSendType" SG_ 2566832288 ComponentId 1;
BA_ "GenSigInactiveValue" SG_ 2566832288 ServiceDist_SERV_Tx_6 32127;
BA_ "GenSigStartValue" SG_ 2566832288 ServiceDist_SERV_Tx_6 32127;
BA_ "GenSigSendType" SG_ 2566832288 ServiceDist_SERV_Tx_6 1;
BA_ "VFrameFormat" BO_ 2566832280 1;
BA_ "GenSigSendType" SG_ 2566832280 ComponentId 1;
BA_ "GenSigInactiveValue" SG_ 2566832280 ServiceDist_SERV_Tx_7 32127;
BA_ "GenSigStartValue" SG_ 2566832280 ServiceDist_SERV_Tx_7 32127;
BA_ "GenSigSendType" SG_ 2566832280 ServiceDist_SERV_Tx_7 1;
BA_ "VFrameFormat" BO_ 2566832272 1;
BA_ "GenSigSendType" SG_ 2566832272 ComponentId 1;
BA_ "GenSigInactiveValue" SG_ 2566832272 ServiceDist_SERV_Tx_8 32127;
BA_ "GenSigStartValue" SG_ 2566832272 ServiceDist_SERV_Tx_8 32127;
BA_ "GenSigSendType" SG_ 2566832272 ServiceDist_SERV_Tx_8 1;
BA_ "VFrameFormat" BO_ 2566832264 1;
BA_ "GenSigSendType" SG_ 2566832264 ComponentId 1;
BA_ "GenSigInactiveValue" SG_ 2566832264 ServiceDist_SERV_Tx_9 32127;
BA_ "GenSigStartValue" SG_ 2566832264 ServiceDist_SERV_Tx_9 32127;
BA_ "GenSigSendType" SG_ 2566832264 ServiceDist_SERV_Tx_9 1;
BA_ "VFrameFormat" BO_ 2566832256 1;
BA_ "GenSigSendType" SG_ 2566832256 ComponentId 1;
BA_ "GenSigInactiveValue" SG_ 2566832256 ServiceDist_SERV_Tx_10 32127;
BA_ "GenSigStartValue" SG_ 2566832256 ServiceDist_SERV_Tx_10 32127;
BA_ "GenSigSendType" SG_ 2566832256 ServiceDist_SERV_Tx_10 1;
BA_ "VFrameFormat" BO_ 2566832584 1;
BA_ "GenSigSendType" SG_ 2566832584 ODO 1;
BA_ "GenSigSendType" SG_ 2566832584 Trip 1;
BA_ "VFrameFormat" BO_ 2566832576 1;
BA_ "GenSigSendType" SG_ 2566832576 ODO 1;
BA_ "GenSigSendType" SG_ 2566832576 Trip 1;
BA_ "VFrameFormat" BO_ 2566832568 1;
BA_ "GenSigSendType" SG_ 2566832568 ODO 1;
BA_ "GenSigSendType" SG_ 2566832568 Trip 1;
BA_ "VFrameFormat" BO_ 2566832560 1;
BA_ "GenSigSendType" SG_ 2566832560 ODO 1;
BA_ "GenSigSendType" SG_ 2566832560 Trip 1;
BA_ "VFrameFormat" BO_ 2566832552 1;
BA_ "GenSigSendType" SG_ 2566832552 ODO 1;
BA_ "GenSigSendType" SG_ 2566832552 Trip 1;
BA_ "VFrameFormat" BO_ 2566832544 1;
BA_ "GenSigSendType" SG_ 2566832544 ODO 1;
BA_ "GenSigSendType" SG_ 2566832544 Trip 1;
BA_ "VFrameFormat" BO_ 2566832536 1;
BA_ "GenSigSendType" SG_ 2566832536 ODO 1;
BA_ "GenSigSendType" SG_ 2566832536 Trip 1;
BA_ "VFrameFormat" BO_ 2566832528 1;
BA_ "GenSigSendType" SG_ 2566832528 ODO 1;
BA_ "GenSigSendType" SG_ 2566832528 Trip 1;
BA_ "VFrameFormat" BO_ 2566832520 1;
BA_ "GenSigSendType" SG_ 2566832520 ODO 1;
BA_ "GenSigSendType" SG_ 2566832520 Trip 1;
BA_ "VFrameFormat" BO_ 2566832512 1;
BA_ "GenSigSendType" SG_ 2566832512 ODO 1;
BA_ "GenSigSendType" SG_ 2566832512 Trip 1;
BA_ "VFrameFormat" BO_ 2566843080 1;
BA_ "GenSigSendType" SG_ 2566843080 TrlWeight_VW_Tx 1;
BA_ "VFrameFormat" BO_ 2566843072 1;
BA_ "GenSigSendType" SG_ 2566843072 TrlWeight_VW_Tx_2 1;
BA_ "VFrameFormat" BO_ 2566843064 1;
BA_ "GenSigSendType" SG_ 2566843064 TrlWeight_VW_Tx_3 1;
BA_ "VFrameFormat" BO_ 2566843056 1;
BA_ "GenSigSendType" SG_ 2566843056 TrlWeight_VW_Tx_4 1;
BA_ "VFrameFormat" BO_ 2566843048 1;
BA_ "GenSigSendType" SG_ 2566843048 TrlWeight_VW_Tx_5 1;
BA_ "VFrameFormat" BO_ 2566843040 1;
BA_ "GenSigSendType" SG_ 2566843040 TrlWeight_VW_Tx_6 1;
BA_ "VFrameFormat" BO_ 2566843032 1;
BA_ "GenSigSendType" SG_ 2566843032 TrlWeight_VW_Tx_7 1;
BA_ "VFrameFormat" BO_ 2566843024 1;
BA_ "GenSigSendType" SG_ 2566843024 TrlWeight_VW_Tx_8 1;
BA_ "VFrameFormat" BO_ 2566843016 1;
BA_ "GenSigSendType" SG_ 2566843016 TrlWeight_VW_Tx_9 1;
BA_ "VFrameFormat" BO_ 2566843008 1;
BA_ "GenSigSendType" SG_ 2566843008 TrlWeight_VW_Tx_10 1;
BA_ "VFrameFormat" BO_ 2566847176 1;
BA_ "GenSigSendType" SG_ 2566847176 PBrake 1;
BA_ "GenSigSendType" SG_ 2566847176 PSys_B_Tx 1;
BA_ "VFrameFormat" BO_ 2566847168 1;
BA_ "GenSigSendType" SG_ 2566847168 PBrake 1;
BA_ "GenSigSendType" SG_ 2566847168 PSys_B_Tx_2 1;
BA_ "VFrameFormat" BO_ 2566847160 1;
BA_ "GenSigSendType" SG_ 2566847160 PBrake 1;
BA_ "GenSigSendType" SG_ 2566847160 PSys_B_Tx_3 1;
BA_ "VFrameFormat" BO_ 2566847152 1;
BA_ "GenSigSendType" SG_ 2566847152 PBrake 1;
BA_ "GenSigSendType" SG_ 2566847152 PSys_B_Tx_4 1;
BA_ "VFrameFormat" BO_ 2566847144 1;
BA_ "GenSigSendType" SG_ 2566847144 PBrake 1;
BA_ "GenSigSendType" SG_ 2566847144 PSys_B_Tx_5 1;
BA_ "VFrameFormat" BO_ 2566847136 1;
BA_ "GenSigSendType" SG_ 2566847136 PBrake 1;
BA_ "GenSigSendType" SG_ 2566847136 PSys_B_Tx_6 1;
BA_ "VFrameFormat" BO_ 2566847128 1;
BA_ "GenSigSendType" SG_ 2566847128 PBrake 1;
BA_ "GenSigSendType" SG_ 2566847128 PSys_B_Tx_7 1;
BA_ "VFrameFormat" BO_ 2566847120 1;
BA_ "GenSigSendType" SG_ 2566847120 PBrake 1;
BA_ "GenSigSendType" SG_ 2566847120 PSys_B_Tx_8 1;
BA_ "VFrameFormat" BO_ 2566847112 1;
BA_ "GenSigSendType" SG_ 2566847112 PBrake 1;
BA_ "GenSigSendType" SG_ 2566847112 PSys_B_Tx_9 1;
BA_ "VFrameFormat" BO_ 2566847104 1;
BA_ "GenSigSendType" SG_ 2566847104 PBrake 1;
BA_ "GenSigSendType" SG_ 2566847104 PSys_B_Tx_10 1;
BA_ "VFrameFormat" BO_ 2566805960 1;
BA_ "GenSigInactiveValue" SG_ 2566805960 VehicleLevelFrontLeft 32000;
BA_ "GenSigStartValue" SG_ 2566805960 VehicleLevelFrontLeft 32000;
BA_ "GenSigSendType" SG_ 2566805960 VehicleLevelFrontLeft 1;
BA_ "GenSigInactiveValue" SG_ 2566805960 VehicleLevelFrontRight 32000;
BA_ "GenSigStartValue" SG_ 2566805960 VehicleLevelFrontRight 32000;
BA_ "GenSigSendType" SG_ 2566805960 VehicleLevelFrontRight 1;
BA_ "GenSigInactiveValue" SG_ 2566805960 VehicleLevelRearLeft 32000;
BA_ "GenSigStartValue" SG_ 2566805960 VehicleLevelRearLeft 32000;
BA_ "GenSigSendType" SG_ 2566805960 VehicleLevelRearLeft 1;
BA_ "GenSigInactiveValue" SG_ 2566805960 VehicleLevelRearRight 32000;
BA_ "GenSigStartValue" SG_ 2566805960 VehicleLevelRearRight 32000;
BA_ "GenSigSendType" SG_ 2566805960 VehicleLevelRearRight 1;
BA_ "VFrameFormat" BO_ 2566805952 1;
BA_ "GenSigInactiveValue" SG_ 2566805952 VehicleLevelFrontLeft 32000;
BA_ "GenSigStartValue" SG_ 2566805952 VehicleLevelFrontLeft 32000;
BA_ "GenSigSendType" SG_ 2566805952 VehicleLevelFrontLeft 1;
BA_ "GenSigInactiveValue" SG_ 2566805952 VehicleLevelFrontRight 32000;
BA_ "GenSigStartValue" SG_ 2566805952 VehicleLevelFrontRight 32000;
BA_ "GenSigSendType" SG_ 2566805952 VehicleLevelFrontRight 1;
BA_ "GenSigInactiveValue" SG_ 2566805952 VehicleLevelRearLeft 32000;
BA_ "GenSigStartValue" SG_ 2566805952 VehicleLevelRearLeft 32000;
BA_ "GenSigSendType" SG_ 2566805952 VehicleLevelRearLeft 1;
BA_ "GenSigInactiveValue" SG_ 2566805952 VehicleLevelRearRight 32000;
BA_ "GenSigStartValue" SG_ 2566805952 VehicleLevelRearRight 32000;
BA_ "GenSigSendType" SG_ 2566805952 VehicleLevelRearRight 1;
BA_ "VFrameFormat" BO_ 2566805944 1;
BA_ "GenSigInactiveValue" SG_ 2566805944 VehicleLevelFrontLeft 32000;
BA_ "GenSigStartValue" SG_ 2566805944 VehicleLevelFrontLeft 32000;
BA_ "GenSigSendType" SG_ 2566805944 VehicleLevelFrontLeft 1;
BA_ "GenSigInactiveValue" SG_ 2566805944 VehicleLevelFrontRight 32000;
BA_ "GenSigStartValue" SG_ 2566805944 VehicleLevelFrontRight 32000;
BA_ "GenSigSendType" SG_ 2566805944 VehicleLevelFrontRight 1;
BA_ "GenSigInactiveValue" SG_ 2566805944 VehicleLevelRearLeft 32000;
BA_ "GenSigStartValue" SG_ 2566805944 VehicleLevelRearLeft 32000;
BA_ "GenSigSendType" SG_ 2566805944 VehicleLevelRearLeft 1;
BA_ "GenSigInactiveValue" SG_ 2566805944 VehicleLevelRearRight 32000;
BA_ "GenSigStartValue" SG_ 2566805944 VehicleLevelRearRight 32000;
BA_ "GenSigSendType" SG_ 2566805944 VehicleLevelRearRight 1;
SIG_GROUP_ 2566805960 AUTO_SG_ASC3_Tx 1 : VehicleLevelFrontLeft VehicleLevelFrontRight VehicleLevelRearLeft VehicleLevelRearRight;
SIG_GROUP_ 2566805952 AUTO_SG_ASC3_Tx_2 1 : VehicleLevelFrontLeft VehicleLevelFrontRight VehicleLevelRearLeft VehicleLevelRearRight;
SIG_GROUP_ 2566805944 AUTO_SG_ASC3_Tx_3 1 : VehicleLevelFrontLeft VehicleLevelFrontRight VehicleLevelRearLeft VehicleLevelRearRight;
SIG_GROUP_ 2565406664 AUTO_SG_AckPGN_Tx 1 : ControlByte GroupFuncVal ECUAddress RequestedPGN;
SIG_GROUP_ 2565406592 AUTO_SG_AckPGN_Tx_10 1 : ControlByte GroupFuncVal ECUAddress RequestedPGN;
SIG_GROUP_ 2565406656 AUTO_SG_AckPGN_Tx_2 1 : ControlByte GroupFuncVal ECUAddress RequestedPGN;
SIG_GROUP_ 2565406648 AUTO_SG_AckPGN_Tx_3 1 : ControlByte GroupFuncVal ECUAddress RequestedPGN;
SIG_GROUP_ 2565406640 AUTO_SG_AckPGN_Tx_4 1 : ControlByte GroupFuncVal ECUAddress RequestedPGN;
SIG_GROUP_ 2565406632 AUTO_SG_AckPGN_Tx_5 1 : ControlByte GroupFuncVal ECUAddress RequestedPGN;
SIG_GROUP_ 2565406624 AUTO_SG_AckPGN_Tx_6 1 : ControlByte GroupFuncVal ECUAddress RequestedPGN;
SIG_GROUP_ 2565406616 AUTO_SG_AckPGN_Tx_7 1 : ControlByte GroupFuncVal ECUAddress RequestedPGN;
SIG_GROUP_ 2565406608 AUTO_SG_AckPGN_Tx_8 1 : ControlByte GroupFuncVal ECUAddress RequestedPGN;
SIG_GROUP_ 2565406600 AUTO_SG_AckPGN_Tx_9 1 : ControlByte GroupFuncVal ECUAddress RequestedPGN;
SIG_GROUP_ 2566847176 AUTO_SG_B_Tx 1 : PBrake PSys_B_Tx;
SIG_GROUP_ 2566847104 AUTO_SG_B_Tx_10 1 : PBrake PSys_B_Tx_10;
SIG_GROUP_ 2566847168 AUTO_SG_B_Tx_2 1 : PBrake PSys_B_Tx_2;
SIG_GROUP_ 2566847160 AUTO_SG_B_Tx_3 1 : PBrake PSys_B_Tx_3;
SIG_GROUP_ 2566847152 AUTO_SG_B_Tx_4 1 : PBrake PSys_B_Tx_4;
SIG_GROUP_ 2566847144 AUTO_SG_B_Tx_5 1 : PBrake PSys_B_Tx_5;
SIG_GROUP_ 2566847136 AUTO_SG_B_Tx_6 1 : PBrake PSys_B_Tx_6;
SIG_GROUP_ 2566847128 AUTO_SG_B_Tx_7 1 : PBrake PSys_B_Tx_7;
SIG_GROUP_ 2566847120 AUTO_SG_B_Tx_8 1 : PBrake PSys_B_Tx_8;
SIG_GROUP_ 2566847112 AUTO_SG_B_Tx_9 1 : PBrake PSys_B_Tx_9;
SIG_GROUP_ 2566832072 AUTO_SG_EBC2_Tx 1 : vVeh_EBC2_Tx;
SIG_GROUP_ 2566832000 AUTO_SG_EBC2_Tx_10 1 : vVeh_EBC2_Tx_10;
SIG_GROUP_ 2566832064 AUTO_SG_EBC2_Tx_2 1 : vVeh_EBC2_Tx_2;
SIG_GROUP_ 2566832056 AUTO_SG_EBC2_Tx_3 1 : vVeh_EBC2_Tx_3;
SIG_GROUP_ 2566832048 AUTO_SG_EBC2_Tx_4 1 : vVeh_EBC2_Tx_4;
SIG_GROUP_ 2566832040 AUTO_SG_EBC2_Tx_5 1 : vVeh_EBC2_Tx_5;
SIG_GROUP_ 2566832032 AUTO_SG_EBC2_Tx_6 1 : vVeh_EBC2_Tx_6;
SIG_GROUP_ 2566832024 AUTO_SG_EBC2_Tx_7 1 : vVeh_EBC2_Tx_7;
SIG_GROUP_ 2566832016 AUTO_SG_EBC2_Tx_8 1 : vVeh_EBC2_Tx_8;
SIG_GROUP_ 2566832008 AUTO_SG_EBC2_Tx_9 1 : vVeh_EBC2_Tx_9;
SIG_GROUP_ 2348992712 AUTO_SG_EBS11_Tx_TICAN 1 : VehABSAct_EBS11_Tx_TICAN VehRetCtrAct_EBS11_Tx_TICAN ASR_BC_Act ASR_EC_Act BrLightSw VehType_EBS11_Tx_TICAN VehVDCAct ServBrDem ParkBrDem_EBS11_Tx_TICAN RetDem RelDemFrontLeft RelDemRearRight;
SIG_GROUP_ 2348992704 AUTO_SG_EBS11_Tx_TICAN_2 1 : VehABSAct_EBS11_Tx_TICAN_2 VehRetCtrAct_EBS11_Tx_TICAN_2 ASR_BC_Act ASR_EC_Act BrLightSw VehType_EBS11_Tx_TICAN_2 VehVDCAct ServBrDem ParkBrDem_EBS11_Tx_TICAN_2 RetDem RelDemFrontLeft RelDemRearRight;
SIG_GROUP_ 2348992696 AUTO_SG_EBS11_Tx_TICAN_3 1 : VehABSAct_EBS11_Tx_TICAN_3 VehRetCtrAct_EBS11_Tx_TICAN_3 ASR_BC_Act ASR_EC_Act BrLightSw VehType_EBS11_Tx_TICAN_3 VehVDCAct ServBrDem ParkBrDem_EBS11_Tx_TICAN_3 RetDem RelDemFrontLeft RelDemRearRight;
SIG_GROUP_ 2348992688 AUTO_SG_EBS11_Tx_TICAN_4 1 : VehABSAct_EBS11_Tx_TICAN_4 VehRetCtrAct_EBS11_Tx_TICAN_4 ASR_BC_Act ASR_EC_Act BrLightSw VehType_EBS11_Tx_TICAN_4 VehVDCAct ServBrDem ParkBrDem_EBS11_Tx_TICAN_4 RetDem RelDemFrontLeft RelDemRearRight;
SIG_GROUP_ 2348992680 AUTO_SG_EBS11_Tx_TICAN_5 1 : VehABSAct_EBS11_Tx_TICAN_5 VehRetCtrAct_EBS11_Tx_TICAN_5 ASR_BC_Act ASR_EC_Act BrLightSw VehType_EBS11_Tx_TICAN_5 VehVDCAct ServBrDem ParkBrDem_EBS11_Tx_TICAN_5 RetDem RelDemFrontLeft RelDemRearRight;
SIG_GROUP_ 2566834632 AUTO_SG_EBS12_Tx_TICAN 1 : VehRetCtrAct_EBS12_Tx_TICAN VehROPEna VehYCEna TrlROPEna TrlYCEna RevGearSta EmrgBrkReq TwoElBrDem ABSOffrReq PneuCtrLine TractorLSF RoadCurve VehWhlSpeed;
SIG_GROUP_ 2566834624 AUTO_SG_EBS12_Tx_TICAN_2 1 : VehRetCtrAct_EBS12_Tx_TICAN_2 VehROPEna VehYCEna TrlROPEna TrlYCEna RevGearSta EmrgBrkReq TwoElBrDem ABSOffrReq PneuCtrLine TractorLSF RoadCurve VehWhlSpeed;
SIG_GROUP_ 2566834616 AUTO_SG_EBS12_Tx_TICAN_3 1 : VehRetCtrAct_EBS12_Tx_TICAN_3 VehROPEna VehYCEna TrlROPEna TrlYCEna RevGearSta EmrgBrkReq TwoElBrDem ABSOffrReq PneuCtrLine TractorLSF RoadCurve VehWhlSpeed;
SIG_GROUP_ 2566834608 AUTO_SG_EBS12_Tx_TICAN_4 1 : VehRetCtrAct_EBS12_Tx_TICAN_4 VehROPEna VehYCEna TrlROPEna TrlYCEna RevGearSta EmrgBrkReq TwoElBrDem ABSOffrReq PneuCtrLine TractorLSF RoadCurve VehWhlSpeed;
SIG_GROUP_ 2566834600 AUTO_SG_EBS12_Tx_TICAN_5 1 : VehRetCtrAct_EBS12_Tx_TICAN_5 VehROPEna VehYCEna TrlROPEna TrlYCEna RevGearSta EmrgBrkReq TwoElBrDem ABSOffrReq PneuCtrLine TractorLSF RoadCurve VehWhlSpeed;
SIG_GROUP_ 2349015240 AUTO_SG_EBS21_Tx_TICAN 1 : VehABSAct_EBS21_Tx_TICAN VehRetCtrAct_EBS21_Tx_TICAN ServBrAct_EBS21_Tx_TICAN AutoBrAct_EBS21_Tx_TICAN VDC_Act BrkDistrSupp v_WhBased PrcRetPeakTq WhSpeedDiff LatAcc;
SIG_GROUP_ 2349058240 AUTO_SG_EBS21_Tx_TICAN_2 1 : VehABSAct_EBS21_Tx_TICAN_2 VehRetCtrAct_EBS21_Tx_TICAN_2 ServBrAct_EBS21_Tx_TICAN_2 AutoBrAct_EBS21_Tx_TICAN_2 VDC_Act BrkDistrSupp v_WhBased PrcRetPeakTq WhSpeedDiff LatAcc;
SIG_GROUP_ 2349056184 AUTO_SG_EBS21_Tx_TICAN_3 1 : VehABSAct_EBS21_Tx_TICAN_3 VehRetCtrAct_EBS21_Tx_TICAN_3 ServBrAct_EBS21_Tx_TICAN_3 AutoBrAct_EBS21_Tx_TICAN_3 VDC_Act BrkDistrSupp v_WhBased PrcRetPeakTq WhSpeedDiff LatAcc;
SIG_GROUP_ 2349054128 AUTO_SG_EBS21_Tx_TICAN_4 1 : VehABSAct_EBS21_Tx_TICAN_4 VehRetCtrAct_EBS21_Tx_TICAN_4 ServBrAct_EBS21_Tx_TICAN_4 AutoBrAct_EBS21_Tx_TICAN_4 VDC_Act BrkDistrSupp v_WhBased PrcRetPeakTq WhSpeedDiff LatAcc;
SIG_GROUP_ 2349052072 AUTO_SG_EBS21_Tx_TICAN_5 1 : VehABSAct_EBS21_Tx_TICAN_5 VehRetCtrAct_EBS21_Tx_TICAN_5 ServBrAct_EBS21_Tx_TICAN_5 AutoBrAct_EBS21_Tx_TICAN_5 VDC_Act BrkDistrSupp v_WhBased PrcRetPeakTq WhSpeedDiff LatAcc;
SIG_GROUP_ 2566833352 AUTO_SG_EBS22_Tx_TICAN 1 : VehABSAct_EBS22_Tx_TICAN VehRetCtrAct_EBS22_Tx_TICAN ServBrAct_EBS22_Tx_TICAN AutoBrAct_EBS22_Tx_TICAN ElSupSuff RedWLReq AmbWLReq ElSupNoBrSys SpringBrInst ElLoadProp VehType_EBS22_Tx_TICAN SprBrEng LoadRampAss SupBrReq StopLampReq ElBrakeSupp AxLoadSum RefRetTrq;
SIG_GROUP_ 2566833344 AUTO_SG_EBS22_Tx_TICAN_2 1 : VehABSAct_EBS22_Tx_TICAN_2 VehRetCtrAct_EBS22_Tx_TICAN_2 ServBrAct_EBS22_Tx_TICAN_2 AutoBrAct_EBS22_Tx_TICAN_2 ElSupSuff RedWLReq AmbWLReq ElSupNoBrSys SpringBrInst ElLoadProp VehType_EBS22_Tx_TICAN_2 SprBrEng LoadRampAss SupBrReq StopLampReq ElBrakeSupp AxLoadSum RefRetTrq;
SIG_GROUP_ 2566833336 AUTO_SG_EBS22_Tx_TICAN_3 1 : VehABSAct_EBS22_Tx_TICAN_3 VehRetCtrAct_EBS22_Tx_TICAN_3 ServBrAct_EBS22_Tx_TICAN_3 AutoBrAct_EBS22_Tx_TICAN_3 ElSupSuff RedWLReq AmbWLReq ElSupNoBrSys SpringBrInst ElLoadProp VehType_EBS22_Tx_TICAN_3 SprBrEng LoadRampAss SupBrReq StopLampReq ElBrakeSupp AxLoadSum RefRetTrq;
SIG_GROUP_ 2566833328 AUTO_SG_EBS22_Tx_TICAN_4 1 : VehABSAct_EBS22_Tx_TICAN_4 VehRetCtrAct_EBS22_Tx_TICAN_4 ServBrAct_EBS22_Tx_TICAN_4 AutoBrAct_EBS22_Tx_TICAN_4 ElSupSuff RedWLReq AmbWLReq ElSupNoBrSys SpringBrInst ElLoadProp VehType_EBS22_Tx_TICAN_4 SprBrEng LoadRampAss SupBrReq StopLampReq ElBrakeSupp AxLoadSum RefRetTrq;
SIG_GROUP_ 2566833320 AUTO_SG_EBS22_Tx_TICAN_5 1 : VehABSAct_EBS22_Tx_TICAN_5 VehRetCtrAct_EBS22_Tx_TICAN_5 ServBrAct_EBS22_Tx_TICAN_5 AutoBrAct_EBS22_Tx_TICAN_5 ElSupSuff RedWLReq AmbWLReq ElSupNoBrSys SpringBrInst ElLoadProp VehType_EBS22_Tx_TICAN_5 SprBrEng LoadRampAss SupBrReq StopLampReq ElBrakeSupp AxLoadSum RefRetTrq;
SIG_GROUP_ 2566833864 AUTO_SG_EBS23_Tx_TICAN 1 : TyrePrSuf BrLinSuf BrTempSt PneuSupSuf TyreId_Press TyreId_Lining TyreId_Temp TyrePress BrLin BrTemp PneuSupPr;
SIG_GROUP_ 2566833856 AUTO_SG_EBS23_Tx_TICAN_2 1 : TyrePrSuf BrLinSuf BrTempSt PneuSupSuf TyreId_Press TyreId_Lining TyreId_Temp TyrePress BrLin BrTemp PneuSupPr;
SIG_GROUP_ 2566833848 AUTO_SG_EBS23_Tx_TICAN_3 1 : TyrePrSuf BrLinSuf BrTempSt PneuSupSuf TyreId_Press TyreId_Lining TyreId_Temp TyrePress BrLin BrTemp PneuSupPr;
SIG_GROUP_ 2566833840 AUTO_SG_EBS23_Tx_TICAN_4 1 : TyrePrSuf BrLinSuf BrTempSt PneuSupSuf TyreId_Press TyreId_Lining TyreId_Temp TyrePress BrLin BrTemp PneuSupPr;
SIG_GROUP_ 2566833832 AUTO_SG_EBS23_Tx_TICAN_5 1 : TyrePrSuf BrLinSuf BrTempSt PneuSupSuf TyreId_Press TyreId_Lining TyreId_Temp TyrePress BrLin BrTemp PneuSupPr;
SIG_GROUP_ 2566757064 AUTO_SG_EBS24_Tx_TICAN 1 : GeomDataIndex GeomDataContent;
SIG_GROUP_ 2566757056 AUTO_SG_EBS24_Tx_TICAN_2 1 : GeomDataIndex GeomDataContent;
SIG_GROUP_ 2566757048 AUTO_SG_EBS24_Tx_TICAN_3 1 : GeomDataIndex GeomDataContent;
SIG_GROUP_ 2566757040 AUTO_SG_EBS24_Tx_TICAN_4 1 : GeomDataIndex GeomDataContent;
SIG_GROUP_ 2566757032 AUTO_SG_EBS24_Tx_TICAN_5 1 : GeomDataIndex GeomDataContent;
SIG_GROUP_ 2565873864 AUTO_SG_EBS25_Tx_TICAN 1 : PBrCyl_A1L PBrCyl_A1R PBrCyl_A2L PBrCyl_A2R PBrCyl_A3L PBrCyl_A3R ROPEna YCEna;
SIG_GROUP_ 2565873856 AUTO_SG_EBS25_Tx_TICAN_2 1 : PBrCyl_A1L PBrCyl_A1R PBrCyl_A2L PBrCyl_A2R PBrCyl_A3L PBrCyl_A3R ROPEna YCEna;
SIG_GROUP_ 2565873848 AUTO_SG_EBS25_Tx_TICAN_3 1 : PBrCyl_A1L PBrCyl_A1R PBrCyl_A2L PBrCyl_A2R PBrCyl_A3L PBrCyl_A3R ROPEna YCEna;
SIG_GROUP_ 2565873840 AUTO_SG_EBS25_Tx_TICAN_4 1 : PBrCyl_A1L PBrCyl_A1R PBrCyl_A2L PBrCyl_A2R PBrCyl_A3L PBrCyl_A3R ROPEna YCEna;
SIG_GROUP_ 2565873832 AUTO_SG_EBS25_Tx_TICAN_5 1 : PBrCyl_A1L PBrCyl_A1R PBrCyl_A2L PBrCyl_A2R PBrCyl_A3L PBrCyl_A3R ROPEna YCEna;
SIG_GROUP_ 2364547016 AUTO_SG_EBS26_Tx_TICAN 1 : V_A1L V_A1R;
SIG_GROUP_ 2364547008 AUTO_SG_EBS26_Tx_TICAN_2 1 : V_A1L V_A1R;
SIG_GROUP_ 2364547000 AUTO_SG_EBS26_Tx_TICAN_3 1 : V_A1L V_A1R;
SIG_GROUP_ 2364546992 AUTO_SG_EBS26_Tx_TICAN_4 1 : V_A1L V_A1R;
SIG_GROUP_ 2364546984 AUTO_SG_EBS26_Tx_TICAN_5 1 : V_A1L V_A1R;
SIG_GROUP_ 2566857856 AUTO_SG_PGN65316_Tx_10 1 : vWhl4 vWhl5 BrAct ABSAct RSPAct Overload_PGN65316_Tx_10 PDem TrlWeight TiltAngle TAactive BodyLift_PGN65316_Tx_10;
SIG_GROUP_ 2566857920 AUTO_SG_PGN65316_Tx_2 1 : vWhl4 vWhl5 BrAct ABSAct RSPAct Overload_PGN65316_Tx_2 PDem TrlWeight TiltAngle TAactive BodyLift_PGN65316_Tx_2;
SIG_GROUP_ 2566857912 AUTO_SG_PGN65316_Tx_3 1 : vWhl4 vWhl5 BrAct ABSAct RSPAct Overload_PGN65316_Tx_3 PDem TrlWeight TiltAngle TAactive BodyLift_PGN65316_Tx_3;
SIG_GROUP_ 2566857904 AUTO_SG_PGN65316_Tx_4 1 : vWhl4 vWhl5 BrAct ABSAct RSPAct Overload_PGN65316_Tx_4 PDem TrlWeight TiltAngle TAactive BodyLift_PGN65316_Tx_4;
SIG_GROUP_ 2566857896 AUTO_SG_PGN65316_Tx_5 1 : vWhl4 vWhl5 BrAct ABSAct RSPAct Overload_PGN65316_Tx_5 PDem TrlWeight TiltAngle TAactive BodyLift_PGN65316_Tx_5;
SIG_GROUP_ 2566857888 AUTO_SG_PGN65316_Tx_6 1 : vWhl4 vWhl5 BrAct ABSAct RSPAct Overload_PGN65316_Tx_6 PDem TrlWeight TiltAngle TAactive BodyLift_PGN65316_Tx_6;
SIG_GROUP_ 2566857880 AUTO_SG_PGN65316_Tx_7 1 : vWhl4 vWhl5 BrAct ABSAct RSPAct Overload_PGN65316_Tx_7 PDem TrlWeight TiltAngle TAactive BodyLift_PGN65316_Tx_7;
SIG_GROUP_ 2566857872 AUTO_SG_PGN65316_Tx_8 1 : vWhl4 vWhl5 BrAct ABSAct RSPAct Overload_PGN65316_Tx_8 PDem TrlWeight TiltAngle TAactive BodyLift_PGN65316_Tx_8;
SIG_GROUP_ 2566857864 AUTO_SG_PGN65316_Tx_9 1 : vWhl4 vWhl5 BrAct ABSAct RSPAct Overload_PGN65316_Tx_9 PDem TrlWeight TiltAngle TAactive BodyLift_PGN65316_Tx_9;
SIG_GROUP_ 2566857984 AUTO_SG_PGN65317_Rx 1 : WLReq BrIntvEna BrDemJ1939;
SIG_GROUP_ 2565130440 AUTO_SG_RGE11_Tx_TICAN 1 : RideHeiReq_RGE11_Tx_TICAN LevChgReq_FA_RGE11_Tx_TICAN LevChgReq_RA_RGE11_Tx_TICAN TracHelpReq_RGE11_Tx_TICAN LiftAxPos1Req_RGE11_Tx_TICAN LiftAxPos2Req_RGE11_Tx_TICAN StrAxLockReq_RGE11_Tx_TICAN RampLevReq_RGE11_Tx_TICAN LevCtrReq_RGE11_Tx_TICAN RampLevStReq_RGE11_Tx_TICAN StopLevChReq_RGE11_Tx_TICAN DrvAxLoad_RGE11_Tx_TICAN ParkAirPress_RGE11_Tx_TICAN AuxSupPress_RGE11_Tx_TICAN;
SIG_GROUP_ 2565130432 AUTO_SG_RGE11_Tx_TICAN_2 1 : RideHeiReq_RGE11_Tx_TICAN LevChgReq_FA_RGE11_Tx_TICAN LevChgReq_RA_RGE11_Tx_TICAN TracHelpReq_RGE11_Tx_TICAN LiftAxPos1Req_RGE11_Tx_TICAN LiftAxPos2Req_RGE11_Tx_TICAN StrAxLockReq_RGE11_Tx_TICAN RampLevReq_RGE11_Tx_TICAN LevCtrReq_RGE11_Tx_TICAN RampLevStReq_RGE11_Tx_TICAN StopLevChReq_RGE11_Tx_TICAN DrvAxLoad_RGE11_Tx_TICAN ParkAirPress_RGE11_Tx_TICAN AuxSupPress_RGE11_Tx_TICAN;
SIG_GROUP_ 2565130424 AUTO_SG_RGE11_Tx_TICAN_3 1 : RideHeiReq_RGE11_Tx_TICAN LevChgReq_FA_RGE11_Tx_TICAN LevChgReq_RA_RGE11_Tx_TICAN TracHelpReq_RGE11_Tx_TICAN LiftAxPos1Req_RGE11_Tx_TICAN LiftAxPos2Req_RGE11_Tx_TICAN StrAxLockReq_RGE11_Tx_TICAN RampLevReq_RGE11_Tx_TICAN LevCtrReq_RGE11_Tx_TICAN RampLevStReq_RGE11_Tx_TICAN StopLevChReq_RGE11_Tx_TICAN DrvAxLoad_RGE11_Tx_TICAN ParkAirPress_RGE11_Tx_TICAN AuxSupPress_RGE11_Tx_TICAN;
SIG_GROUP_ 2565130416 AUTO_SG_RGE11_Tx_TICAN_4 1 : RideHeiReq_RGE11_Tx_TICAN LevChgReq_FA_RGE11_Tx_TICAN LevChgReq_RA_RGE11_Tx_TICAN TracHelpReq_RGE11_Tx_TICAN LiftAxPos1Req_RGE11_Tx_TICAN LiftAxPos2Req_RGE11_Tx_TICAN StrAxLockReq_RGE11_Tx_TICAN RampLevReq_RGE11_Tx_TICAN LevCtrReq_RGE11_Tx_TICAN RampLevStReq_RGE11_Tx_TICAN StopLevChReq_RGE11_Tx_TICAN DrvAxLoad_RGE11_Tx_TICAN ParkAirPress_RGE11_Tx_TICAN AuxSupPress_RGE11_Tx_TICAN;
SIG_GROUP_ 2565130408 AUTO_SG_RGE11_Tx_TICAN_5 1 : RideHeiReq_RGE11_Tx_TICAN LevChgReq_FA_RGE11_Tx_TICAN LevChgReq_RA_RGE11_Tx_TICAN TracHelpReq_RGE11_Tx_TICAN LiftAxPos1Req_RGE11_Tx_TICAN LiftAxPos2Req_RGE11_Tx_TICAN StrAxLockReq_RGE11_Tx_TICAN RampLevReq_RGE11_Tx_TICAN LevCtrReq_RGE11_Tx_TICAN RampLevStReq_RGE11_Tx_TICAN StopLevChReq_RGE11_Tx_TICAN DrvAxLoad_RGE11_Tx_TICAN ParkAirPress_RGE11_Tx_TICAN AuxSupPress_RGE11_Tx_TICAN;
SIG_GROUP_ 2559232200 AUTO_SG_RGE12_Tx_TICAN 1 : AxLCalDataStrReq_RGE12_TICAN_Tx WhlId_RGE12_TICAN_Tx AxLoadExtScale_RGE12_TICAN_Tx VINindex_RGE12_TICAN_Tx VINdata_RGE12_TICAN_Tx;
SIG_GROUP_ 2559232192 AUTO_SG_RGE12_Tx_TICAN_2 1 : AxLCalDataStrReq_RGE12_TICAN_Tx WhlId_RGE12_TICAN_Tx AxLoadExtScale_RGE12_TICAN_Tx VINindex_RGE12_TICAN_Tx VINdata_RGE12_TICAN_Tx;
SIG_GROUP_ 2559232184 AUTO_SG_RGE12_Tx_TICAN_3 1 : AxLCalDataStrReq_RGE12_TICAN_Tx WhlId_RGE12_TICAN_Tx AxLoadExtScale_RGE12_TICAN_Tx VINindex_RGE12_TICAN_Tx VINdata_RGE12_TICAN_Tx;
SIG_GROUP_ 2559232176 AUTO_SG_RGE12_Tx_TICAN_4 1 : AxLCalDataStrReq_RGE12_TICAN_Tx WhlId_RGE12_TICAN_Tx AxLoadExtScale_RGE12_TICAN_Tx VINindex_RGE12_TICAN_Tx VINdata_RGE12_TICAN_Tx;
SIG_GROUP_ 2559232168 AUTO_SG_RGE12_Tx_TICAN_5 1 : AxLCalDataStrReq_RGE12_TICAN_Tx WhlId_RGE12_TICAN_Tx AxLoadExtScale_RGE12_TICAN_Tx VINindex_RGE12_TICAN_Tx VINdata_RGE12_TICAN_Tx;
SIG_GROUP_ 2565152968 AUTO_SG_RGE21_Tx_TICAN 1 : RideHeiLevel LevelCtrl TracHelp_RGE21_Tx_TICAN RampLevPos LiftAxPos1 LiftAxPos2 StrAxLock RampLevSt LevChg_FA LevChg_RA StopAck NormLevel RampLevel BodyLevel_FA BodyLevel_RA;
SIG_GROUP_ 2565152960 AUTO_SG_RGE21_Tx_TICAN_2 1 : RideHeiLevel LevelCtrl TracHelp_RGE21_Tx_TICAN_2 RampLevPos LiftAxPos1 LiftAxPos2 StrAxLock RampLevSt LevChg_FA LevChg_RA StopAck NormLevel RampLevel BodyLevel_FA BodyLevel_RA;
SIG_GROUP_ 2565152952 AUTO_SG_RGE21_Tx_TICAN_3 1 : RideHeiLevel LevelCtrl TracHelp_RGE21_Tx_TICAN_3 RampLevPos LiftAxPos1 LiftAxPos2 StrAxLock RampLevSt LevChg_FA LevChg_RA StopAck NormLevel RampLevel BodyLevel_FA BodyLevel_RA;
SIG_GROUP_ 2565152944 AUTO_SG_RGE21_Tx_TICAN_4 1 : RideHeiLevel LevelCtrl TracHelp_RGE21_Tx_TICAN_4 RampLevPos LiftAxPos1 LiftAxPos2 StrAxLock RampLevSt LevChg_FA LevChg_RA StopAck NormLevel RampLevel BodyLevel_FA BodyLevel_RA;
SIG_GROUP_ 2565152936 AUTO_SG_RGE21_Tx_TICAN_5 1 : RideHeiLevel LevelCtrl TracHelp_RGE21_Tx_TICAN_5 RampLevPos LiftAxPos1 LiftAxPos2 StrAxLock RampLevSt LevChg_FA LevChg_RA StopAck NormLevel RampLevel BodyLevel_FA BodyLevel_RA;
SIG_GROUP_ 2566806728 AUTO_SG_RGE22_Tx_TICAN 1 : ReBodyLevFA ReBodyLevRA WheelAxleId AxleLoad;
SIG_GROUP_ 2566806720 AUTO_SG_RGE22_Tx_TICAN_2 1 : ReBodyLevFA ReBodyLevRA WheelAxleId AxleLoad;
SIG_GROUP_ 2566806712 AUTO_SG_RGE22_Tx_TICAN_3 1 : ReBodyLevFA ReBodyLevRA WheelAxleId AxleLoad;
SIG_GROUP_ 2566806704 AUTO_SG_RGE22_Tx_TICAN_4 1 : ReBodyLevFA ReBodyLevRA WheelAxleId AxleLoad;
SIG_GROUP_ 2566806696 AUTO_SG_RGE22_Tx_TICAN_5 1 : ReBodyLevFA ReBodyLevRA WheelAxleId AxleLoad;
SIG_GROUP_ 2566807240 AUTO_SG_RGE23_Tx_TICAN 1 : TyreId TyreTemp AirLeakDet TyrePrTrhDet TyrePowSup VINindex_RGE23_Tx_TICAN VINdata_RGE23_Tx_TICAN;
SIG_GROUP_ 2566807232 AUTO_SG_RGE23_Tx_TICAN_2 1 : TyreId TyreTemp AirLeakDet TyrePrTrhDet TyrePowSup VINindex_RGE23_Tx_TICAN_2 VINdata_RGE23_Tx_TICAN_2;
SIG_GROUP_ 2566807224 AUTO_SG_RGE23_Tx_TICAN_3 1 : TyreId TyreTemp AirLeakDet TyrePrTrhDet TyrePowSup VINindex_RGE23_Tx_TICAN_3 VINdata_RGE23_Tx_TICAN_3;
SIG_GROUP_ 2566807216 AUTO_SG_RGE23_Tx_TICAN_4 1 : TyreId TyreTemp AirLeakDet TyrePrTrhDet TyrePowSup VINindex_RGE23_Tx_TICAN_4 VINdata_RGE23_Tx_TICAN_4;
SIG_GROUP_ 2566807208 AUTO_SG_RGE23_Tx_TICAN_5 1 : TyreId TyreTemp AirLeakDet TyrePrTrhDet TyrePowSup VINindex_RGE23_Tx_TICAN_5 VINdata_RGE23_Tx_TICAN_5;
SIG_GROUP_ 2559123656 AUTO_SG_RGE24_Tx_TICAN 1 : TyreId AxLoadTowedVehicle AxLoadExtScale_RGE24 AxLCalDataLoadLvl AxLCalTyp AxLCalDataStr Year_RGE24 Month_RGE24;
SIG_GROUP_ 2559123648 AUTO_SG_RGE24_Tx_TICAN_2 1 : TyreId AxLoadTowedVehicle AxLoadExtScale_RGE24 AxLCalDataLoadLvl AxLCalTyp AxLCalDataStr Year_RGE24 Month_RGE24;
SIG_GROUP_ 2559123640 AUTO_SG_RGE24_Tx_TICAN_3 1 : TyreId AxLoadTowedVehicle AxLoadExtScale_RGE24 AxLCalDataLoadLvl AxLCalTyp AxLCalDataStr Year_RGE24 Month_RGE24;
SIG_GROUP_ 2559123632 AUTO_SG_RGE24_Tx_TICAN_4 1 : TyreId AxLoadTowedVehicle AxLoadExtScale_RGE24 AxLCalDataLoadLvl AxLCalTyp AxLCalDataStr Year_RGE24 Month_RGE24;
SIG_GROUP_ 2559123624 AUTO_SG_RGE24_Tx_TICAN_5 1 : TyreId AxLoadTowedVehicle AxLoadExtScale_RGE24 AxLCalDataLoadLvl AxLCalTyp AxLCalDataStr Year_RGE24 Month_RGE24;
SIG_GROUP_ 2565523456 AUTO_SG_ReqPGN_Rx 1 : ReqPGNLow ReqPGNMiddle ReqPGNHigh;
SIG_GROUP_ 2565521600 AUTO_SG_ReqPGN_Rx_1 1 : ReqPGNLow ReqPGNMiddle ReqPGNHigh;
SIG_GROUP_ 2565519544 AUTO_SG_ReqPGN_Rx_2 1 : ReqPGNLow ReqPGNMiddle ReqPGNHigh;
SIG_GROUP_ 2565517488 AUTO_SG_ReqPGN_Rx_3 1 : ReqPGNLow ReqPGNMiddle ReqPGNHigh;
SIG_GROUP_ 2565515432 AUTO_SG_ReqPGN_Rx_4 1 : ReqPGNLow ReqPGNMiddle ReqPGNHigh;
SIG_GROUP_ 2565513376 AUTO_SG_ReqPGN_Rx_5 1 : ReqPGNLow ReqPGNMiddle ReqPGNHigh;
SIG_GROUP_ 2565511320 AUTO_SG_ReqPGN_Rx_6 1 : ReqPGNLow ReqPGNMiddle ReqPGNHigh;
SIG_GROUP_ 2565509264 AUTO_SG_ReqPGN_Rx_7 1 : ReqPGNLow ReqPGNMiddle ReqPGNHigh;
SIG_GROUP_ 2565507208 AUTO_SG_ReqPGN_Rx_8 1 : ReqPGNLow ReqPGNMiddle ReqPGNHigh;
SIG_GROUP_ 2565505152 AUTO_SG_ReqPGN_Rx_9 1 : ReqPGNLow ReqPGNMiddle ReqPGNHigh;
SIG_GROUP_ 2565537536 AUTO_SG_ReqPGN_Rx_G 1 : ReqPGNLow ReqPGNMiddle ReqPGNHigh;
SIG_GROUP_ 2566832328 AUTO_SG_SERV_Tx 1 : ComponentId ServiceDist_SERV_Tx;
SIG_GROUP_ 2566832256 AUTO_SG_SERV_Tx_10 1 : ComponentId ServiceDist_SERV_Tx_10;
SIG_GROUP_ 2566832320 AUTO_SG_SERV_Tx_2 1 : ComponentId ServiceDist_SERV_Tx_2;
SIG_GROUP_ 2566832312 AUTO_SG_SERV_Tx_3 1 : ComponentId ServiceDist_SERV_Tx_3;
SIG_GROUP_ 2566832304 AUTO_SG_SERV_Tx_4 1 : ComponentId ServiceDist_SERV_Tx_4;
SIG_GROUP_ 2566832296 AUTO_SG_SERV_Tx_5 1 : ComponentId ServiceDist_SERV_Tx_5;
SIG_GROUP_ 2566832288 AUTO_SG_SERV_Tx_6 1 : ComponentId ServiceDist_SERV_Tx_6;
SIG_GROUP_ 2566832280 AUTO_SG_SERV_Tx_7 1 : ComponentId ServiceDist_SERV_Tx_7;
SIG_GROUP_ 2566832272 AUTO_SG_SERV_Tx_8 1 : ComponentId ServiceDist_SERV_Tx_8;
SIG_GROUP_ 2566832264 AUTO_SG_SERV_Tx_9 1 : ComponentId ServiceDist_SERV_Tx_9;
SIG_GROUP_ 2566841891 AUTO_SG_TD_Rx 1 : Seconds Minutes Hours Month Day Year LocalMinuteOffset LocalHourOffset;
SIG_GROUP_ 2566832584 AUTO_SG_VDHR_Tx 1 : ODO Trip;
SIG_GROUP_ 2566832512 AUTO_SG_VDHR_Tx_10 1 : ODO Trip;
SIG_GROUP_ 2566832576 AUTO_SG_VDHR_Tx_2 1 : ODO Trip;
SIG_GROUP_ 2566832568 AUTO_SG_VDHR_Tx_3 1 : ODO Trip;
SIG_GROUP_ 2566832560 AUTO_SG_VDHR_Tx_4 1 : ODO Trip;
SIG_GROUP_ 2566832552 AUTO_SG_VDHR_Tx_5 1 : ODO Trip;
SIG_GROUP_ 2566832544 AUTO_SG_VDHR_Tx_6 1 : ODO Trip;
SIG_GROUP_ 2566832536 AUTO_SG_VDHR_Tx_7 1 : ODO Trip;
SIG_GROUP_ 2566832528 AUTO_SG_VDHR_Tx_8 1 : ODO Trip;
SIG_GROUP_ 2566832520 AUTO_SG_VDHR_Tx_9 1 : ODO Trip;
SIG_GROUP_ 2566843080 AUTO_SG_VW_Tx 1 : TrlWeight_VW_Tx;
SIG_GROUP_ 2566843008 AUTO_SG_VW_Tx_10 1 : TrlWeight_VW_Tx_10;
SIG_GROUP_ 2566843072 AUTO_SG_VW_Tx_2 1 : TrlWeight_VW_Tx_2;
SIG_GROUP_ 2566843064 AUTO_SG_VW_Tx_3 1 : TrlWeight_VW_Tx_3;
SIG_GROUP_ 2566843056 AUTO_SG_VW_Tx_4 1 : TrlWeight_VW_Tx_4;
SIG_GROUP_ 2566843048 AUTO_SG_VW_Tx_5 1 : TrlWeight_VW_Tx_5;
SIG_GROUP_ 2566843040 AUTO_SG_VW_Tx_6 1 : TrlWeight_VW_Tx_6;
SIG_GROUP_ 2566843032 AUTO_SG_VW_Tx_7 1 : TrlWeight_VW_Tx_7;
SIG_GROUP_ 2566843024 AUTO_SG_VW_Tx_8 1 : TrlWeight_VW_Tx_8;
SIG_GROUP_ 2566843016 AUTO_SG_VW_Tx_9 1 : TrlWeight_VW_Tx_9;
